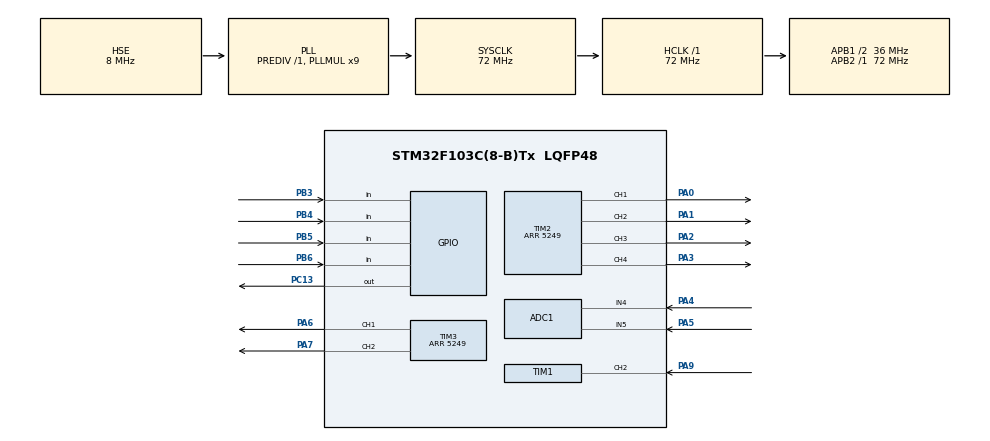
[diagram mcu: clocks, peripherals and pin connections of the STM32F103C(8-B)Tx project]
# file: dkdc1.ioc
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ADC1.Channel-0\#ChannelRegularConversion=ADC_CHANNEL_5
ADC1.NbrOfConversionFlag=1
ADC1.Rank-0\#ChannelRegularConversion=1
ADC1.SamplingTime-0\#ChannelRegularConversion=ADC_SAMPLETIME_55CYCLES_5
ADC1.master=1
Mcu.Family=STM32F1
Mcu.Name=STM32F103C(8-B)Tx
Mcu.Package=LQFP48
NVIC.PriorityGroup=NVIC_PRIORITYGROUP_4
NVIC.TIM3_IRQn=true\:0\:0\:false\:false\:true\:true\:true\:true
PA0-WKUP.Signal=S_TIM2_CH1_ETR
PA1.Signal=S_TIM2_CH2
PA13.Mode=Serial_Wire
PA13.Signal=SYS_JTMS-SWDIO
PA14.Mode=Serial_Wire
PA14.Signal=SYS_JTCK-SWCLK
PA2.Signal=S_TIM2_CH3
PA3.Signal=S_TIM2_CH4
PA4.Signal=ADCx_IN4
PA5.Signal=ADCx_IN5
PA6.Signal=S_TIM3_CH1
PA7.Signal=S_TIM3_CH2
PA9.Signal=S_TIM1_CH2
PB3.GPIO_PuPd=GPIO_PULLDOWN
PB3.Signal=GPIO_Input
PB4.GPIO_PuPd=GPIO_PULLDOWN
PB4.Signal=GPIO_Input
PB5.GPIO_PuPd=GPIO_PULLDOWN
PB5.Signal=GPIO_Input
PB6.GPIO_PuPd=GPIO_PULLDOWN
PB6.Signal=GPIO_Input
PC13-TAMPER-RTC.Signal=GPIO_Output
PD0-OSC_IN.Mode=HSE-External-Oscillator
PD0-OSC_IN.Signal=RCC_OSC_IN
PD1-OSC_OUT.Mode=HSE-External-Oscillator
PD1-OSC_OUT.Signal=RCC_OSC_OUT
ProjectManager.HeapSize=0x200
ProjectManager.StackSize=0x400
ProjectManager.TargetToolchain=MDK-ARM V5.32
RCC.ADCPresc=RCC_ADCPCLK2_DIV6
RCC.AHBFreq_Value=72000000
RCC.APB1CLKDivider=RCC_HCLK_DIV2
RCC.APB1Freq_Value=36000000
RCC.APB1TimFreq_Value=72000000
RCC.APB2Freq_Value=72000000
RCC.APB2TimFreq_Value=72000000
RCC.HCLKFreq_Value=72000000
RCC.PLLMUL=RCC_PLL_MUL9
RCC.PLLSourceVirtual=RCC_PLLSOURCE_HSE
RCC.SYSCLKFreq_VALUE=72000000
RCC.SYSCLKSource=RCC_SYSCLKSOURCE_PLLCLK
RCC.USBFreq_Value=72000000
SH.ADCx_IN4.0=ADC1_IN4,IN4
SH.ADCx_IN5.0=ADC1_IN5,IN5
SH.S_TIM1_CH2.0=TIM1_CH2,Input_Capture2_from_TI2
SH.S_TIM2_CH1_ETR.0=TIM2_CH1,PWM Generation1 CH1
SH.S_TIM2_CH2.0=TIM2_CH2,PWM Generation2 CH2
SH.S_TIM2_CH3.0=TIM2_CH3,PWM Generation3 CH3
SH.S_TIM2_CH4.0=TIM2_CH4,PWM Generation4 CH4
SH.S_TIM3_CH1.0=TIM3_CH1,PWM Generation1 CH1
SH.S_TIM3_CH2.0=TIM3_CH2,PWM Generation2 CH2
TIM1.Channel-Input_Capture2_from_TI2=TIM_CHANNEL_2
TIM1.Channel-PWM\ Generation1\ No\ Output=TIM_CHANNEL_1
TIM1.CounterMode=TIM_COUNTERMODE_CENTERALIGNED2
TIM1.Period=5249
TIM2.AutoReloadPreload=TIM_AUTORELOAD_PRELOAD_ENABLE
TIM2.Channel-PWM\ Generation1\ CH1=TIM_CHANNEL_1
TIM2.Channel-PWM\ Generation2\ CH2=TIM_CHANNEL_2
TIM2.Channel-PWM\ Generation3\ CH3=TIM_CHANNEL_3
TIM2.Channel-PWM\ Generation4\ CH4=TIM_CHANNEL_4
TIM2.CounterMode=TIM_COUNTERMODE_CENTERALIGNED1
TIM2.OCMode_PWM-PWM\ Generation2\ CH2=TIM_OCMODE_PWM2
TIM2.OCMode_PWM-PWM\ Generation4\ CH4=TIM_OCMODE_PWM2
TIM2.Period=5249
TIM2.TIM_MasterSlaveMode=TIM_MASTERSLAVEMODE_DISABLE
TIM3.AutoReloadPreload=TIM_AUTORELOAD_PRELOAD_ENABLE
TIM3.Channel-PWM\ Generation1\ CH1=TIM_CHANNEL_1
TIM3.Channel-PWM\ Generation2\ CH2=TIM_CHANNEL_2
TIM3.CounterMode=TIM_COUNTERMODE_CENTERALIGNED1
TIM3.OCMode_PWM-PWM\ Generation1\ CH1=TIM_OCMODE_PWM1
TIM3.OCMode_PWM-PWM\ Generation2\ CH2=TIM_OCMODE_PWM2
TIM3.Period=5249
VP_TIM1_VS_ClockSourceINT.Mode=Internal
VP_TIM1_VS_no_output1.Mode=PWM Generation1 No Output
VP_TIM2_VS_ClockSourceITR.Mode=TriggerSource_ITR0
VP_TIM2_VS_ControllerModeTrigger.Mode=Trigger Mode
VP_TIM3_VS_ClockSourceITR.Mode=TriggerSource_ITR0
VP_TIM3_VS_ControllerModeTrigger.Mode=Trigger Mode
board=custom

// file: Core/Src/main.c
/* USER CODE BEGIN Header */
/**
  ******************************************************************************
  * @file           : main.c
  * @brief          : Main program body
  ******************************************************************************
  * @attention
  *
  * Copyright (c) 2025 STMicroelectronics.
  * All rights reserved.
  *
  * This software is licensed under terms that can be found in the LICENSE file
  * in the root directory of this software component.
  * If no LICENSE file comes with this software, it is provided AS-IS.
  *
  ******************************************************************************
  */
/* USER CODE END Header */
#include "main.h"

ADC_HandleTypeDef hadc1;

TIM_HandleTypeDef htim1;
TIM_HandleTypeDef htim2;
TIM_HandleTypeDef htim3;

/* USER CODE BEGIN PV */
//#define GIATRI 1600
//#define FM 16000 // 8000x2
/* USER CODE END PV */

void SystemClock_Config(void);
static void MX_GPIO_Init(void);
static void MX_ADC1_Init(void);
static void MX_TIM2_Init(void);
static void MX_TIM3_Init(void);
static void MX_TIM1_Init(void);

/* USER CODE BEGIN 0 */
volatile uint16_t numberS=0;

uint16_t i0=0,a=0,b=0,c=0,d=0;
uint16_t seclect, check_adc, luuadc, step;
uint16_t ADC_Sensor;
uint16_t zero3200[3200] = {0, 0, 0, 0, 0, 0, 0, 0, 0, 0, 0, 0, 0, 0, 0, 0, 0, 0, 0, 0,
0, 0, 0, 0, 0, 0, 0, 0, 0, 0, 0, 0, 0, 0, 0, 0, 0, 0, 0, 0,
0, 0, 0, 0, 0, 0, 0, 0, 0, 0, 0, 0, 0, 0, 0, 0, 0, 0, 0, 0,
0, 0, 0, 0, 0, 0, 0, 0, 0, 0, 0, 0, 0, 0, 0, 0, 0, 0, 0, 0,
0, 0, 0, 0, 0, 0, 0, 0, 0, 0, 0, 0, 0, 0, 0, 0, 0, 0, 0, 0,
0, 0, 0, 0, 0, 0, 0, 0, 0, 0, 0, 0, 0, 0, 0, 0, 0, 0, 0, 0,
0, 0, 0, 0, 0, 0, 0, 0, 0, 0, 0, 0, 0, 0, 0, 0, 0, 0, 0, 0,
0, 0, 0, 0, 0, 0, 0, 0, 0, 0, 0, 0, 0, 0, 0, 0, 0, 0, 0, 0,
0, 0, 0, 0, 0, 0, 0, 0, 0, 0, 0, 0, 0, 0, 0, 0, 0, 0, 0, 0,
0, 0, 0, 0, 0, 0, 0, 0, 0, 0, 0, 0, 0, 0, 0, 0, 0, 0, 0, 0,
0, 0, 0, 0, 0, 0, 0, 0, 0, 0, 0, 0, 0, 0, 0, 0, 0, 0, 0, 0,
0, 0, 0, 0, 0, 0, 0, 0, 0, 0, 0, 0, 0, 0, 0, 0, 0, 0, 0, 0,
0, 0, 0, 0, 0, 0, 0, 0, 0, 0, 0, 0, 0, 0, 0, 0, 0, 0, 0, 0,
0, 0, 0, 0, 0, 0, 0, 0, 0, 0, 0, 0, 0, 0, 0, 0, 0, 0, 0, 0,
0, 0, 0, 0, 0, 0, 0, 0, 0, 0, 0, 0, 0, 0, 0, 0, 0, 0, 0, 0,
0, 0, 0, 0, 0, 0, 0, 0, 0, 0, 0, 0, 0, 0, 0, 0, 0, 0, 0, 0, 0, 0, 0, 0, 0, 0, 0, 0, 0, 0, 0, 0, 0, 0, 0, 0, 0, 0, 0, 0,
0, 0, 0, 0, 0, 0, 0, 0, 0, 0, 0, 0, 0, 0, 0, 0, 0, 0, 0, 0,
0, 0, 0, 0, 0, 0, 0, 0, 0, 0, 0, 0, 0, 0, 0, 0, 0, 0, 0, 0,
0, 0, 0, 0, 0, 0, 0, 0, 0, 0, 0, 0, 0, 0, 0, 0, 0, 0, 0, 0,
0, 0, 0, 0, 0, 0, 0, 0, 0, 0, 0, 0, 0, 0, 0, 0, 0, 0, 0, 0,
0, 0, 0, 0, 0, 0, 0, 0, 0, 0, 0, 0, 0, 0, 0, 0, 0, 0, 0, 0,
0, 0, 0, 0, 0, 0, 0, 0, 0, 0, 0, 0, 0, 0, 0, 0, 0, 0, 0, 0,
0, 0, 0, 0, 0, 0, 0, 0, 0, 0, 0, 0, 0, 0, 0, 0, 0, 0, 0, 0,
0, 0, 0, 0, 0, 0, 0, 0, 0, 0, 0, 0, 0, 0, 0, 0, 0, 0, 0, 0,
0, 0, 0, 0, 0, 0, 0, 0, 0, 0, 0, 0, 0, 0, 0, 0, 0, 0, 0, 0,
0, 0, 0, 0, 0, 0, 0, 0, 0, 0, 0, 0, 0, 0, 0, 0, 0, 0, 0, 0,
0, 0, 0, 0, 0, 0, 0, 0, 0, 0, 0, 0, 0, 0, 0, 0, 0, 0, 0, 0,
0, 0, 0, 0, 0, 0, 0, 0, 0, 0, 0, 0, 0, 0, 0, 0, 0, 0, 0, 0,
0, 0, 0, 0, 0, 0, 0, 0, 0, 0, 0, 0, 0, 0, 0, 0, 0, 0, 0, 0,
0, 0, 0, 0, 0, 0, 0, 0, 0, 0, 0, 0, 0, 0, 0, 0, 0, 0, 0, 0,
0, 0, 0, 0, 0, 0, 0, 0, 0, 0, 0, 0, 0, 0, 0, 0, 0, 0, 0, 0,
0, 0, 0, 0, 0, 0, 0, 0, 0, 0, 0, 0, 0, 0, 0, 0, 0, 0, 0, 0,
0, 0, 0, 0, 0, 0, 0, 0, 0, 0, 0, 0, 0, 0, 0, 0, 0, 0, 0, 0,
0, 0, 0, 0, 0, 0, 0, 0, 0, 0, 0, 0, 0, 0, 0, 0, 0, 0, 0, 0,
0, 0, 0, 0, 0, 0, 0, 0, 0, 0, 0, 0, 0, 0, 0, 0, 0, 0, 0, 0,
0, 0, 0, 0, 0, 0, 0, 0, 0, 0, 0, 0, 0, 0, 0, 0, 0, 0, 0, 0,
0, 0, 0, 0, 0, 0, 0, 0, 0, 0, 0, 0, 0, 0, 0, 0, 0, 0, 0, 0,
0, 0, 0, 0, 0, 0, 0, 0, 0, 0, 0, 0, 0, 0, 0, 0, 0, 0, 0, 0,
0, 0, 0, 0, 0, 0, 0, 0, 0, 0, 0, 0, 0, 0, 0, 0, 0, 0, 0, 0,
0, 0, 0, 0, 0, 0, 0, 0, 0, 0, 0, 0, 0, 0, 0, 0, 0, 0, 0, 0,
0, 0, 0, 0, 0, 0, 0, 0, 0, 0, 0, 0, 0, 0, 0, 0, 0, 0, 0, 0,
0, 0, 0, 0, 0, 0, 0, 0, 0, 0, 0, 0, 0, 0, 0, 0, 0, 0, 0, 0,
0, 0, 0, 0, 0, 0, 0, 0, 0, 0, 0, 0, 0, 0, 0, 0, 0, 0, 0, 0,
0, 0, 0, 0, 0, 0, 0, 0, 0, 0, 0, 0, 0, 0, 0, 0, 0, 0, 0, 0,
0, 0, 0, 0, 0, 0, 0, 0, 0, 0, 0, 0, 0, 0, 0, 0, 0, 0, 0, 0,
0, 0, 0, 0, 0, 0, 0, 0, 0, 0, 0, 0, 0, 0, 0, 0, 0, 0, 0, 0,
0, 0, 0, 0, 0, 0, 0, 0, 0, 0, 0, 0, 0, 0, 0, 0, 0, 0, 0, 0, 0, 0, 0, 0, 0, 0, 0, 0, 0, 0, 0, 0, 0, 0, 0, 0, 0, 0, 0, 0,
0, 0, 0, 0, 0, 0, 0, 0, 0, 0, 0, 0, 0, 0, 0, 0, 0, 0, 0, 0,
0, 0, 0, 0, 0, 0, 0, 0, 0, 0, 0, 0, 0, 0, 0, 0, 0, 0, 0, 0,
0, 0, 0, 0, 0, 0, 0, 0, 0, 0, 0, 0, 0, 0, 0, 0, 0, 0, 0, 0,
0, 0, 0, 0, 0, 0, 0, 0, 0, 0, 0, 0, 0, 0, 0, 0, 0, 0, 0, 0,
0, 0, 0, 0, 0, 0, 0, 0, 0, 0, 0, 0, 0, 0, 0, 0, 0, 0, 0, 0,
0, 0, 0, 0, 0, 0, 0, 0, 0, 0, 0, 0, 0, 0, 0, 0, 0, 0, 0, 0,
0, 0, 0, 0, 0, 0, 0, 0, 0, 0, 0, 0, 0, 0, 0, 0, 0, 0, 0, 0,
0, 0, 0, 0, 0, 0, 0, 0, 0, 0, 0, 0, 0, 0, 0, 0, 0, 0, 0, 0,
0, 0, 0, 0, 0, 0, 0, 0, 0, 0, 0, 0, 0, 0, 0, 0, 0, 0, 0, 0,
0, 0, 0, 0, 0, 0, 0, 0, 0, 0, 0, 0, 0, 0, 0, 0, 0, 0, 0, 0,
0, 0, 0, 0, 0, 0, 0, 0, 0, 0, 0, 0, 0, 0, 0, 0, 0, 0, 0, 0,
0, 0, 0, 0, 0, 0, 0, 0, 0, 0, 0, 0, 0, 0, 0, 0, 0, 0, 0, 0,
0, 0, 0, 0, 0, 0, 0, 0, 0, 0, 0, 0, 0, 0, 0, 0, 0, 0, 0, 0,
0, 0, 0, 0, 0, 0, 0, 0, 0, 0, 0, 0, 0, 0, 0, 0, 0, 0, 0, 0,
0, 0, 0, 0, 0, 0, 0, 0, 0, 0, 0, 0, 0, 0, 0, 0, 0, 0, 0, 0,
0, 0, 0, 0, 0, 0, 0, 0, 0, 0, 0, 0, 0, 0, 0, 0, 0, 0, 0, 0,
0, 0, 0, 0, 0, 0, 0, 0, 0, 0, 0, 0, 0, 0, 0, 0, 0, 0, 0, 0,
0, 0, 0, 0, 0, 0, 0, 0, 0, 0, 0, 0, 0, 0, 0, 0, 0, 0, 0, 0,
0, 0, 0, 0, 0, 0, 0, 0, 0, 0, 0, 0, 0, 0, 0, 0, 0, 0, 0, 0,
0, 0, 0, 0, 0, 0, 0, 0, 0, 0, 0, 0, 0, 0, 0, 0, 0, 0, 0, 0,
0, 0, 0, 0, 0, 0, 0, 0, 0, 0, 0, 0, 0, 0, 0, 0, 0, 0, 0, 0,
0, 0, 0, 0, 0, 0, 0, 0, 0, 0, 0, 0, 0, 0, 0, 0, 0, 0, 0, 0,
0, 0, 0, 0, 0, 0, 0, 0, 0, 0, 0, 0, 0, 0, 0, 0, 0, 0, 0, 0,
0, 0, 0, 0, 0, 0, 0, 0, 0, 0, 0, 0, 0, 0, 0, 0, 0, 0, 0, 0,
0, 0, 0, 0, 0, 0, 0, 0, 0, 0, 0, 0, 0, 0, 0, 0, 0, 0, 0, 0,
0, 0, 0, 0, 0, 0, 0, 0, 0, 0, 0, 0, 0, 0, 0, 0, 0, 0, 0, 0,
0, 0, 0, 0, 0, 0, 0, 0, 0, 0, 0, 0, 0, 0, 0, 0, 0, 0, 0, 0,
0, 0, 0, 0, 0, 0, 0, 0, 0, 0, 0, 0, 0, 0, 0, 0, 0, 0, 0, 0,
0, 0, 0, 0, 0, 0, 0, 0, 0, 0, 0, 0, 0, 0, 0, 0, 0, 0, 0, 0,
0, 0, 0, 0, 0, 0, 0, 0, 0, 0, 0, 0, 0, 0, 0, 0, 0, 0, 0, 0,
0, 0, 0, 0, 0, 0, 0, 0, 0, 0, 0, 0, 0, 0, 0, 0, 0, 0, 0,
0, 0, 0, 0, 0, 0, 0, 0, 0, 0, 0, 0, 0, 0, 0, 0, 0, 0, 0, 0,
0, 0, 0, 0, 0, 0, 0, 0, 0, 0, 0, 0, 0, 0, 0, 0, 0, 0, 0, 0,
0, 0, 0, 0, 0, 0, 0, 0, 0, 0, 0, 0, 0, 0, 0, 0, 0, 0, 0, 0,
0, 0, 0, 0, 0, 0, 0, 0, 0, 0, 0, 0, 0, 0, 0, 0, 0, 0, 0, 0,
0, 0, 0, 0, 0, 0, 0, 0, 0, 0, 0, 0, 0, 0, 0, 0, 0, 0, 0, 0,
0, 0, 0, 0, 0, 0, 0, 0, 0, 0, 0, 0, 0, 0, 0, 0, 0, 0, 0, 0,
0, 0, 0, 0, 0, 0, 0, 0, 0, 0, 0, 0, 0, 0, 0, 0, 0, 0, 0, 0,
0, 0, 0, 0, 0, 0, 0, 0, 0, 0, 0, 0, 0, 0, 0, 0, 0, 0, 0, 0,
0, 0, 0, 0, 0, 0, 0, 0, 0, 0, 0, 0, 0, 0, 0, 0, 0, 0, 0, 0,
0, 0, 0, 0, 0, 0, 0, 0, 0, 0, 0, 0, 0, 0, 0, 0, 0, 0, 0, 0,
0, 0, 0, 0, 0, 0, 0, 0, 0, 0, 0, 0, 0, 0, 0, 0, 0, 0, 0, 0,
0, 0, 0, 0, 0, 0, 0, 0, 0, 0, 0, 0, 0, 0, 0, 0, 0, 0, 0, 0,
0, 0, 0, 0, 0, 0, 0, 0, 0, 0, 0, 0, 0, 0, 0, 0, 0, 0, 0, 0,
0, 0, 0, 0, 0, 0, 0, 0, 0, 0, 0, 0, 0, 0, 0, 0, 0, 0, 0, 0,
0, 0, 0, 0, 0, 0, 0, 0, 0, 0, 0, 0, 0, 0, 0, 0, 0, 0, 0, 0,
0, 0, 0, 0, 0, 0, 0, 0, 0, 0, 0, 0, 0, 0, 0, 0, 0, 0, 0, 0, 0, 0, 0, 0, 0, 0, 0, 0, 0, 0, 0, 0, 0, 0, 0, 0, 0, 0, 0, 0,
0, 0, 0, 0, 0, 0, 0, 0, 0, 0, 0, 0, 0, 0, 0, 0, 0, 0, 0, 0,
0, 0, 0, 0, 0, 0, 0, 0, 0, 0, 0, 0, 0, 0, 0, 0, 0, 0, 0, 0,
0, 0, 0, 0, 0, 0, 0, 0, 0, 0, 0, 0, 0, 0, 0, 0, 0, 0, 0, 0,
0, 0, 0, 0, 0, 0, 0, 0, 0, 0, 0, 0, 0, 0, 0, 0, 0, 0, 0, 0,
0, 0, 0, 0, 0, 0, 0, 0, 0, 0, 0, 0, 0, 0, 0, 0, 0, 0, 0, 0,
0, 0, 0, 0, 0, 0, 0, 0, 0, 0, 0, 0, 0, 0, 0, 0, 0, 0, 0, 0,
0, 0, 0, 0, 0, 0, 0, 0, 0, 0, 0, 0, 0, 0, 0, 0, 0, 0, 0, 0,
0, 0, 0, 0, 0, 0, 0, 0, 0, 0, 0, 0, 0, 0, 0, 0, 0, 0, 0, 0,
0, 0, 0, 0, 0, 0, 0, 0, 0, 0, 0, 0, 0, 0, 0, 0, 0, 0, 0, 0,
0, 0, 0, 0, 0, 0, 0, 0, 0, 0, 0, 0, 0, 0, 0, 0, 0, 0, 0, 0,
0, 0, 0, 0, 0, 0, 0, 0, 0, 0, 0, 0, 0, 0, 0, 0, 0, 0, 0, 0,
0, 0, 0, 0, 0, 0, 0, 0, 0, 0, 0, 0, 0, 0, 0, 0, 0, 0, 0, 0,
0, 0, 0, 0, 0, 0, 0, 0, 0, 0, 0, 0, 0, 0, 0, 0, 0, 0, 0, 0,
0, 0, 0, 0, 0, 0, 0, 0, 0, 0, 0, 0, 0, 0, 0, 0, 0, 0, 0, 0,
0, 0, 0, 0, 0, 0, 0, 0, 0, 0, 0, 0, 0, 0, 0, 0, 0, 0, 0, 0,
0, 0, 0, 0, 0, 0, 0, 0, 0, 0, 0, 0, 0, 0, 0, 0, 0, 0, 0, 0,
0, 0, 0, 0, 0, 0, 0, 0, 0, 0, 0, 0, 0, 0, 0, 0, 0, 0, 0, 0,
0, 0, 0, 0, 0, 0, 0, 0, 0, 0, 0, 0, 0, 0, 0, 0, 0, 0, 0, 0,
0, 0, 0, 0, 0, 0, 0, 0, 0, 0, 0, 0, 0, 0, 0, 0, 0, 0, 0, 0,
0, 0, 0, 0, 0, 0, 0, 0, 0, 0, 0, 0, 0, 0, 0, 0, 0, 0, 0, 0,
0, 0, 0, 0, 0, 0, 0, 0, 0, 0, 0, 0, 0, 0, 0, 0, 0, 0, 0, 0,
0, 0, 0, 0, 0, 0, 0, 0, 0, 0, 0, 0, 0, 0, 0, 0, 0, 0, 0, 0,
0, 0, 0, 0, 0, 0, 0, 0, 0, 0, 0, 0, 0, 0, 0, 0, 0, 0, 0, 0,
0, 0, 0, 0, 0, 0, 0, 0, 0, 0, 0, 0, 0, 0, 0, 0, 0, 0, 0, 0,
0, 0, 0, 0, 0, 0, 0, 0, 0, 0, 0, 0, 0, 0, 0, 0, 0, 0, 0, 0,
0, 0, 0, 0, 0, 0, 0, 0, 0, 0, 0, 0, 0, 0, 0, 0, 0, 0, 0, 0,
0, 0, 0, 0, 0, 0, 0, 0, 0, 0, 0, 0, 0, 0, 0, 0, 0, 0, 0, 0,
0, 0, 0, 0, 0, 0, 0, 0, 0, 0, 0, 0, 0, 0, 0, 0, 0, 0, 0, 0,
0, 0, 0, 0, 0, 0, 0, 0, 0, 0, 0, 0, 0, 0, 0, 0, 0, 0, 0, 0,
0, 0, 0, 0, 0, 0, 0, 0, 0, 0, 0, 0, 0, 0, 0, 0, 0, 0, 0, 0,
0, 0, 0, 0, 0, 0, 0, 0, 0, 0, 0, 0, 0, 0, 0, 0, 0, 0, 0, 0, 0, 0, 0, 0, 0, 0, 0, 0, 0, 0, 0, 0, 0, 0, 0, 0, 0, 0, 0, 0,
0, 0, 0, 0, 0, 0, 0, 0, 0, 0, 0, 0, 0, 0, 0, 0, 0, 0, 0, 0,
0, 0, 0, 0, 0, 0, 0, 0, 0, 0, 0, 0, 0, 0, 0, 0, 0, 0, 0, 0,
0, 0, 0, 0, 0, 0, 0, 0, 0, 0, 0, 0, 0, 0, 0, 0, 0, 0, 0, 0,
0, 0, 0, 0, 0, 0, 0, 0, 0, 0, 0, 0, 0, 0, 0, 0, 0, 0, 0, 0,
0, 0, 0, 0, 0, 0, 0, 0, 0, 0, 0, 0, 0, 0, 0, 0, 0, 0, 0, 0,
0, 0, 0, 0, 0, 0, 0, 0, 0, 0, 0, 0, 0, 0, 0, 0, 0, 0, 0, 0,
0, 0, 0, 0, 0, 0, 0, 0, 0, 0, 0, 0, 0, 0, 0, 0, 0, 0, 0, 0,
0, 0, 0, 0, 0, 0, 0, 0, 0, 0, 0, 0, 0, 0, 0, 0, 0, 0, 0, 0,
0, 0, 0, 0, 0, 0, 0, 0, 0, 0, 0, 0, 0, 0, 0, 0, 0, 0, 0, 0,
0, 0, 0, 0, 0, 0, 0, 0, 0, 0, 0, 0, 0, 0, 0, 0, 0, 0, 0, 0,
0, 0, 0, 0, 0, 0, 0, 0, 0, 0, 0, 0, 0, 0, 0, 0, 0, 0, 0, 0,
0, 0, 0, 0, 0, 0, 0, 0, 0, 0, 0, 0, 0, 0, 0, 0, 0, 0, 0, 0,
0, 0, 0, 0, 0, 0, 0, 0, 0, 0, 0, 0, 0, 0, 0, 0, 0, 0, 0, 0,
0, 0, 0, 0, 0, 0, 0, 0, 0, 0, 0, 0, 0, 0, 0, 0, 0, 0, 0, 0,
0, 0, 0, 0, 0, 0, 0, 0, 0, 0, 0, 0, 0, 0, 0, 0, 0, 0, 0, 0,
0, 0, 0, 0, 0, 0, 0, 0, 0, 0, 0, 0, 0, 0, 0, 0, 0, 0, 0, 0,
0, 0, 0, 0, 0, 0, 0, 0, 0, 0, 0, 0, 0, 0, 0, 0, 0, 0, 0, 0,
0, 0, 0, 0, 0, 0, 0, 0, 0, 0, 0, 0, 0, 0, 0, 0, 0, 0, 0, 0,
0, 0, 0, 0, 0, 0, 0, 0, 0, 0, 0, 0, 0, 0, 0, 0, 0, 0, 0, 0,
0, 0, 0, 0, 0, 0, 0, 0, 0, 0, 0, 0, 0, 0, 0, 0, 0, 0, 0, 0,
0, 0, 0, 0, 0, 0, 0, 0, 0, 0, 0, 0, 0, 0, 0, 0, 0, 0, 0, 0,
0, 0, 0, 0, 0, 0, 0, 0, 0, 0, 0, 0, 0, 0, 0, 0, 0, 0, 0, 0,
0, 0, 0, 0, 0, 0, 0, 0, 0, 0, 0, 0, 0, 0, 0, 0, 0, 0, 0, 0,
0, 0, 0, 0, 0, 0, 0, 0, 0, 0, 0, 0, 0, 0, 0, 0, 0, 0, 0, 0,
0, 0, 0, 0, 0, 0, 0, 0, 0, 0, 0, 0, 0, 0, 0, 0, 0, 0, 0, 0,
0, 0, 0, 0, 0, 0, 0, 0, 0, 0, 0, 0, 0, 0, 0, 0, 0, 0, 0, 0,
0, 0, 0, 0, 0, 0, 0, 0, 0, 0, 0, 0, 0, 0, 0, 0, 0, 0, 0, 0,
0, 0, 0, 0, 0, 0, 0, 0, 0, 0, 0, 0, 0, 0, 0, 0, 0, 0, 0, 0,
0, 0, 0, 0, 0, 0, 0, 0, 0, 0, 0, 0, 0, 0, 0, 0, 0, 0, 0, 0,
0, 0, 0, 0, 0, 0, 0, 0, 0, 0, 0, 0, 0, 0, 0, 0, 0, 0, 0, 0,
0, 0, 0, 0, 0, 0, 0, 0, 0, 0, 0, 0, 0, 0, 0, 0, 0, 0, 0, 0};

const uint16_t bangX1_5Hz[3200]={0, 9, 18, 27, 35, 44, 53, 62, 71, 80, 88, 97, 106, 115, 124, 133, 141, 150, 159, 168,
177, 186, 194, 203, 212, 221, 230, 239, 247, 256, 265, 274, 283, 291, 300, 309, 318, 327, 336, 344,
353, 362, 371, 380, 388, 397, 406, 415, 424, 432, 441, 450, 459, 468, 476, 485, 494, 503, 512, 520,
529, 538, 547, 555, 564, 573, 582, 590, 599, 608, 617, 626, 634, 643, 652, 660, 669, 678, 687, 695,
704, 713, 722, 730, 739, 748, 757, 765, 774, 783, 791, 800, 809, 817, 826, 835, 843, 852, 861, 870,
878, 887, 896, 904, 913, 921, 930, 939, 947, 956, 965, 973, 982, 991, 999, 1008, 1016, 1025, 1034, 1042,
1051, 1059, 1068, 1077, 1085, 1094, 1102, 1111, 1119, 1128, 1137, 1145, 1154, 1162, 1171, 1179, 1188, 1196, 1205, 1213,
1222, 1230, 1239, 1247, 1256, 1264, 1273, 1281, 1290, 1298, 1307, 1315, 1324, 1332, 1340, 1349, 1357, 1366, 1374, 1383,
1391, 1399, 1408, 1416, 1425, 1433, 1441, 1450, 1458, 1466, 1475, 1483, 1491, 1500, 1508, 1516, 1525, 1533, 1541, 1550,
1558, 1566, 1575, 1583, 1591, 1599, 1608, 1616, 1624, 1632, 1641, 1649, 1657, 1665, 1673, 1682, 1690, 1698, 1706, 1714,
1723, 1731, 1739, 1747, 1755, 1763, 1771, 1780, 1788, 1796, 1804, 1812, 1820, 1828, 1836, 1844, 1852, 1860, 1868, 1876,
1885, 1893, 1901, 1909, 1917, 1925, 1933, 1941, 1948, 1956, 1964, 1972, 1980, 1988, 1996, 2004, 2012, 2020, 2028, 2036,
2044, 2051, 2059, 2067, 2075, 2083, 2091, 2098, 2106, 2114, 2122, 2130, 2137, 2145, 2153, 2161, 2169, 2176, 2184, 2192,
2199, 2207, 2215, 2223, 2230, 2238, 2246, 2253, 2261, 2268, 2276, 2284, 2291, 2299, 2307, 2314, 2322, 2329, 2337, 2344,
2352, 2359, 2367, 2374, 2382, 2389, 2397, 2404, 2412, 2419, 2427, 2434, 2442, 2449, 2456, 2464, 2471, 2479, 2486, 2493,
2501, 2508, 2515, 2523, 2530, 2537, 2545, 2552, 2559, 2566, 2574, 2581, 2588, 2595, 2603, 2610, 2617, 2624, 2631, 2639,
2646, 2653, 2660, 2667, 2674, 2681, 2688, 2696, 2703, 2710, 2717, 2724, 2731, 2738, 2745, 2752, 2759, 2766, 2773, 2780,
2787, 2794, 2801, 2807, 2814, 2821, 2828, 2835, 2842, 2849, 2856, 2862, 2869, 2876, 2883, 2890, 2896, 2903, 2910, 2917,
2923, 2930, 2937, 2943, 2950, 2957, 2963, 2970, 2977, 2983, 2990, 2996, 3003, 3010, 3016, 3023, 3029, 3036, 3042, 3049,
3055, 3062, 3068, 3075, 3081, 3088, 3094, 3101, 3107, 3113, 3120, 3126, 3132, 3139, 3145, 3151, 3158, 3164, 3170, 3177,
3183, 3189, 3195, 3201, 3208, 3214, 3220, 3226, 3232, 3238, 3245, 3251, 3257, 3263, 3269, 3275, 3281, 3287, 3293, 3299,
3305, 3311, 3317, 3323, 3329, 3335, 3341, 3347, 3353, 3359, 3365, 3370, 3376, 3382, 3388, 3394, 3400, 3405, 3411, 3417,
3423, 3428, 3434, 3440, 3445, 3451, 3457, 3462, 3468, 3474, 3479, 3485, 3491, 3496, 3502, 3507, 3513, 3518, 3524, 3529,
3535, 3540, 3546, 3551, 3556, 3562, 3567, 3573, 3578, 3583, 3589, 3594, 3599, 3605, 3610, 3615, 3620, 3626, 3631, 3636,
3641, 3647, 3652, 3657, 3662, 3667, 3672, 3677, 3682, 3688, 3693, 3698, 3703, 3708, 3713, 3718, 3723, 3728, 3733, 3737,
3742, 3747, 3752, 3757, 3762, 3767, 3772, 3776, 3781, 3786, 3791, 3795, 3800, 3805, 3810, 3814, 3819, 3824, 3828, 3833,
3838, 3842, 3847, 3851, 3856, 3861, 3865, 3870, 3874, 3879, 3883, 3888, 3892, 3896, 3901, 3905, 3910, 3914, 3918, 3923,
3927, 3931, 3936, 3940, 3944, 3948, 3953, 3957, 3961, 3965, 3969, 3974, 3978, 3982, 3986, 3990, 3994, 3998, 4002, 4006,
4010, 4014, 4018, 4022, 4026, 4030, 4034, 4038, 4042, 4046, 4050, 4053, 4057, 4061, 4065, 4069, 4072, 4076, 4080, 4084,
4087, 4091, 4095, 4098, 4102, 4106, 4109, 4113, 4116, 4120, 4123, 4127, 4131, 4134, 4138, 4141, 4144, 4148, 4151, 4155,
4158, 4161, 4165, 4168, 4171, 4175, 4178, 4181, 4185, 4188, 4191, 4194, 4197, 4201, 4204, 4207, 4210, 4213, 4216, 4219,
4222, 4226, 4229, 4232, 4235, 4238, 4240, 4243, 4246, 4249, 4252, 4255, 4258, 4261, 4264, 4266, 4269, 4272, 4275, 4278,
4280, 4283, 4286, 4288, 4291, 4294, 4296, 4299, 4302, 4304, 4307, 4309, 4312, 4314, 4317, 4319, 4322, 4324, 4327, 4329,
4332, 4334, 4336, 4339, 4341, 4343, 4346, 4348, 4350, 4352, 4355, 4357, 4359, 4361, 4363, 4366, 4368, 4370, 4372, 4374,
4376, 4378, 4380, 4382, 4384, 4386, 4388, 4390, 4392, 4394, 4396, 4398, 4400, 4401, 4403, 4405, 4407, 4409, 4410, 4412,
4414, 4416, 4417, 4419, 4421, 4422, 4424, 4426, 4427, 4429, 4430, 4432, 4433, 4435, 4436, 4438, 4439, 4441, 4442, 4444,
4445, 4446, 4448, 4449, 4450, 4452, 4453, 4454, 4455, 4457, 4458, 4459, 4460, 4461, 4463, 4464, 4465, 4466, 4467, 4468,
4469, 4470, 4471, 4472, 4473, 4474, 4475, 4476, 4477, 4478, 4479, 4479, 4480, 4481, 4482, 4483, 4483, 4484, 4485, 4486,
4486, 4487, 4488, 4488, 4489, 4490, 4490, 4491, 4491, 4492, 4492, 4493, 4493, 4494, 4494, 4495, 4495, 4496, 4496, 4496,
4497, 4497, 4497, 4498, 4498, 4498, 4498, 4499, 4499, 4499, 4499, 4499, 4499, 4500, 4500, 4500, 4500, 4500, 4500, 4500,
4500, 4500, 4500, 4500, 4500, 4500, 4500, 4500, 4499, 4499, 4499, 4499, 4499, 4498, 4498, 4498, 4498, 4497, 4497, 4497,
4496, 4496, 4496, 4495, 4495, 4494, 4494, 4494, 4493, 4493, 4492, 4492, 4491, 4490, 4490, 4489, 4489, 4488, 4487, 4487,
4486, 4485, 4485, 4484, 4483, 4482, 4481, 4481, 4480, 4479, 4478, 4477, 4476, 4475, 4474, 4474, 4473, 4472, 4471, 4470,
4469, 4467, 4466, 4465, 4464, 4463, 4462, 4461, 4460, 4458, 4457, 4456, 4455, 4454, 4452, 4451, 4450, 4448, 4447, 4446,
4444, 4443, 4441, 4440, 4439, 4437, 4436, 4434, 4433, 4431, 4429, 4428, 4426, 4425, 4423, 4421, 4420, 4418, 4416, 4415,
4413, 4411, 4410, 4408, 4406, 4404, 4402, 4401, 4399, 4397, 4395, 4393, 4391, 4389, 4387, 4385, 4383, 4381, 4379, 4377,
4375, 4373, 4371, 4369, 4367, 4365, 4362, 4360, 4358, 4356, 4354, 4351, 4349, 4347, 4344, 4342, 4340, 4337, 4335, 4333,
4330, 4328, 4326, 4323, 4321, 4318, 4316, 4313, 4311, 4308, 4305, 4303, 4300, 4298, 4295, 4292, 4290, 4287, 4284, 4282,
4279, 4276, 4273, 4271, 4268, 4265, 4262, 4259, 4257, 4254, 4251, 4248, 4245, 4242, 4239, 4236, 4233, 4230, 4227, 4224,
4221, 4218, 4215, 4212, 4209, 4205, 4202, 4199, 4196, 4193, 4189, 4186, 4183, 4180, 4176, 4173, 4170, 4166, 4163, 4160,
4156, 4153, 4150, 4146, 4143, 4139, 4136, 4132, 4129, 4125, 4122, 4118, 4115, 4111, 4107, 4104, 4100, 4097, 4093, 4089,
4085, 4082, 4078, 4074, 4071, 4067, 4063, 4059, 4055, 4051, 4048, 4044, 4040, 4036, 4032, 4028, 4024, 4020, 4016, 4012,
4008, 4004, 4000, 3996, 3992, 3988, 3984, 3980, 3976, 3971, 3967, 3963, 3959, 3955, 3950, 3946, 3942, 3938, 3933, 3929,
3925, 3920, 3916, 3912, 3907, 3903, 3899, 3894, 3890, 3885, 3881, 3876, 3872, 3867, 3863, 3858, 3854, 3849, 3845, 3840,
3835, 3831, 3826, 3821, 3817, 3812, 3807, 3803, 3798, 3793, 3788, 3784, 3779, 3774, 3769, 3764, 3759, 3755, 3750, 3745,
3740, 3735, 3730, 3725, 3720, 3715, 3710, 3705, 3700, 3695, 3690, 3685, 3680, 3675, 3670, 3665, 3659, 3654, 3649, 3644,
3639, 3634, 3628, 3623, 3618, 3613, 3607, 3602, 3597, 3591, 3586, 3581, 3575, 3570, 3565, 3559, 3554, 3548, 3543, 3537,
3532, 3526, 3521, 3515, 3510, 3504, 3499, 3493, 3488, 3482, 3477, 3471, 3465, 3460, 3454, 3448, 3443, 3437, 3431, 3425,
3420, 3414, 3408, 3402, 3397, 3391, 3385, 3379, 3373, 3368, 3362, 3356, 3350, 3344, 3338, 3332, 3326, 3320, 3314, 3308,
3302, 3296, 3290, 3284, 3278, 3272, 3266, 3260, 3254, 3248, 3242, 3235, 3229, 3223, 3217, 3211, 3205, 3198, 3192, 3186,
3180, 3173, 3167, 3161, 3155, 3148, 3142, 3136, 3129, 3123, 3116, 3110, 3104, 3097, 3091, 3084, 3078, 3072, 3065, 3059,
3052, 3046, 3039, 3033, 3026, 3020, 3013, 3006, 3000, 2993, 2987, 2980, 2973, 2967, 2960, 2953, 2947, 2940, 2933, 2927,
2920, 2913, 2906, 2900, 2893, 2886, 2879, 2873, 2866, 2859, 2852, 2845, 2838, 2832, 2825, 2818, 2811, 2804, 2797, 2790,
2783, 2776, 2769, 2762, 2755, 2748, 2741, 2734, 2727, 2720, 2713, 2706, 2699, 2692, 2685, 2678, 2671, 2664, 2656, 2649,
2642, 2635, 2628, 2621, 2613, 2606, 2599, 2592, 2585, 2577, 2570, 2563, 2556, 2548, 2541, 2534, 2526, 2519, 2512, 2504,
2497, 2490, 2482, 2475, 2468, 2460, 2453, 2445, 2438, 2431, 2423, 2416, 2408, 2401, 2393, 2386, 2378, 2371, 2363, 2356,
2348, 2341, 2333, 2325, 2318, 2310, 2303, 2295, 2288, 2280, 2272, 2265, 2257, 2249, 2242, 2234, 2226, 2219, 2211, 2203,
2196, 2188, 2180, 2172, 2165, 2157, 2149, 2141, 2134, 2126, 2118, 2110, 2102, 2095, 2087, 2079, 2071, 2063, 2055, 2047,
2040, 2032, 2024, 2016, 2008, 2000, 1992, 1984, 1976, 1968, 1960, 1952, 1945, 1937, 1929, 1921, 1913, 1905, 1897, 1889,
1881, 1872, 1864, 1856, 1848, 1840, 1832, 1824, 1816, 1808, 1800, 1792, 1784, 1776, 1767, 1759, 1751, 1743, 1735, 1727,
1719, 1710, 1702, 1694, 1686, 1678, 1669, 1661, 1653, 1645, 1636, 1628, 1620, 1612, 1604, 1595, 1587, 1579, 1570, 1562,
1554, 1546, 1537, 1529, 1521, 1512, 1504, 1496, 1487, 1479, 1471, 1462, 1454, 1446, 1437, 1429, 1420, 1412, 1404, 1395,
1387, 1378, 1370, 1362, 1353, 1345, 1336, 1328, 1319, 1311, 1302, 1294, 1286, 1277, 1269, 1260, 1252, 1243, 1235, 1226,
1218, 1209, 1201, 1192, 1184, 1175, 1166, 1158, 1149, 1141, 1132, 1124, 1115, 1107, 1098, 1089, 1081, 1072, 1064, 1055,
1047, 1038, 1029, 1021, 1012, 1003, 995, 986, 978, 969, 960, 952, 943, 934, 926, 917, 908, 900, 891, 883,
874, 865, 856, 848, 839, 830, 822, 813, 804, 796, 787, 778, 770, 761, 752, 743, 735, 726, 717, 709,
700, 691, 682, 674, 665, 656, 647, 639, 630, 621, 612, 604, 595, 586, 577, 569, 560, 551, 542, 533,
525, 516, 507, 498, 490, 481, 472, 463, 454, 446, 437, 428, 419, 410, 402, 393, 384, 375, 366, 358,
349, 340, 331, 322, 314, 305, 296, 287, 278, 269, 261, 252, 243, 234, 225, 216, 208, 199, 190, 181,
172, 163, 155, 146, 137, 128, 119, 110, 102, 93, 84, 75, 66, 57, 49, 40, 31, 22, 13, 4,
0, 0, 0, 0, 0, 0, 0, 0, 0, 0, 0, 0, 0, 0, 0, 0, 0, 0, 0, 0,
0, 0, 0, 0, 0, 0, 0, 0, 0, 0, 0, 0, 0, 0, 0, 0, 0, 0, 0, 0,
0, 0, 0, 0, 0, 0, 0, 0, 0, 0, 0, 0, 0, 0, 0, 0, 0, 0, 0, 0,
0, 0, 0, 0, 0, 0, 0, 0, 0, 0, 0, 0, 0, 0, 0, 0, 0, 0, 0, 0,
0, 0, 0, 0, 0, 0, 0, 0, 0, 0, 0, 0, 0, 0, 0, 0, 0, 0, 0, 0,
0, 0, 0, 0, 0, 0, 0, 0, 0, 0, 0, 0, 0, 0, 0, 0, 0, 0, 0, 0,
0, 0, 0, 0, 0, 0, 0, 0, 0, 0, 0, 0, 0, 0, 0, 0, 0, 0, 0, 0,
0, 0, 0, 0, 0, 0, 0, 0, 0, 0, 0, 0, 0, 0, 0, 0, 0, 0, 0, 0,
0, 0, 0, 0, 0, 0, 0, 0, 0, 0, 0, 0, 0, 0, 0, 0, 0, 0, 0, 0,
0, 0, 0, 0, 0, 0, 0, 0, 0, 0, 0, 0, 0, 0, 0, 0, 0, 0, 0, 0,
0, 0, 0, 0, 0, 0, 0, 0, 0, 0, 0, 0, 0, 0, 0, 0, 0, 0, 0, 0,
0, 0, 0, 0, 0, 0, 0, 0, 0, 0, 0, 0, 0, 0, 0, 0, 0, 0, 0, 0,
0, 0, 0, 0, 0, 0, 0, 0, 0, 0, 0, 0, 0, 0, 0, 0, 0, 0, 0, 0,
0, 0, 0, 0, 0, 0, 0, 0, 0, 0, 0, 0, 0, 0, 0, 0, 0, 0, 0, 0,
0, 0, 0, 0, 0, 0, 0, 0, 0, 0, 0, 0, 0, 0, 0, 0, 0, 0, 0, 0,
0, 0, 0, 0, 0, 0, 0, 0, 0, 0, 0, 0, 0, 0, 0, 0, 0, 0, 0, 0,
0, 0, 0, 0, 0, 0, 0, 0, 0, 0, 0, 0, 0, 0, 0, 0, 0, 0, 0, 0,
0, 0, 0, 0, 0, 0, 0, 0, 0, 0, 0, 0, 0, 0, 0, 0, 0, 0, 0, 0,
0, 0, 0, 0, 0, 0, 0, 0, 0, 0, 0, 0, 0, 0, 0, 0, 0, 0, 0, 0,
0, 0, 0, 0, 0, 0, 0, 0, 0, 0, 0, 0, 0, 0, 0, 0, 0, 0, 0, 0,
0, 0, 0, 0, 0, 0, 0, 0, 0, 0, 0, 0, 0, 0, 0, 0, 0, 0, 0, 0,
0, 0, 0, 0, 0, 0, 0, 0, 0, 0, 0, 0, 0, 0, 0, 0, 0, 0, 0, 0,
0, 0, 0, 0, 0, 0, 0, 0, 0, 0, 0, 0, 0, 0, 0, 0, 0, 0, 0, 0,
0, 0, 0, 0, 0, 0, 0, 0, 0, 0, 0, 0, 0, 0, 0, 0, 0, 0, 0, 0,
0, 0, 0, 0, 0, 0, 0, 0, 0, 0, 0, 0, 0, 0, 0, 0, 0, 0, 0, 0,
0, 0, 0, 0, 0, 0, 0, 0, 0, 0, 0, 0, 0, 0, 0, 0, 0, 0, 0, 0,
0, 0, 0, 0, 0, 0, 0, 0, 0, 0, 0, 0, 0, 0, 0, 0, 0, 0, 0, 0,
0, 0, 0, 0, 0, 0, 0, 0, 0, 0, 0, 0, 0, 0, 0, 0, 0, 0, 0, 0,
0, 0, 0, 0, 0, 0, 0, 0, 0, 0, 0, 0, 0, 0, 0, 0, 0, 0, 0, 0,
0, 0, 0, 0, 0, 0, 0, 0, 0, 0, 0, 0, 0, 0, 0, 0, 0, 0, 0, 0,
0, 0, 0, 0, 0, 0, 0, 0, 0, 0, 0, 0, 0, 0, 0, 0, 0, 0, 0, 0,
0, 0, 0, 0, 0, 0, 0, 0, 0, 0, 0, 0, 0, 0, 0, 0, 0, 0, 0, 0,
0, 0, 0, 0, 0, 0, 0, 0, 0, 0, 0, 0, 0, 0, 0, 0, 0, 0, 0, 0,
0, 0, 0, 0, 0, 0, 0, 0, 0, 0, 0, 0, 0, 0, 0, 0, 0, 0, 0, 0,
0, 0, 0, 0, 0, 0, 0, 0, 0, 0, 0, 0, 0, 0, 0, 0, 0, 0, 0, 0,
0, 0, 0, 0, 0, 0, 0, 0, 0, 0, 0, 0, 0, 0, 0, 0, 0, 0, 0, 0,
0, 0, 0, 0, 0, 0, 0, 0, 0, 0, 0, 0, 0, 0, 0, 0, 0, 0, 0, 0,
0, 0, 0, 0, 0, 0, 0, 0, 0, 0, 0, 0, 0, 0, 0, 0, 0, 0, 0, 0,
0, 0, 0, 0, 0, 0, 0, 0, 0, 0, 0, 0, 0, 0, 0, 0, 0, 0, 0, 0,
0, 0, 0, 0, 0, 0, 0, 0, 0, 0, 0, 0, 0, 0, 0, 0, 0, 0, 0, 0,
0, 0, 0, 0, 0, 0, 0, 0, 0, 0, 0, 0, 0, 0, 0, 0, 0, 0, 0, 0,
0, 0, 0, 0, 0, 0, 0, 0, 0, 0, 0, 0, 0, 0, 0, 0, 0, 0, 0, 0,
0, 0, 0, 0, 0, 0, 0, 0, 0, 0, 0, 0, 0, 0, 0, 0, 0, 0, 0, 0,
0, 0, 0, 0, 0, 0, 0, 0, 0, 0, 0, 0, 0, 0, 0, 0, 0, 0, 0, 0,
0, 0, 0, 0, 0, 0, 0, 0, 0, 0, 0, 0, 0, 0, 0, 0, 0, 0, 0, 0,
0, 0, 0, 0, 0, 0, 0, 0, 0, 0, 0, 0, 0, 0, 0, 0, 0, 0, 0, 0,
0, 0, 0, 0, 0, 0, 0, 0, 0, 0, 0, 0, 0, 0, 0, 0, 0, 0, 0, 0,
0, 0, 0, 0, 0, 0, 0, 0, 0, 0, 0, 0, 0, 0, 0, 0, 0, 0, 0, 0,
0, 0, 0, 0, 0, 0, 0, 0, 0, 0, 0, 0, 0, 0, 0, 0, 0, 0, 0, 0,
0, 0, 0, 0, 0, 0, 0, 0, 0, 0, 0, 0, 0, 0, 0, 0, 0, 0, 0, 0,
0, 0, 0, 0, 0, 0, 0, 0, 0, 0, 0, 0, 0, 0, 0, 0, 0, 0, 0, 0,
0, 0, 0, 0, 0, 0, 0, 0, 0, 0, 0, 0, 0, 0, 0, 0, 0, 0, 0, 0,
0, 0, 0, 0, 0, 0, 0, 0, 0, 0, 0, 0, 0, 0, 0, 0, 0, 0, 0, 0,
0, 0, 0, 0, 0, 0, 0, 0, 0, 0, 0, 0, 0, 0, 0, 0, 0, 0, 0, 0,
0, 0, 0, 0, 0, 0, 0, 0, 0, 0, 0, 0, 0, 0, 0, 0, 0, 0, 0, 0,
0, 0, 0, 0, 0, 0, 0, 0, 0, 0, 0, 0, 0, 0, 0, 0, 0, 0, 0, 0,
0, 0, 0, 0, 0, 0, 0, 0, 0, 0, 0, 0, 0, 0, 0, 0, 0, 0, 0, 0,
0, 0, 0, 0, 0, 0, 0, 0, 0, 0, 0, 0, 0, 0, 0, 0, 0, 0, 0, 0,
0, 0, 0, 0, 0, 0, 0, 0, 0, 0, 0, 0, 0, 0, 0, 0, 0, 0, 0, 0,
0, 0, 0, 0, 0, 0, 0, 0, 0, 0, 0, 0, 0, 0, 0, 0, 0, 0, 0, 0,
0, 0, 0, 0, 0, 0, 0, 0, 0, 0, 0, 0, 0, 0, 0, 0, 0, 0, 0, 0,
0, 0, 0, 0, 0, 0, 0, 0, 0, 0, 0, 0, 0, 0, 0, 0, 0, 0, 0, 0,
0, 0, 0, 0, 0, 0, 0, 0, 0, 0, 0, 0, 0, 0, 0, 0, 0, 0, 0, 0,
0, 0, 0, 0, 0, 0, 0, 0, 0, 0, 0, 0, 0, 0, 0, 0, 0, 0, 0, 0,
0, 0, 0, 0, 0, 0, 0, 0, 0, 0, 0, 0, 0, 0, 0, 0, 0, 0, 0, 0,
0, 0, 0, 0, 0, 0, 0, 0, 0, 0, 0, 0, 0, 0, 0, 0, 0, 0, 0, 0,
0, 0, 0, 0, 0, 0, 0, 0, 0, 0, 0, 0, 0, 0, 0, 0, 0, 0, 0, 0,
0, 0, 0, 0, 0, 0, 0, 0, 0, 0, 0, 0, 0, 0, 0, 0, 0, 0, 0, 0,
0, 0, 0, 0, 0, 0, 0, 0, 0, 0, 0, 0, 0, 0, 0, 0, 0, 0, 0, 0,
0, 0, 0, 0, 0, 0, 0, 0, 0, 0, 0, 0, 0, 0, 0, 0, 0, 0, 0, 0,
0, 0, 0, 0, 0, 0, 0, 0, 0, 0, 0, 0, 0, 0, 0, 0, 0, 0, 0, 0,
0, 0, 0, 0, 0, 0, 0, 0, 0, 0, 0, 0, 0, 0, 0, 0, 0, 0, 0, 0,
0, 0, 0, 0, 0, 0, 0, 0, 0, 0, 0, 0, 0, 0, 0, 0, 0, 0, 0, 0,
0, 0, 0, 0, 0, 0, 0, 0, 0, 0, 0, 0, 0, 0, 0, 0, 0, 0, 0, 0,
0, 0, 0, 0, 0, 0, 0, 0, 0, 0, 0, 0, 0, 0, 0, 0, 0, 0, 0, 0,
0, 0, 0, 0, 0, 0, 0, 0, 0, 0, 0, 0, 0, 0, 0, 0, 0, 0, 0, 0,
0, 0, 0, 0, 0, 0, 0, 0, 0, 0, 0, 0, 0, 0, 0, 0, 0, 0, 0, 0,
0, 0, 0, 0, 0, 0, 0, 0, 0, 0, 0, 0, 0, 0, 0, 0, 0, 0, 0, 0,
0, 0, 0, 0, 0, 0, 0, 0, 0, 0, 0, 0, 0, 0, 0, 0, 0, 0, 0, 0,
0, 0, 0, 0, 0, 0, 0, 0, 0, 0, 0, 0, 0, 0, 0, 0, 0, 0, 0, 0};

const uint16_t bangY1_5Hz[3200]={0, 0, 0, 0, 0, 0, 0, 0, 0, 0, 0, 0, 0, 0, 0, 0, 0, 0, 0, 0,
0, 0, 0, 0, 0, 0, 0, 0, 0, 0, 0, 0, 0, 0, 0, 0, 0, 0, 0, 0,
0, 0, 0, 0, 0, 0, 0, 0, 0, 0, 0, 0, 0, 0, 0, 0, 0, 0, 0, 0,
0, 0, 0, 0, 0, 0, 0, 0, 0, 0, 0, 0, 0, 0, 0, 0, 0, 0, 0, 0,
0, 0, 0, 0, 0, 0, 0, 0, 0, 0, 0, 0, 0, 0, 0, 0, 0, 0, 0, 0,
0, 0, 0, 0, 0, 0, 0, 0, 0, 0, 0, 0, 0, 0, 0, 0, 0, 0, 0, 0,
0, 0, 0, 0, 0, 0, 0, 0, 0, 0, 0, 0, 0, 0, 0, 0, 0, 0, 0, 0,
0, 0, 0, 0, 0, 0, 0, 0, 0, 0, 0, 0, 0, 0, 0, 0, 0, 0, 0, 0,
0, 0, 0, 0, 0, 0, 0, 0, 0, 0, 0, 0, 0, 0, 0, 0, 0, 0, 0, 0,
0, 0, 0, 0, 0, 0, 0, 0, 0, 0, 0, 0, 0, 0, 0, 0, 0, 0, 0, 0,
0, 0, 0, 0, 0, 0, 0, 0, 0, 0, 0, 0, 0, 0, 0, 0, 0, 0, 0, 0,
0, 0, 0, 0, 0, 0, 0, 0, 0, 0, 0, 0, 0, 0, 0, 0, 0, 0, 0, 0,
0, 0, 0, 0, 0, 0, 0, 0, 0, 0, 0, 0, 0, 0, 0, 0, 0, 0, 0, 0,
0, 0, 0, 0, 0, 0, 0, 0, 0, 0, 0, 0, 0, 0, 0, 0, 0, 0, 0, 0,
0, 0, 0, 0, 0, 0, 0, 0, 0, 0, 0, 0, 0, 0, 0, 0, 0, 0, 0, 0,
0, 0, 0, 0, 0, 0, 0, 0, 0, 0, 0, 0, 0, 0, 0, 0, 0, 0, 0, 0,
0, 0, 0, 0, 0, 0, 0, 0, 0, 0, 0, 0, 0, 0, 0, 0, 0, 0, 0, 0,
0, 0, 0, 0, 0, 0, 0, 0, 0, 0, 0, 0, 0, 0, 0, 0, 0, 0, 0, 0,
0, 0, 0, 0, 0, 0, 0, 0, 0, 0, 0, 0, 0, 0, 0, 0, 0, 0, 0, 0,
0, 0, 0, 0, 0, 0, 0, 0, 0, 0, 0, 0, 0, 0, 0, 0, 0, 0, 0, 0,
0, 0, 0, 0, 0, 0, 0, 0, 0, 0, 0, 0, 0, 0, 0, 0, 0, 0, 0, 0,
0, 0, 0, 0, 0, 0, 0, 0, 0, 0, 0, 0, 0, 0, 0, 0, 0, 0, 0, 0,
0, 0, 0, 0, 0, 0, 0, 0, 0, 0, 0, 0, 0, 0, 0, 0, 0, 0, 0, 0,
0, 0, 0, 0, 0, 0, 0, 0, 0, 0, 0, 0, 0, 0, 0, 0, 0, 0, 0, 0,
0, 0, 0, 0, 0, 0, 0, 0, 0, 0, 0, 0, 0, 0, 0, 0, 0, 0, 0, 0,
0, 0, 0, 0, 0, 0, 0, 0, 0, 0, 0, 0, 0, 0, 0, 0, 0, 0, 0, 0,
0, 0, 0, 0, 0, 0, 0, 0, 0, 0, 0, 0, 0, 0, 0, 0, 0, 0, 0, 0,
0, 0, 0, 0, 0, 0, 0, 0, 0, 0, 0, 0, 0, 0, 0, 0, 0, 0, 0, 0,
0, 0, 0, 0, 0, 0, 0, 0, 0, 0, 0, 0, 0, 0, 0, 0, 0, 0, 0, 0,
0, 0, 0, 0, 0, 0, 0, 0, 0, 0, 0, 0, 0, 0, 0, 0, 0, 0, 0, 0,
0, 0, 0, 0, 0, 0, 0, 0, 0, 0, 0, 0, 0, 0, 0, 0, 0, 0, 0, 0,
0, 0, 0, 0, 0, 0, 0, 0, 0, 0, 0, 0, 0, 0, 0, 0, 0, 0, 0, 0,
0, 0, 0, 0, 0, 0, 0, 0, 0, 0, 0, 0, 0, 0, 0, 0, 0, 0, 0, 0,
0, 0, 0, 0, 0, 0, 0, 0, 0, 0, 0, 0, 0, 0, 0, 0, 0, 0, 0, 0,
0, 0, 0, 0, 0, 0, 0, 0, 0, 0, 0, 0, 0, 0, 0, 0, 0, 0, 0, 0,
0, 0, 0, 0, 0, 0, 0, 0, 0, 0, 0, 0, 0, 0, 0, 0, 0, 0, 0, 0,
0, 0, 0, 0, 0, 0, 0, 0, 0, 0, 0, 0, 0, 0, 0, 0, 0, 0, 0, 0,
0, 0, 0, 0, 0, 0, 0, 0, 0, 0, 0, 0, 0, 0, 0, 0, 0, 0, 0, 0,
0, 0, 0, 0, 0, 0, 0, 0, 0, 0, 0, 0, 0, 0, 0, 0, 0, 0, 0, 0,
0, 0, 0, 0, 0, 0, 0, 0, 0, 0, 0, 0, 0, 0, 0, 0, 0, 0, 0, 0,
0, 0, 0, 0, 0, 0, 0, 0, 0, 0, 0, 0, 0, 0, 0, 0, 0, 0, 0, 0,
0, 0, 0, 0, 0, 0, 0, 0, 0, 0, 0, 0, 0, 0, 0, 0, 0, 0, 0, 0,
0, 0, 0, 0, 0, 0, 0, 0, 0, 0, 0, 0, 0, 0, 0, 0, 0, 0, 0, 0,
0, 0, 0, 0, 0, 0, 0, 0, 0, 0, 0, 0, 0, 0, 0, 0, 0, 0, 0, 0,
0, 0, 0, 0, 0, 0, 0, 0, 0, 0, 0, 0, 0, 0, 0, 0, 0, 0, 0, 0,
0, 0, 0, 0, 0, 0, 0, 0, 0, 0, 0, 0, 0, 0, 0, 0, 0, 0, 0, 0,
0, 0, 0, 0, 0, 0, 0, 0, 0, 0, 0, 0, 0, 0, 0, 0, 0, 0, 0, 0,
0, 0, 0, 0, 0, 0, 0, 0, 0, 0, 0, 0, 0, 0, 0, 0, 0, 0, 0, 0,
0, 0, 0, 0, 0, 0, 0, 0, 0, 0, 0, 0, 0, 0, 0, 0, 0, 0, 0, 0,
0, 0, 0, 0, 0, 0, 0, 0, 0, 0, 0, 0, 0, 0, 0, 0, 0, 0, 0, 0,
0, 0, 0, 0, 0, 0, 0, 0, 0, 0, 0, 0, 0, 0, 0, 0, 0, 0, 0, 0,
0, 0, 0, 0, 0, 0, 0, 0, 0, 0, 0, 0, 0, 0, 0, 0, 0, 0, 0, 0,
0, 0, 0, 0, 0, 0, 0, 0, 0, 0, 0, 0, 0, 0, 0, 0, 0, 0, 0, 0,
0, 0, 0, 0, 0, 0, 0, 6, 15, 24, 32, 41, 50, 59, 68, 77, 85, 94, 103, 112,
121, 130, 138, 147, 156, 165, 174, 183, 191, 200, 209, 218, 227, 236, 244, 253, 262, 271, 280, 289,
297, 306, 315, 324, 333, 341, 350, 359, 368, 377, 385, 394, 403, 412, 421, 429, 438, 447, 456, 465,
473, 482, 491, 500, 509, 517, 526, 535, 544, 552, 561, 570, 579, 588, 596, 605, 614, 623, 631, 640,
649, 658, 666, 675, 684, 693, 701, 710, 719, 727, 736, 745, 754, 762, 771, 780, 788, 797, 806, 815,
823, 832, 841, 849, 858, 867, 875, 884, 893, 901, 910, 919, 927, 936, 945, 953, 962, 970, 979, 988,
996, 1005, 1014, 1022, 1031, 1039, 1048, 1057, 1065, 1074, 1082, 1091, 1099, 1108, 1117, 1125, 1134, 1142, 1151, 1159,
1168, 1176, 1185, 1193, 1202, 1211, 1219, 1228, 1236, 1245, 1253, 1261, 1270, 1278, 1287, 1295, 1304, 1312, 1321, 1329,
1338, 1346, 1355, 1363, 1371, 1380, 1388, 1397, 1405, 1413, 1422, 1430, 1439, 1447, 1455, 1464, 1472, 1480, 1489, 1497,
1505, 1514, 1522, 1530, 1539, 1547, 1555, 1564, 1572, 1580, 1588, 1597, 1605, 1613, 1621, 1630, 1638, 1646, 1654, 1663,
1671, 1679, 1687, 1695, 1704, 1712, 1720, 1728, 1736, 1744, 1752, 1761, 1769, 1777, 1785, 1793, 1801, 1809, 1817, 1825,
1834, 1842, 1850, 1858, 1866, 1874, 1882, 1890, 1898, 1906, 1914, 1922, 1930, 1938, 1946, 1954, 1962, 1970, 1978, 1986,
1994, 2001, 2009, 2017, 2025, 2033, 2041, 2049, 2057, 2065, 2072, 2080, 2088, 2096, 2104, 2111, 2119, 2127, 2135, 2143,
2150, 2158, 2166, 2174, 2181, 2189, 2197, 2205, 2212, 2220, 2228, 2235, 2243, 2251, 2258, 2266, 2274, 2281, 2289, 2296,
2304, 2312, 2319, 2327, 2334, 2342, 2349, 2357, 2364, 2372, 2379, 2387, 2394, 2402, 2409, 2417, 2424, 2432, 2439, 2447,
2454, 2461, 2469, 2476, 2484, 2491, 2498, 2506, 2513, 2520, 2528, 2535, 2542, 2550, 2557, 2564, 2571, 2579, 2586, 2593,
2600, 2607, 2615, 2622, 2629, 2636, 2643, 2651, 2658, 2665, 2672, 2679, 2686, 2693, 2700, 2707, 2714, 2721, 2728, 2735,
2742, 2749, 2756, 2763, 2770, 2777, 2784, 2791, 2798, 2805, 2812, 2819, 2826, 2833, 2840, 2846, 2853, 2860, 2867, 2874,
2880, 2887, 2894, 2901, 2908, 2914, 2921, 2928, 2934, 2941, 2948, 2955, 2961, 2968, 2974, 2981, 2988, 2994, 3001, 3007,
3014, 3021, 3027, 3034, 3040, 3047, 3053, 3060, 3066, 3073, 3079, 3086, 3092, 3098, 3105, 3111, 3118, 3124, 3130, 3137,
3143, 3149, 3156, 3162, 3168, 3174, 3181, 3187, 3193, 3199, 3206, 3212, 3218, 3224, 3230, 3236, 3243, 3249, 3255, 3261,
3267, 3273, 3279, 3285, 3291, 3297, 3303, 3309, 3315, 3321, 3327, 3333, 3339, 3345, 3351, 3357, 3363, 3368, 3374, 3380,
3386, 3392, 3398, 3403, 3409, 3415, 3421, 3426, 3432, 3438, 3444, 3449, 3455, 3461, 3466, 3472, 3477, 3483, 3489, 3494,
3500, 3505, 3511, 3516, 3522, 3527, 3533, 3538, 3544, 3549, 3555, 3560, 3565, 3571, 3576, 3582, 3587, 3592, 3598, 3603,
3608, 3613, 3619, 3624, 3629, 3634, 3640, 3645, 3650, 3655, 3660, 3665, 3671, 3676, 3681, 3686, 3691, 3696, 3701, 3706,
3711, 3716, 3721, 3726, 3731, 3736, 3741, 3746, 3751, 3755, 3760, 3765, 3770, 3775, 3780, 3784, 3789, 3794, 3799, 3803,
3808, 3813, 3817, 3822, 3827, 3831, 3836, 3841, 3845, 3850, 3854, 3859, 3864, 3868, 3873, 3877, 3882, 3886, 3890, 3895,
3899, 3904, 3908, 3912, 3917, 3921, 3926, 3930, 3934, 3938, 3943, 3947, 3951, 3955, 3960, 3964, 3968, 3972, 3976, 3980,
3985, 3989, 3993, 3997, 4001, 4005, 4009, 4013, 4017, 4021, 4025, 4029, 4033, 4037, 4041, 4044, 4048, 4052, 4056, 4060,
4064, 4067, 4071, 4075, 4079, 4082, 4086, 4090, 4093, 4097, 4101, 4104, 4108, 4112, 4115, 4119, 4122, 4126, 4129, 4133,
4136, 4140, 4143, 4147, 4150, 4154, 4157, 4160, 4164, 4167, 4170, 4174, 4177, 4180, 4184, 4187, 4190, 4193, 4196, 4200,
4203, 4206, 4209, 4212, 4215, 4218, 4221, 4224, 4228, 4231, 4234, 4237, 4240, 4242, 4245, 4248, 4251, 4254, 4257, 4260,
4263, 4266, 4268, 4271, 4274, 4277, 4279, 4282, 4285, 4288, 4290, 4293, 4295, 4298, 4301, 4303, 4306, 4308, 4311, 4314,
4316, 4319, 4321, 4323, 4326, 4328, 4331, 4333, 4336, 4338, 4340, 4343, 4345, 4347, 4349, 4352, 4354, 4356, 4358, 4361,
4363, 4365, 4367, 4369, 4371, 4373, 4375, 4377, 4380, 4382, 4384, 4386, 4388, 4389, 4391, 4393, 4395, 4397, 4399, 4401,
4403, 4404, 4406, 4408, 4410, 4412, 4413, 4415, 4417, 4418, 4420, 4422, 4423, 4425, 4427, 4428, 4430, 4431, 4433, 4434,
4436, 4437, 4439, 4440, 4442, 4443, 4444, 4446, 4447, 4449, 4450, 4451, 4452, 4454, 4455, 4456, 4457, 4459, 4460, 4461,
4462, 4463, 4464, 4466, 4467, 4468, 4469, 4470, 4471, 4472, 4473, 4474, 4475, 4476, 4476, 4477, 4478, 4479, 4480, 4481,
4482, 4482, 4483, 4484, 4485, 4485, 4486, 4487, 4487, 4488, 4489, 4489, 4490, 4491, 4491, 4492, 4492, 4493, 4493, 4494,
4494, 4495, 4495, 4495, 4496, 4496, 4496, 4497, 4497, 4497, 4498, 4498, 4498, 4499, 4499, 4499, 4499, 4499, 4499, 4500,
4500, 4500, 4500, 4500, 4500, 4500, 4500, 4500, 4500, 4500, 4500, 4500, 4500, 4500, 4499, 4499, 4499, 4499, 4499, 4499,
4498, 4498, 4498, 4498, 4497, 4497, 4497, 4496, 4496, 4495, 4495, 4495, 4494, 4494, 4493, 4493, 4492, 4492, 4491, 4491,
4490, 4489, 4489, 4488, 4488, 4487, 4486, 4485, 4485, 4484, 4483, 4482, 4482, 4481, 4480, 4479, 4478, 4478, 4477, 4476,
4475, 4474, 4473, 4472, 4471, 4470, 4469, 4468, 4467, 4466, 4465, 4463, 4462, 4461, 4460, 4459, 4458, 4456, 4455, 4454,
4453, 4451, 4450, 4449, 4447, 4446, 4445, 4443, 4442, 4440, 4439, 4438, 4436, 4435, 4433, 4432, 4430, 4428, 4427, 4425,
4424, 4422, 4420, 4419, 4417, 4415, 4414, 4412, 4410, 4408, 4407, 4405, 4403, 4401, 4399, 4397, 4396, 4394, 4392, 4390,
4388, 4386, 4384, 4382, 4380, 4378, 4376, 4374, 4372, 4369, 4367, 4365, 4363, 4361, 4359, 4357, 4354, 4352, 4350, 4348,
4345, 4343, 4341, 4338, 4336, 4334, 4331, 4329, 4326, 4324, 4321, 4319, 4316, 4314, 4311, 4309, 4306, 4304, 4301, 4299,
4296, 4293, 4291, 4288, 4285, 4283, 4280, 4277, 4274, 4272, 4269, 4266, 4263, 4260, 4257, 4255, 4252, 4249, 4246, 4243,
4240, 4237, 4234, 4231, 4228, 4225, 4222, 4219, 4216, 4213, 4210, 4206, 4203, 4200, 4197, 4194, 4191, 4187, 4184, 4181,
4178, 4174, 4171, 4168, 4164, 4161, 4158, 4154, 4151, 4147, 4144, 4140, 4137, 4133, 4130, 4126, 4123, 4119, 4116, 4112,
4109, 4105, 4101, 4098, 4094, 4090, 4087, 4083, 4079, 4076, 4072, 4068, 4064, 4060, 4057, 4053, 4049, 4045, 4041, 4037,
4033, 4029, 4025, 4022, 4018, 4014, 4010, 4006, 4002, 3997, 3993, 3989, 3985, 3981, 3977, 3973, 3969, 3964, 3960, 3956,
3952, 3948, 3943, 3939, 3935, 3931, 3926, 3922, 3918, 3913, 3909, 3904, 3900, 3896, 3891, 3887, 3882, 3878, 3873, 3869,
3864, 3860, 3855, 3851, 3846, 3841, 3837, 3832, 3828, 3823, 3818, 3814, 3809, 3804, 3799, 3795, 3790, 3785, 3780, 3776,
3771, 3766, 3761, 3756, 3751, 3746, 3742, 3737, 3732, 3727, 3722, 3717, 3712, 3707, 3702, 3697, 3692, 3687, 3682, 3677,
3671, 3666, 3661, 3656, 3651, 3646, 3640, 3635, 3630, 3625, 3620, 3614, 3609, 3604, 3598, 3593, 3588, 3582, 3577, 3572,
3566, 3561, 3556, 3550, 3545, 3539, 3534, 3528, 3523, 3517, 3512, 3506, 3501, 3495, 3490, 3484, 3478, 3473, 3467, 3462,
3456, 3450, 3445, 3439, 3433, 3427, 3422, 3416, 3410, 3404, 3399, 3393, 3387, 3381, 3375, 3369, 3364, 3358, 3352, 3346,
3340, 3334, 3328, 3322, 3316, 3310, 3304, 3298, 3292, 3286, 3280, 3274, 3268, 3262, 3256, 3250, 3244, 3237, 3231, 3225,
3219, 3213, 3207, 3200, 3194, 3188, 3182, 3175, 3169, 3163, 3157, 3150, 3144, 3138, 3131, 3125, 3119, 3112, 3106, 3099,
3093, 3087, 3080, 3074, 3067, 3061, 3054, 3048, 3041, 3035, 3028, 3022, 3015, 3009, 3002, 2995, 2989, 2982, 2976, 2969,
2962, 2956, 2949, 2942, 2936, 2929, 2922, 2915, 2909, 2902, 2895, 2888, 2882, 2875, 2868, 2861, 2854, 2848, 2841, 2834,
2827, 2820, 2813, 2806, 2799, 2792, 2786, 2779, 2772, 2765, 2758, 2751, 2744, 2737, 2730, 2723, 2716, 2709, 2701, 2694,
2687, 2680, 2673, 2666, 2659, 2652, 2645, 2637, 2630, 2623, 2616, 2609, 2601, 2594, 2587, 2580, 2573, 2565, 2558, 2551,
2543, 2536, 2529, 2522, 2514, 2507, 2500, 2492, 2485, 2477, 2470, 2463, 2455, 2448, 2440, 2433, 2426, 2418, 2411, 2403,
2396, 2388, 2381, 2373, 2366, 2358, 2351, 2343, 2336, 2328, 2320, 2313, 2305, 2298, 2290, 2282, 2275, 2267, 2260, 2252,
2244, 2237, 2229, 2221, 2214, 2206, 2198, 2190, 2183, 2175, 2167, 2159, 2152, 2144, 2136, 2128, 2121, 2113, 2105, 2097,
2089, 2082, 2074, 2066, 2058, 2050, 2042, 2034, 2026, 2019, 2011, 2003, 1995, 1987, 1979, 1971, 1963, 1955, 1947, 1939,
1931, 1923, 1915, 1907, 1899, 1891, 1883, 1875, 1867, 1859, 1851, 1843, 1835, 1827, 1819, 1811, 1803, 1794, 1786, 1778,
1770, 1762, 1754, 1746, 1738, 1729, 1721, 1713, 1705, 1697, 1689, 1680, 1672, 1664, 1656, 1647, 1639, 1631, 1623, 1615,
1606, 1598, 1590, 1581, 1573, 1565, 1557, 1548, 1540, 1532, 1523, 1515, 1507, 1498, 1490, 1482, 1473, 1465, 1457, 1448,
1440, 1432, 1423, 1415, 1406, 1398, 1390, 1381, 1373, 1364, 1356, 1347, 1339, 1331, 1322, 1314, 1305, 1297, 1288, 1280,
1271, 1263, 1254, 1246, 1237, 1229, 1220, 1212, 1203, 1195, 1186, 1178, 1169, 1161, 1152, 1144, 1135, 1127, 1118, 1109,
1101, 1092, 1084, 1075, 1067, 1058, 1049, 1041, 1032, 1024, 1015, 1006, 998, 989, 981, 972, 963, 955, 946, 937,
929, 920, 911, 903, 894, 885, 877, 868, 859, 851, 842, 833, 825, 816, 807, 799, 790, 781, 772, 764,
755, 746, 738, 729, 720, 711, 703, 694, 685, 677, 668, 659, 650, 642, 633, 624, 615, 607, 598, 589,
580, 571, 563, 554, 545, 536, 528, 519, 510, 501, 492, 484, 475, 466, 457, 449, 440, 431, 422, 413,
405, 396, 387, 378, 369, 361, 352, 343, 334, 325, 316, 308, 299, 290, 281, 272, 264, 255, 246, 237,
228, 219, 211, 202, 193, 184, 175, 166, 158, 149, 140, 131, 122, 113, 105, 96, 87, 78, 69, 60,
52, 43, 34, 25, 16, 7, 0, 0, 0, 0, 0, 0, 0, 0, 0, 0, 0, 0, 0, 0,
0, 0, 0, 0, 0, 0, 0, 0, 0, 0, 0, 0, 0, 0, 0, 0, 0, 0, 0, 0,
0, 0, 0, 0, 0, 0, 0, 0, 0, 0, 0, 0, 0, 0, 0, 0, 0, 0, 0, 0,
0, 0, 0, 0, 0, 0, 0, 0, 0, 0, 0, 0, 0, 0, 0, 0, 0, 0, 0, 0,
0, 0, 0, 0, 0, 0, 0, 0, 0, 0, 0, 0, 0, 0, 0, 0, 0, 0, 0, 0,
0, 0, 0, 0, 0, 0, 0, 0, 0, 0, 0, 0, 0, 0, 0, 0, 0, 0, 0, 0,
0, 0, 0, 0, 0, 0, 0, 0, 0, 0, 0, 0, 0, 0, 0, 0, 0, 0, 0, 0,
0, 0, 0, 0, 0, 0, 0, 0, 0, 0, 0, 0, 0, 0, 0, 0, 0, 0, 0, 0,
0, 0, 0, 0, 0, 0, 0, 0, 0, 0, 0, 0, 0, 0, 0, 0, 0, 0, 0, 0,
0, 0, 0, 0, 0, 0, 0, 0, 0, 0, 0, 0, 0, 0, 0, 0, 0, 0, 0, 0,
0, 0, 0, 0, 0, 0, 0, 0, 0, 0, 0, 0, 0, 0, 0, 0, 0, 0, 0, 0,
0, 0, 0, 0, 0, 0, 0, 0, 0, 0, 0, 0, 0, 0, 0, 0, 0, 0, 0, 0,
0, 0, 0, 0, 0, 0, 0, 0, 0, 0, 0, 0, 0, 0, 0, 0, 0, 0, 0, 0,
0, 0, 0, 0, 0, 0, 0, 0, 0, 0, 0, 0, 0, 0, 0, 0, 0, 0, 0, 0,
0, 0, 0, 0, 0, 0, 0, 0, 0, 0, 0, 0, 0, 0, 0, 0, 0, 0, 0, 0,
0, 0, 0, 0, 0, 0, 0, 0, 0, 0, 0, 0, 0, 0, 0, 0, 0, 0, 0, 0,
0, 0, 0, 0, 0, 0, 0, 0, 0, 0, 0, 0, 0, 0, 0, 0, 0, 0, 0, 0,
0, 0, 0, 0, 0, 0, 0, 0, 0, 0, 0, 0, 0, 0, 0, 0, 0, 0, 0, 0,
0, 0, 0, 0, 0, 0, 0, 0, 0, 0, 0, 0, 0, 0, 0, 0, 0, 0, 0, 0,
0, 0, 0, 0, 0, 0, 0, 0, 0, 0, 0, 0, 0, 0, 0, 0, 0, 0, 0, 0,
0, 0, 0, 0, 0, 0, 0, 0, 0, 0, 0, 0, 0, 0, 0, 0, 0, 0, 0, 0,
0, 0, 0, 0, 0, 0, 0, 0, 0, 0, 0, 0, 0, 0, 0, 0, 0, 0, 0, 0,
0, 0, 0, 0, 0, 0, 0, 0, 0, 0, 0, 0, 0, 0, 0, 0, 0, 0, 0, 0,
0, 0, 0, 0, 0, 0, 0, 0, 0, 0, 0, 0, 0, 0, 0, 0, 0, 0, 0, 0,
0, 0, 0, 0, 0, 0, 0, 0, 0, 0, 0, 0, 0, 0, 0, 0, 0, 0, 0, 0,
0, 0, 0, 0, 0, 0, 0, 0, 0, 0, 0, 0, 0, 0, 0, 0, 0, 0, 0, 0,
0, 0, 0, 0, 0, 0, 0, 0, 0, 0, 0, 0, 0, 0, 0, 0, 0, 0, 0, 0};

const uint16_t bangZ1_5Hz[3200]={3897, 3893, 3888, 3884, 3879, 3875, 3870, 3866, 3861, 3857, 3852, 3848, 3843, 3838, 3834, 3829, 3824, 3820, 3815, 3810,
3806, 3801, 3796, 3792, 3787, 3782, 3777, 3772, 3768, 3763, 3758, 3753, 3748, 3743, 3738, 3733, 3728, 3723, 3718, 3714,
3709, 3703, 3698, 3693, 3688, 3683, 3678, 3673, 3668, 3663, 3658, 3653, 3647, 3642, 3637, 3632, 3627, 3621, 3616, 3611,
3606, 3600, 3595, 3590, 3584, 3579, 3574, 3568, 3563, 3557, 3552, 3547, 3541, 3536, 3530, 3525, 3519, 3514, 3508, 3503,
3497, 3491, 3486, 3480, 3475, 3469, 3463, 3458, 3452, 3446, 3441, 3435, 3429, 3424, 3418, 3412, 3406, 3401, 3395, 3389,
3383, 3377, 3371, 3366, 3360, 3354, 3348, 3342, 3336, 3330, 3324, 3318, 3312, 3306, 3300, 3294, 3288, 3282, 3276, 3270,
3264, 3258, 3252, 3246, 3240, 3233, 3227, 3221, 3215, 3209, 3202, 3196, 3190, 3184, 3178, 3171, 3165, 3159, 3152, 3146,
3140, 3133, 3127, 3121, 3114, 3108, 3102, 3095, 3089, 3082, 3076, 3069, 3063, 3056, 3050, 3043, 3037, 3030, 3024, 3017,
3011, 3004, 2998, 2991, 2984, 2978, 2971, 2964, 2958, 2951, 2944, 2938, 2931, 2924, 2918, 2911, 2904, 2897, 2891, 2884,
2877, 2870, 2863, 2857, 2850, 2843, 2836, 2829, 2822, 2815, 2809, 2802, 2795, 2788, 2781, 2774, 2767, 2760, 2753, 2746,
2739, 2732, 2725, 2718, 2711, 2704, 2697, 2690, 2683, 2675, 2668, 2661, 2654, 2647, 2640, 2633, 2625, 2618, 2611, 2604,
2597, 2589, 2582, 2575, 2568, 2560, 2553, 2546, 2539, 2531, 2524, 2517, 2509, 2502, 2495, 2487, 2480, 2473, 2465, 2458,
2450, 2443, 2435, 2428, 2421, 2413, 2406, 2398, 2391, 2383, 2376, 2368, 2361, 2353, 2346, 2338, 2331, 2323, 2315, 2308,
2300, 2293, 2285, 2277, 2270, 2262, 2254, 2247, 2239, 2231, 2224, 2216, 2208, 2201, 2193, 2185, 2178, 2170, 2162, 2154,
2147, 2139, 2131, 2123, 2115, 2108, 2100, 2092, 2084, 2076, 2068, 2061, 2053, 2045, 2037, 2029, 2021, 2013, 2005, 1997,
1990, 1982, 1974, 1966, 1958, 1950, 1942, 1934, 1926, 1918, 1910, 1902, 1894, 1886, 1878, 1870, 1862, 1854, 1846, 1838,
1830, 1821, 1813, 1805, 1797, 1789, 1781, 1773, 1765, 1757, 1748, 1740, 1732, 1724, 1716, 1708, 1699, 1691, 1683, 1675,
1667, 1658, 1650, 1642, 1634, 1626, 1617, 1609, 1601, 1592, 1584, 1576, 1568, 1559, 1551, 1543, 1534, 1526, 1518, 1510,
1501, 1493, 1485, 1476, 1468, 1459, 1451, 1443, 1434, 1426, 1418, 1409, 1401, 1392, 1384, 1376, 1367, 1359, 1350, 1342,
1333, 1325, 1317, 1308, 1300, 1291, 1283, 1274, 1266, 1257, 1249, 1240, 1232, 1223, 1215, 1206, 1198, 1189, 1181, 1172,
1164, 1155, 1147, 1138, 1129, 1121, 1112, 1104, 1095, 1087, 1078, 1069, 1061, 1052, 1044, 1035, 1026, 1018, 1009, 1001,
992, 983, 975, 966, 957, 949, 940, 932, 923, 914, 906, 897, 888, 880, 871, 862, 854, 845, 836, 828,
819, 810, 801, 793, 784, 775, 767, 758, 749, 741, 732, 723, 714, 706, 697, 688, 679, 671, 662, 653,
644, 636, 627, 618, 609, 601, 592, 583, 574, 566, 557, 548, 539, 531, 522, 513, 504, 495, 487, 478,
469, 460, 451, 443, 434, 425, 416, 407, 399, 390, 381, 372, 363, 355, 346, 337, 328, 319, 311, 302,
293, 284, 275, 266, 258, 249, 240, 231, 222, 214, 205, 196, 187, 178, 169, 161, 152, 143, 134, 125,
116, 108, 99, 90, 81, 72, 63, 55, 46, 37, 28, 19, 10, 1, 0, 0, 0, 0, 0, 0,
0, 0, 0, 0, 0, 0, 0, 0, 0, 0, 0, 0, 0, 0, 0, 0, 0, 0, 0, 0,
0, 0, 0, 0, 0, 0, 0, 0, 0, 0, 0, 0, 0, 0, 0, 0, 0, 0, 0, 0,
0, 0, 0, 0, 0, 0, 0, 0, 0, 0, 0, 0, 0, 0, 0, 0, 0, 0, 0, 0,
0, 0, 0, 0, 0, 0, 0, 0, 0, 0, 0, 0, 0, 0, 0, 0, 0, 0, 0, 0,
0, 0, 0, 0, 0, 0, 0, 0, 0, 0, 0, 0, 0, 0, 0, 0, 0, 0, 0, 0,
0, 0, 0, 0, 0, 0, 0, 0, 0, 0, 0, 0, 0, 0, 0, 0, 0, 0, 0, 0,
0, 0, 0, 0, 0, 0, 0, 0, 0, 0, 0, 0, 0, 0, 0, 0, 0, 0, 0, 0,
0, 0, 0, 0, 0, 0, 0, 0, 0, 0, 0, 0, 0, 0, 0, 0, 0, 0, 0, 0,
0, 0, 0, 0, 0, 0, 0, 0, 0, 0, 0, 0, 0, 0, 0, 0, 0, 0, 0, 0,
0, 0, 0, 0, 0, 0, 0, 0, 0, 0, 0, 0, 0, 0, 0, 0, 0, 0, 0, 0,
0, 0, 0, 0, 0, 0, 0, 0, 0, 0, 0, 0, 0, 0, 0, 0, 0, 0, 0, 0,
0, 0, 0, 0, 0, 0, 0, 0, 0, 0, 0, 0, 0, 0, 0, 0, 0, 0, 0, 0,
0, 0, 0, 0, 0, 0, 0, 0, 0, 0, 0, 0, 0, 0, 0, 0, 0, 0, 0, 0,
0, 0, 0, 0, 0, 0, 0, 0, 0, 0, 0, 0, 0, 0, 0, 0, 0, 0, 0, 0,
0, 0, 0, 0, 0, 0, 0, 0, 0, 0, 0, 0, 0, 0, 0, 0, 0, 0, 0, 0,
0, 0, 0, 0, 0, 0, 0, 0, 0, 0, 0, 0, 0, 0, 0, 0, 0, 0, 0, 0,
0, 0, 0, 0, 0, 0, 0, 0, 0, 0, 0, 0, 0, 0, 0, 0, 0, 0, 0, 0,
0, 0, 0, 0, 0, 0, 0, 0, 0, 0, 0, 0, 0, 0, 0, 0, 0, 0, 0, 0,
0, 0, 0, 0, 0, 0, 0, 0, 0, 0, 0, 0, 0, 0, 0, 0, 0, 0, 0, 0,
0, 0, 0, 0, 0, 0, 0, 0, 0, 0, 0, 0, 0, 0, 0, 0, 0, 0, 0, 0,
0, 0, 0, 0, 0, 0, 0, 0, 0, 0, 0, 0, 0, 0, 0, 0, 0, 0, 0, 0,
0, 0, 0, 0, 0, 0, 0, 0, 0, 0, 0, 0, 0, 0, 0, 0, 0, 0, 0, 0,
0, 0, 0, 0, 0, 0, 0, 0, 0, 0, 0, 0, 0, 0, 0, 0, 0, 0, 0, 0,
0, 0, 0, 0, 0, 0, 0, 0, 0, 0, 0, 0, 0, 0, 0, 0, 0, 0, 0, 0,
0, 0, 0, 0, 0, 0, 0, 0, 0, 0, 0, 0, 0, 0, 0, 0, 0, 0, 0, 0,
0, 0, 0, 0, 0, 0, 0, 0, 0, 0, 0, 0, 0, 0, 0, 0, 0, 0, 0, 0,
0, 0, 0, 0, 0, 0, 0, 0, 0, 0, 0, 0, 0, 0, 0, 0, 0, 0, 0, 0,
0, 0, 0, 0, 0, 0, 0, 0, 0, 0, 0, 0, 0, 0, 0, 0, 0, 0, 0, 0,
0, 0, 0, 0, 0, 0, 0, 0, 0, 0, 0, 0, 0, 0, 0, 0, 0, 0, 0, 0,
0, 0, 0, 0, 0, 0, 0, 0, 0, 0, 0, 0, 0, 0, 0, 0, 0, 0, 0, 0,
0, 0, 0, 0, 0, 0, 0, 0, 0, 0, 0, 0, 0, 0, 0, 0, 0, 0, 0, 0,
0, 0, 0, 0, 0, 0, 0, 0, 0, 0, 0, 0, 0, 0, 0, 0, 0, 0, 0, 0,
0, 0, 0, 0, 0, 0, 0, 0, 0, 0, 0, 0, 0, 0, 0, 0, 0, 0, 0, 0,
0, 0, 0, 0, 0, 0, 0, 0, 0, 0, 0, 0, 0, 0, 0, 0, 0, 0, 0, 0,
0, 0, 0, 0, 0, 0, 0, 0, 0, 0, 0, 0, 0, 0, 0, 0, 0, 0, 0, 0,
0, 0, 0, 0, 0, 0, 0, 0, 0, 0, 0, 0, 0, 0, 0, 0, 0, 0, 0, 0,
0, 0, 0, 0, 0, 0, 0, 0, 0, 0, 0, 0, 0, 0, 0, 0, 0, 0, 0, 0,
0, 0, 0, 0, 0, 0, 0, 0, 0, 0, 0, 0, 0, 0, 0, 0, 0, 0, 0, 0,
0, 0, 0, 0, 0, 0, 0, 0, 0, 0, 0, 0, 0, 0, 0, 0, 0, 0, 0, 0,
0, 0, 0, 0, 0, 0, 0, 0, 0, 0, 0, 0, 0, 0, 0, 0, 0, 0, 0, 0,
0, 0, 0, 0, 0, 0, 0, 0, 0, 0, 0, 0, 0, 0, 0, 0, 0, 0, 0, 0,
0, 0, 0, 0, 0, 0, 0, 0, 0, 0, 0, 0, 0, 0, 0, 0, 0, 0, 0, 0,
0, 0, 0, 0, 0, 0, 0, 0, 0, 0, 0, 0, 0, 0, 0, 0, 0, 0, 0, 0,
0, 0, 0, 0, 0, 0, 0, 0, 0, 0, 0, 0, 0, 0, 0, 0, 0, 0, 0, 0,
0, 0, 0, 0, 0, 0, 0, 0, 0, 0, 0, 0, 0, 0, 0, 0, 0, 0, 0, 0,
0, 0, 0, 0, 0, 0, 0, 0, 0, 0, 0, 0, 0, 0, 0, 0, 0, 0, 0, 0,
0, 0, 0, 0, 0, 0, 0, 0, 0, 0, 0, 0, 0, 0, 0, 0, 0, 0, 0, 0,
0, 0, 0, 0, 0, 0, 0, 0, 0, 0, 0, 0, 0, 0, 0, 0, 0, 0, 0, 0,
0, 0, 0, 0, 0, 0, 0, 0, 0, 0, 0, 0, 0, 0, 0, 0, 0, 0, 0, 0,
0, 0, 0, 0, 0, 0, 0, 0, 0, 0, 0, 0, 0, 0, 0, 0, 0, 0, 0, 0,
0, 0, 0, 0, 0, 0, 0, 0, 0, 0, 0, 0, 0, 0, 0, 0, 0, 0, 0, 0,
0, 0, 0, 0, 0, 0, 0, 0, 0, 0, 0, 0, 0, 0, 0, 0, 0, 0, 0, 0,
0, 0, 0, 0, 0, 0, 0, 0, 0, 0, 0, 0, 0, 0, 0, 0, 0, 0, 0, 0,
0, 0, 0, 0, 0, 0, 0, 0, 0, 0, 0, 0, 0, 0, 0, 0, 0, 0, 0, 0,
0, 0, 0, 0, 0, 0, 0, 0, 0, 0, 0, 0, 0, 0, 0, 0, 0, 0, 0, 0,
0, 0, 0, 0, 0, 0, 0, 0, 0, 0, 0, 0, 0, 0, 0, 0, 0, 0, 0, 0,
0, 0, 0, 0, 0, 0, 0, 0, 0, 0, 0, 0, 0, 0, 0, 0, 0, 0, 0, 0,
0, 0, 0, 0, 0, 0, 0, 0, 0, 0, 0, 0, 0, 0, 0, 0, 0, 0, 0, 0,
0, 0, 0, 0, 0, 0, 0, 0, 0, 0, 0, 0, 0, 0, 0, 0, 0, 0, 0, 0,
0, 0, 0, 0, 0, 0, 0, 0, 0, 0, 0, 0, 0, 0, 0, 0, 0, 0, 0, 0,
0, 0, 0, 0, 0, 0, 0, 0, 0, 0, 0, 0, 0, 0, 0, 0, 0, 0, 0, 0,
0, 0, 0, 0, 0, 0, 0, 0, 0, 0, 0, 0, 0, 0, 0, 0, 0, 0, 0, 0,
0, 0, 0, 0, 0, 0, 0, 0, 0, 0, 0, 0, 0, 0, 0, 0, 0, 0, 0, 0,
0, 0, 0, 0, 0, 0, 0, 0, 0, 0, 0, 0, 0, 0, 0, 0, 0, 0, 0, 0,
0, 0, 0, 0, 0, 0, 0, 0, 0, 0, 0, 0, 0, 0, 0, 0, 0, 0, 0, 0,
0, 0, 0, 0, 0, 0, 0, 0, 0, 0, 0, 0, 0, 0, 0, 0, 0, 0, 0, 0,
0, 0, 0, 0, 0, 0, 0, 0, 0, 0, 0, 0, 0, 0, 0, 0, 0, 0, 0, 0,
0, 0, 0, 0, 0, 0, 0, 0, 0, 0, 0, 0, 0, 0, 0, 0, 0, 0, 0, 0,
0, 0, 0, 0, 0, 0, 0, 0, 0, 0, 0, 0, 0, 0, 0, 0, 0, 0, 0, 0,
0, 0, 0, 0, 0, 0, 0, 0, 0, 0, 0, 0, 0, 0, 0, 0, 0, 0, 0, 0,
0, 0, 0, 0, 0, 0, 0, 0, 0, 0, 0, 0, 0, 0, 0, 0, 0, 0, 0, 0,
0, 0, 0, 0, 0, 0, 0, 0, 0, 0, 0, 0, 0, 0, 0, 0, 0, 0, 0, 0,
0, 0, 0, 0, 0, 0, 0, 0, 0, 0, 0, 0, 0, 0, 0, 0, 0, 0, 0, 0,
0, 0, 0, 0, 0, 0, 0, 0, 0, 0, 0, 0, 0, 0, 0, 0, 0, 0, 0, 0,
0, 0, 0, 0, 0, 0, 0, 0, 0, 0, 0, 0, 0, 0, 0, 0, 0, 0, 0, 0,
0, 0, 0, 0, 0, 0, 0, 0, 0, 0, 0, 0, 0, 0, 0, 0, 0, 0, 0, 0,
0, 0, 0, 0, 0, 0, 0, 0, 0, 0, 0, 0, 0, 0, 0, 0, 0, 0, 0, 0,
0, 0, 0, 0, 0, 0, 0, 0, 0, 0, 0, 0, 0, 0, 0, 0, 0, 0, 0, 0,
0, 0, 0, 0, 0, 0, 0, 0, 0, 0, 0, 0, 0, 0, 0, 0, 0, 0, 0, 0,
0, 0, 0, 0, 0, 0, 0, 0, 0, 0, 0, 0, 0, 3, 12, 21, 29, 38, 47, 56,
65, 74, 82, 91, 100, 109, 118, 127, 136, 144, 153, 162, 171, 180, 188, 197, 206, 215, 224, 233,
241, 250, 259, 268, 277, 286, 294, 303, 312, 321, 330, 338, 347, 356, 365, 374, 383, 391, 400, 409,
418, 427, 435, 444, 453, 462, 471, 479, 488, 497, 506, 514, 523, 532, 541, 550, 558, 567, 576, 585,
593, 602, 611, 620, 628, 637, 646, 655, 663, 672, 681, 690, 698, 707, 716, 725, 733, 742, 751, 759,
768, 777, 786, 794, 803, 812, 820, 829, 838, 846, 855, 864, 872, 881, 890, 898, 907, 916, 924, 933,
942, 950, 959, 968, 976, 985, 993, 1002, 1011, 1019, 1028, 1036, 1045, 1054, 1062, 1071, 1079, 1088, 1097, 1105,
1114, 1122, 1131, 1139, 1148, 1157, 1165, 1174, 1182, 1191, 1199, 1208, 1216, 1225, 1233, 1242, 1250, 1259, 1267, 1276,
1284, 1293, 1301, 1309, 1318, 1326, 1335, 1343, 1352, 1360, 1369, 1377, 1385, 1394, 1402, 1411, 1419, 1427, 1436, 1444,
1452, 1461, 1469, 1478, 1486, 1494, 1503, 1511, 1519, 1528, 1536, 1544, 1552, 1561, 1569, 1577, 1586, 1594, 1602, 1610,
1619, 1627, 1635, 1643, 1652, 1660, 1668, 1676, 1684, 1693, 1701, 1709, 1717, 1725, 1733, 1742, 1750, 1758, 1766, 1774,
1782, 1790, 1799, 1807, 1815, 1823, 1831, 1839, 1847, 1855, 1863, 1871, 1879, 1887, 1895, 1903, 1911, 1919, 1927, 1935,
1943, 1951, 1959, 1967, 1975, 1983, 1991, 1999, 2007, 2015, 2023, 2030, 2038, 2046, 2054, 2062, 2070, 2078, 2085, 2093,
2101, 2109, 2117, 2124, 2132, 2140, 2148, 2156, 2163, 2171, 2179, 2187, 2194, 2202, 2210, 2217, 2225, 2233, 2240, 2248,
2256, 2263, 2271, 2279, 2286, 2294, 2301, 2309, 2317, 2324, 2332, 2339, 2347, 2354, 2362, 2369, 2377, 2384, 2392, 2399,
2407, 2414, 2422, 2429, 2437, 2444, 2452, 2459, 2466, 2474, 2481, 2488, 2496, 2503, 2511, 2518, 2525, 2533, 2540, 2547,
2554, 2562, 2569, 2576, 2583, 2591, 2598, 2605, 2612, 2619, 2627, 2634, 2641, 2648, 2655, 2662, 2670, 2677, 2684, 2691,
2698, 2705, 2712, 2719, 2726, 2733, 2740, 2747, 2754, 2761, 2768, 2775, 2782, 2789, 2796, 2803, 2810, 2817, 2824, 2830,
2837, 2844, 2851, 2858, 2865, 2871, 2878, 2885, 2892, 2899, 2905, 2912, 2919, 2926, 2932, 2939, 2946, 2952, 2959, 2966,
2972, 2979, 2985, 2992, 2999, 3005, 3012, 3018, 3025, 3032, 3038, 3045, 3051, 3058, 3064, 3070, 3077, 3083, 3090, 3096,
3103, 3109, 3115, 3122, 3128, 3134, 3141, 3147, 3153, 3160, 3166, 3172, 3179, 3185, 3191, 3197, 3204, 3210, 3216, 3222,
3228, 3234, 3241, 3247, 3253, 3259, 3265, 3271, 3277, 3283, 3289, 3295, 3301, 3307, 3313, 3319, 3325, 3331, 3337, 3343,
3349, 3355, 3361, 3367, 3372, 3378, 3384, 3390, 3396, 3401, 3407, 3413, 3419, 3425, 3430, 3436, 3442, 3447, 3453, 3459,
3464, 3470, 3476, 3481, 3487, 3492, 3498, 3503, 3509, 3515, 3520, 3526, 3531, 3537, 3542, 3547, 3553, 3558, 3564, 3569,
3574, 3580, 3585, 3591, 3596, 3601, 3606, 3612, 3617, 3622, 3627, 3633, 3638, 3643, 3648, 3653, 3659, 3664, 3669, 3674,
3679, 3684, 3689, 3694, 3699, 3704, 3709, 3714, 3719, 3724, 3729, 3734, 3739, 3744, 3749, 3754, 3759, 3764, 3768, 3773,
3778, 3783, 3788, 3792, 3797, 3802, 3807, 3811, 3816, 3821, 3825, 3830, 3835, 3839, 3844, 3848, 3853, 3857, 3862, 3867,
3871, 3876, 3880, 3885, 3889, 3893, 3898, 3902, 3907, 3911, 3915, 3920, 3924, 3928, 3933, 3937, 3941, 3946, 3950, 3954,
3958, 3962, 3967, 3971, 3975, 3979, 3983, 3987, 3991, 3995, 3999, 4004, 4008, 4012, 4016, 4020, 4024, 4027, 4031, 4035,
4039, 4043, 4047, 4051, 4055, 4059, 4062, 4066, 4070, 4074, 4077, 4081, 4085, 4089, 4092, 4096, 4100, 4103, 4107, 4110,
4114, 4118, 4121, 4125, 4128, 4132, 4135, 4139, 4142, 4146, 4149, 4152, 4156, 4159, 4163, 4166, 4169, 4173, 4176, 4179,
4182, 4186, 4189, 4192, 4195, 4199, 4202, 4205, 4208, 4211, 4214, 4217, 4220, 4223, 4227, 4230, 4233, 4236, 4239, 4241,
4244, 4247, 4250, 4253, 4256, 4259, 4262, 4265, 4267, 4270, 4273, 4276, 4278, 4281, 4284, 4287, 4289, 4292, 4295, 4297,
4300, 4302, 4305, 4308, 4310, 4313, 4315, 4318, 4320, 4323, 4325, 4328, 4330, 4332, 4335, 4337, 4339, 4342, 4344, 4346,
4349, 4351, 4353, 4355, 4358, 4360, 4362, 4364, 4366, 4368, 4371, 4373, 4375, 4377, 4379, 4381, 4383, 4385, 4387, 4389,
4391, 4393, 4395, 4396, 4398, 4400, 4402, 4404, 4406, 4407, 4409, 4411, 4413, 4414, 4416, 4418, 4420, 4421, 4423, 4424,
4426, 4428, 4429, 4431, 4432, 4434, 4435, 4437, 4438, 4440, 4441, 4443, 4444, 4445, 4447, 4448, 4449, 4451, 4452, 4453,
4455, 4456, 4457, 4458, 4459, 4461, 4462, 4463, 4464, 4465, 4466, 4467, 4468, 4469, 4470, 4471, 4472, 4473, 4474, 4475,
4476, 4477, 4478, 4479, 4480, 4480, 4481, 4482, 4483, 4484, 4484, 4485, 4486, 4487, 4487, 4488, 4488, 4489, 4490, 4490,
4491, 4491, 4492, 4492, 4493, 4493, 4494, 4494, 4495, 4495, 4496, 4496, 4496, 4497, 4497, 4497, 4498, 4498, 4498, 4498,
4499, 4499, 4499, 4499, 4499, 4500, 4500, 4500, 4500, 4500, 4500, 4500, 4500, 4500, 4500, 4500, 4500, 4500, 4500, 4500,
4500, 4499, 4499, 4499, 4499, 4499, 4498, 4498, 4498, 4498, 4497, 4497, 4497, 4496, 4496, 4496, 4495, 4495, 4494, 4494,
4493, 4493, 4492, 4492, 4491, 4491, 4490, 4490, 4489, 4488, 4488, 4487, 4486, 4486, 4485, 4484, 4484, 4483, 4482, 4481,
4480, 4480, 4479, 4478, 4477, 4476, 4475, 4474, 4473, 4472, 4471, 4470, 4469, 4468, 4467, 4466, 4465, 4464, 4463, 4462,
4460, 4459, 4458, 4457, 4456, 4454, 4453, 4452, 4451, 4449, 4448, 4447, 4445, 4444, 4442, 4441, 4439, 4438, 4437, 4435,
4434, 4432, 4431, 4429, 4427, 4426, 4424, 4423, 4421, 4419, 4418, 4416, 4414, 4412, 4411, 4409, 4407, 4405, 4404, 4402,
4400, 4398, 4396, 4394, 4392, 4390, 4388, 4387, 4385, 4383, 4381, 4378, 4376, 4374, 4372, 4370, 4368, 4366, 4364, 4362,
4359, 4357, 4355, 4353, 4351, 4348, 4346, 4344, 4341, 4339, 4337, 4334, 4332, 4330, 4327, 4325, 4322, 4320, 4317, 4315,
4312, 4310, 4307, 4305, 4302, 4299, 4297, 4294, 4292, 4289, 4286, 4283, 4281, 4278, 4275, 4273, 4270, 4267, 4264, 4261,
4258, 4256, 4253, 4250, 4247, 4244, 4241, 4238, 4235, 4232, 4229, 4226, 4223, 4220, 4217, 4214, 4211, 4207, 4204, 4201,
4198, 4195, 4192, 4188, 4185, 4182, 4179, 4175, 4172, 4169, 4165, 4162, 4159, 4155, 4152, 4148, 4145, 4142, 4138, 4135,
4131, 4128, 4124, 4121, 4117, 4113, 4110, 4106, 4103, 4099, 4095, 4092, 4088, 4084, 4081, 4077, 4073, 4069, 4065, 4062,
4058, 4054, 4050, 4046, 4042, 4039, 4035, 4031, 4027, 4023, 4019, 4015, 4011, 4007, 4003, 3999, 3995, 3991, 3987, 3982,
3978, 3974, 3970, 3966, 3962, 3958, 3953, 3949, 3945, 3941, 3936, 3932, 3928, 3923, 3919, 3915, 3910, 3906, 3902, 3897};

const uint16_t bangX2_5Hz[3200]={0, 0, 0, 0, 0, 0, 0, 0, 0, 0, 0, 0, 0, 0, 0, 0, 0, 0, 0, 0,
0, 0, 0, 0, 0, 0, 0, 0, 0, 0, 0, 0, 0, 0, 0, 0, 0, 0, 0, 0,
0, 0, 0, 0, 0, 0, 0, 0, 0, 0, 0, 0, 0, 0, 0, 0, 0, 0, 0, 0,
0, 0, 0, 0, 0, 0, 0, 0, 0, 0, 0, 0, 0, 0, 0, 0, 0, 0, 0, 0,
0, 0, 0, 0, 0, 0, 0, 0, 0, 0, 0, 0, 0, 0, 0, 0, 0, 0, 0, 0,
0, 0, 0, 0, 0, 0, 0, 0, 0, 0, 0, 0, 0, 0, 0, 0, 0, 0, 0, 0,
0, 0, 0, 0, 0, 0, 0, 0, 0, 0, 0, 0, 0, 0, 0, 0, 0, 0, 0, 0,
0, 0, 0, 0, 0, 0, 0, 0, 0, 0, 0, 0, 0, 0, 0, 0, 0, 0, 0, 0,
0, 0, 0, 0, 0, 0, 0, 0, 0, 0, 0, 0, 0, 0, 0, 0, 0, 0, 0, 0,
0, 0, 0, 0, 0, 0, 0, 0, 0, 0, 0, 0, 0, 0, 0, 0, 0, 0, 0, 0,
0, 0, 0, 0, 0, 0, 0, 0, 0, 0, 0, 0, 0, 0, 0, 0, 0, 0, 0, 0,
0, 0, 0, 0, 0, 0, 0, 0, 0, 0, 0, 0, 0, 0, 0, 0, 0, 0, 0, 0,
0, 0, 0, 0, 0, 0, 0, 0, 0, 0, 0, 0, 0, 0, 0, 0, 0, 0, 0, 0,
0, 0, 0, 0, 0, 0, 0, 0, 0, 0, 0, 0, 0, 0, 0, 0, 0, 0, 0, 0,
0, 0, 0, 0, 0, 0, 0, 0, 0, 0, 0, 0, 0, 0, 0, 0, 0, 0, 0, 0,
0, 0, 0, 0, 0, 0, 0, 0, 0, 0, 0, 0, 0, 0, 0, 0, 0, 0, 0, 0,
0, 0, 0, 0, 0, 0, 0, 0, 0, 0, 0, 0, 0, 0, 0, 0, 0, 0, 0, 0,
0, 0, 0, 0, 0, 0, 0, 0, 0, 0, 0, 0, 0, 0, 0, 0, 0, 0, 0, 0,
0, 0, 0, 0, 0, 0, 0, 0, 0, 0, 0, 0, 0, 0, 0, 0, 0, 0, 0, 0,
0, 0, 0, 0, 0, 0, 0, 0, 0, 0, 0, 0, 0, 0, 0, 0, 0, 0, 0, 0,
0, 0, 0, 0, 0, 0, 0, 0, 0, 0, 0, 0, 0, 0, 0, 0, 0, 0, 0, 0,
0, 0, 0, 0, 0, 0, 0, 0, 0, 0, 0, 0, 0, 0, 0, 0, 0, 0, 0, 0,
0, 0, 0, 0, 0, 0, 0, 0, 0, 0, 0, 0, 0, 0, 0, 0, 0, 0, 0, 0,
0, 0, 0, 0, 0, 0, 0, 0, 0, 0, 0, 0, 0, 0, 0, 0, 0, 0, 0, 0,
0, 0, 0, 0, 0, 0, 0, 0, 0, 0, 0, 0, 0, 0, 0, 0, 0, 0, 0, 0,
0, 0, 0, 0, 0, 0, 0, 0, 0, 0, 0, 0, 0, 0, 0, 0, 0, 0, 0, 0,
0, 0, 0, 0, 0, 0, 0, 0, 0, 0, 0, 0, 0, 0, 0, 0, 0, 0, 0, 0,
0, 0, 0, 0, 0, 0, 0, 0, 0, 0, 0, 0, 0, 0, 0, 0, 0, 0, 0, 0,
0, 0, 0, 0, 0, 0, 0, 0, 0, 0, 0, 0, 0, 0, 0, 0, 0, 0, 0, 0,
0, 0, 0, 0, 0, 0, 0, 0, 0, 0, 0, 0, 0, 0, 0, 0, 0, 0, 0, 0,
0, 0, 0, 0, 0, 0, 0, 0, 0, 0, 0, 0, 0, 0, 0, 0, 0, 0, 0, 0,
0, 0, 0, 0, 0, 0, 0, 0, 0, 0, 0, 0, 0, 0, 0, 0, 0, 0, 0, 0,
0, 0, 0, 0, 0, 0, 0, 0, 0, 0, 0, 0, 0, 0, 0, 0, 0, 0, 0, 0,
0, 0, 0, 0, 0, 0, 0, 0, 0, 0, 0, 0, 0, 0, 0, 0, 0, 0, 0, 0,
0, 0, 0, 0, 0, 0, 0, 0, 0, 0, 0, 0, 0, 0, 0, 0, 0, 0, 0, 0,
0, 0, 0, 0, 0, 0, 0, 0, 0, 0, 0, 0, 0, 0, 0, 0, 0, 0, 0, 0,
0, 0, 0, 0, 0, 0, 0, 0, 0, 0, 0, 0, 0, 0, 0, 0, 0, 0, 0, 0,
0, 0, 0, 0, 0, 0, 0, 0, 0, 0, 0, 0, 0, 0, 0, 0, 0, 0, 0, 0,
0, 0, 0, 0, 0, 0, 0, 0, 0, 0, 0, 0, 0, 0, 0, 0, 0, 0, 0, 0,
0, 0, 0, 0, 0, 0, 0, 0, 0, 0, 0, 0, 0, 0, 0, 0, 0, 0, 0, 0,
0, 0, 0, 0, 0, 0, 0, 0, 0, 0, 0, 0, 0, 0, 0, 0, 0, 0, 0, 0,
0, 0, 0, 0, 0, 0, 0, 0, 0, 0, 0, 0, 0, 0, 0, 0, 0, 0, 0, 0,
0, 0, 0, 0, 0, 0, 0, 0, 0, 0, 0, 0, 0, 0, 0, 0, 0, 0, 0, 0,
0, 0, 0, 0, 0, 0, 0, 0, 0, 0, 0, 0, 0, 0, 0, 0, 0, 0, 0, 0,
0, 0, 0, 0, 0, 0, 0, 0, 0, 0, 0, 0, 0, 0, 0, 0, 0, 0, 0, 0,
0, 0, 0, 0, 0, 0, 0, 0, 0, 0, 0, 0, 0, 0, 0, 0, 0, 0, 0, 0,
0, 0, 0, 0, 0, 0, 0, 0, 0, 0, 0, 0, 0, 0, 0, 0, 0, 0, 0, 0,
0, 0, 0, 0, 0, 0, 0, 0, 0, 0, 0, 0, 0, 0, 0, 0, 0, 0, 0, 0,
0, 0, 0, 0, 0, 0, 0, 0, 0, 0, 0, 0, 0, 0, 0, 0, 0, 0, 0, 0,
0, 0, 0, 0, 0, 0, 0, 0, 0, 0, 0, 0, 0, 0, 0, 0, 0, 0, 0, 0,
0, 0, 0, 0, 0, 0, 0, 0, 0, 0, 0, 0, 0, 0, 0, 0, 0, 0, 0, 0,
0, 0, 0, 0, 0, 0, 0, 0, 0, 0, 0, 0, 0, 0, 0, 0, 0, 0, 0, 0,
0, 0, 0, 0, 0, 0, 0, 0, 0, 0, 0, 0, 0, 0, 0, 0, 0, 0, 0, 0,
0, 0, 0, 0, 0, 0, 0, 0, 0, 0, 0, 0, 0, 0, 0, 0, 0, 0, 0, 0,
0, 0, 0, 0, 0, 0, 0, 0, 0, 0, 0, 0, 0, 0, 0, 0, 0, 0, 0, 0,
0, 0, 0, 0, 0, 0, 0, 0, 0, 0, 0, 0, 0, 0, 0, 0, 0, 0, 0, 0,
0, 0, 0, 0, 0, 0, 0, 0, 0, 0, 0, 0, 0, 0, 0, 0, 0, 0, 0, 0,
0, 0, 0, 0, 0, 0, 0, 0, 0, 0, 0, 0, 0, 0, 0, 0, 0, 0, 0, 0,
0, 0, 0, 0, 0, 0, 0, 0, 0, 0, 0, 0, 0, 0, 0, 0, 0, 0, 0, 0,
0, 0, 0, 0, 0, 0, 0, 0, 0, 0, 0, 0, 0, 0, 0, 0, 0, 0, 0, 0,
0, 0, 0, 0, 0, 0, 0, 0, 0, 0, 0, 0, 0, 0, 0, 0, 0, 0, 0, 0,
0, 0, 0, 0, 0, 0, 0, 0, 0, 0, 0, 0, 0, 0, 0, 0, 0, 0, 0, 0,
0, 0, 0, 0, 0, 0, 0, 0, 0, 0, 0, 0, 0, 0, 0, 0, 0, 0, 0, 0,
0, 0, 0, 0, 0, 0, 0, 0, 0, 0, 0, 0, 0, 0, 0, 0, 0, 0, 0, 0,
0, 0, 0, 0, 0, 0, 0, 0, 0, 0, 0, 0, 0, 0, 0, 0, 0, 0, 0, 0,
0, 0, 0, 0, 0, 0, 0, 0, 0, 0, 0, 0, 0, 0, 0, 0, 0, 0, 0, 0,
0, 0, 0, 0, 0, 0, 0, 0, 0, 0, 0, 0, 0, 0, 0, 0, 0, 0, 0, 0,
0, 0, 0, 0, 0, 0, 0, 0, 0, 0, 0, 0, 0, 0, 0, 0, 0, 0, 0, 0,
0, 0, 0, 0, 0, 0, 0, 0, 0, 0, 0, 0, 0, 0, 0, 0, 0, 0, 0, 0,
0, 0, 0, 0, 0, 0, 0, 0, 0, 0, 0, 0, 0, 0, 0, 0, 0, 0, 0, 0,
0, 0, 0, 0, 0, 0, 0, 0, 0, 0, 0, 0, 0, 0, 0, 0, 0, 0, 0, 0,
0, 0, 0, 0, 0, 0, 0, 0, 0, 0, 0, 0, 0, 0, 0, 0, 0, 0, 0, 0,
0, 0, 0, 0, 0, 0, 0, 0, 0, 0, 0, 0, 0, 0, 0, 0, 0, 0, 0, 0,
0, 0, 0, 0, 0, 0, 0, 0, 0, 0, 0, 0, 0, 0, 0, 0, 0, 0, 0, 0,
0, 0, 0, 0, 0, 0, 0, 0, 0, 0, 0, 0, 0, 0, 0, 0, 0, 0, 0, 0,
0, 0, 0, 0, 0, 0, 0, 0, 0, 0, 0, 0, 0, 0, 0, 0, 0, 0, 0, 0,
0, 0, 0, 0, 0, 0, 0, 0, 0, 0, 0, 0, 0, 0, 0, 0, 0, 0, 0, 0,
0, 0, 0, 0, 0, 0, 0, 0, 0, 0, 0, 0, 0, 0, 0, 0, 0, 0, 0, 0,
0, 0, 0, 0, 0, 0, 0, 0, 0, 0, 0, 0, 0, 0, 0, 0, 0, 0, 0, 0,
0, 0, 0, 0, 0, 0, 0, 0, 0, 0, 0, 0, 0, 0, 0, 0, 0, 0, 0, 0,
4, 13, 22, 31, 40, 49, 57, 66, 75, 84, 93, 102, 110, 119, 128, 137, 146, 155, 163, 172,
181, 190, 199, 208, 216, 225, 234, 243, 252, 261, 269, 278, 287, 296, 305, 314, 322, 331, 340, 349,
358, 366, 375, 384, 393, 402, 410, 419, 428, 437, 446, 454, 463, 472, 481, 490, 498, 507, 516, 525,
533, 542, 551, 560, 569, 577, 586, 595, 604, 612, 621, 630, 639, 647, 656, 665, 674, 682, 691, 700,
709, 717, 726, 735, 743, 752, 761, 770, 778, 787, 796, 804, 813, 822, 830, 839, 848, 856, 865, 874,
883, 891, 900, 908, 917, 926, 934, 943, 952, 960, 969, 978, 986, 995, 1003, 1012, 1021, 1029, 1038, 1047,
1055, 1064, 1072, 1081, 1089, 1098, 1107, 1115, 1124, 1132, 1141, 1149, 1158, 1166, 1175, 1184, 1192, 1201, 1209, 1218,
1226, 1235, 1243, 1252, 1260, 1269, 1277, 1286, 1294, 1302, 1311, 1319, 1328, 1336, 1345, 1353, 1362, 1370, 1378, 1387,
1395, 1404, 1412, 1420, 1429, 1437, 1446, 1454, 1462, 1471, 1479, 1487, 1496, 1504, 1512, 1521, 1529, 1537, 1546, 1554,
1562, 1570, 1579, 1587, 1595, 1604, 1612, 1620, 1628, 1636, 1645, 1653, 1661, 1669, 1678, 1686, 1694, 1702, 1710, 1719,
1727, 1735, 1743, 1751, 1759, 1767, 1776, 1784, 1792, 1800, 1808, 1816, 1824, 1832, 1840, 1848, 1856, 1864, 1872, 1881,
1889, 1897, 1905, 1913, 1921, 1929, 1937, 1945, 1952, 1960, 1968, 1976, 1984, 1992, 2000, 2008, 2016, 2024, 2032, 2040,
2047, 2055, 2063, 2071, 2079, 2087, 2095, 2102, 2110, 2118, 2126, 2134, 2141, 2149, 2157, 2165, 2172, 2180, 2188, 2196,
2203, 2211, 2219, 2226, 2234, 2242, 2249, 2257, 2265, 2272, 2280, 2288, 2295, 2303, 2310, 2318, 2325, 2333, 2341, 2348,
2356, 2363, 2371, 2378, 2386, 2393, 2401, 2408, 2416, 2423, 2431, 2438, 2445, 2453, 2460, 2468, 2475, 2482, 2490, 2497,
2504, 2512, 2519, 2526, 2534, 2541, 2548, 2556, 2563, 2570, 2577, 2585, 2592, 2599, 2606, 2613, 2621, 2628, 2635, 2642,
2649, 2656, 2664, 2671, 2678, 2685, 2692, 2699, 2706, 2713, 2720, 2727, 2734, 2741, 2748, 2755, 2762, 2769, 2776, 2783,
2790, 2797, 2804, 2811, 2818, 2825, 2832, 2838, 2845, 2852, 2859, 2866, 2873, 2879, 2886, 2893, 2900, 2906, 2913, 2920,
2927, 2933, 2940, 2947, 2953, 2960, 2967, 2973, 2980, 2987, 2993, 3000, 3006, 3013, 3020, 3026, 3033, 3039, 3046, 3052,
3059, 3065, 3072, 3078, 3084, 3091, 3097, 3104, 3110, 3116, 3123, 3129, 3136, 3142, 3148, 3155, 3161, 3167, 3173, 3180,
3186, 3192, 3198, 3205, 3211, 3217, 3223, 3229, 3235, 3242, 3248, 3254, 3260, 3266, 3272, 3278, 3284, 3290, 3296, 3302,
3308, 3314, 3320, 3326, 3332, 3338, 3344, 3350, 3356, 3362, 3368, 3373, 3379, 3385, 3391, 3397, 3402, 3408, 3414, 3420,
3425, 3431, 3437, 3443, 3448, 3454, 3460, 3465, 3471, 3477, 3482, 3488, 3493, 3499, 3504, 3510, 3515, 3521, 3526, 3532,
3537, 3543, 3548, 3554, 3559, 3565, 3570, 3575, 3581, 3586, 3591, 3597, 3602, 3607, 3613, 3618, 3623, 3628, 3634, 3639,
3644, 3649, 3654, 3659, 3665, 3670, 3675, 3680, 3685, 3690, 3695, 3700, 3705, 3710, 3715, 3720, 3725, 3730, 3735, 3740,
3745, 3750, 3755, 3759, 3764, 3769, 3774, 3779, 3784, 3788, 3793, 3798, 3803, 3807, 3812, 3817, 3821, 3826, 3831, 3835,
3840, 3845, 3849, 3854, 3858, 3863, 3867, 3872, 3876, 3881, 3885, 3890, 3894, 3899, 3903, 3907, 3912, 3916, 3920, 3925,
3929, 3933, 3938, 3942, 3946, 3950, 3955, 3959, 3963, 3967, 3971, 3976, 3980, 3984, 3988, 3992, 3996, 4000, 4004, 4008,
4012, 4016, 4020, 4024, 4028, 4032, 4036, 4040, 4044, 4048, 4051, 4055, 4059, 4063, 4067, 4071, 4074, 4078, 4082, 4085,
4089, 4093, 4097, 4100, 4104, 4107, 4111, 4115, 4118, 4122, 4125, 4129, 4132, 4136, 4139, 4143, 4146, 4150, 4153, 4156,
4160, 4163, 4166, 4170, 4173, 4176, 4180, 4183, 4186, 4189, 4193, 4196, 4199, 4202, 4205, 4209, 4212, 4215, 4218, 4221,
4224, 4227, 4230, 4233, 4236, 4239, 4242, 4245, 4248, 4251, 4254, 4257, 4259, 4262, 4265, 4268, 4271, 4273, 4276, 4279,
4282, 4284, 4287, 4290, 4292, 4295, 4298, 4300, 4303, 4305, 4308, 4311, 4313, 4316, 4318, 4321, 4323, 4326, 4328, 4330,
4333, 4335, 4337, 4340, 4342, 4344, 4347, 4349, 4351, 4354, 4356, 4358, 4360, 4362, 4365, 4367, 4369, 4371, 4373, 4375,
4377, 4379, 4381, 4383, 4385, 4387, 4389, 4391, 4393, 4395, 4397, 4399, 4401, 4402, 4404, 4406, 4408, 4410, 4411, 4413,
4415, 4416, 4418, 4420, 4421, 4423, 4425, 4426, 4428, 4429, 4431, 4433, 4434, 4436, 4437, 4439, 4440, 4441, 4443, 4444,
4446, 4447, 4448, 4450, 4451, 4452, 4454, 4455, 4456, 4457, 4458, 4460, 4461, 4462, 4463, 4464, 4465, 4466, 4467, 4469,
4470, 4471, 4472, 4473, 4474, 4474, 4475, 4476, 4477, 4478, 4479, 4480, 4481, 4481, 4482, 4483, 4484, 4485, 4485, 4486,
4487, 4487, 4488, 4489, 4489, 4490, 4490, 4491, 4492, 4492, 4493, 4493, 4494, 4494, 4494, 4495, 4495, 4496, 4496, 4496,
4497, 4497, 4497, 4498, 4498, 4498, 4498, 4499, 4499, 4499, 4499, 4499, 4500, 4500, 4500, 4500, 4500, 4500, 4500, 4500,
4500, 4500, 4500, 4500, 4500, 4500, 4500, 4499, 4499, 4499, 4499, 4499, 4499, 4498, 4498, 4498, 4498, 4497, 4497, 4497,
4496, 4496, 4496, 4495, 4495, 4494, 4494, 4493, 4493, 4492, 4492, 4491, 4491, 4490, 4490, 4489, 4488, 4488, 4487, 4486,
4486, 4485, 4484, 4483, 4483, 4482, 4481, 4480, 4479, 4479, 4478, 4477, 4476, 4475, 4474, 4473, 4472, 4471, 4470, 4469,
4468, 4467, 4466, 4465, 4464, 4463, 4461, 4460, 4459, 4458, 4457, 4455, 4454, 4453, 4452, 4450, 4449, 4448, 4446, 4445,
4444, 4442, 4441, 4439, 4438, 4436, 4435, 4433, 4432, 4430, 4429, 4427, 4426, 4424, 4422, 4421, 4419, 4417, 4416, 4414,
4412, 4410, 4409, 4407, 4405, 4403, 4401, 4400, 4398, 4396, 4394, 4392, 4390, 4388, 4386, 4384, 4382, 4380, 4378, 4376,
4374, 4372, 4370, 4368, 4366, 4363, 4361, 4359, 4357, 4355, 4352, 4350, 4348, 4346, 4343, 4341, 4339, 4336, 4334, 4332,
4329, 4327, 4324, 4322, 4319, 4317, 4314, 4312, 4309, 4307, 4304, 4302, 4299, 4296, 4294, 4291, 4288, 4286, 4283, 4280,
4278, 4275, 4272, 4269, 4266, 4264, 4261, 4258, 4255, 4252, 4249, 4246, 4243, 4240, 4238, 4235, 4232, 4229, 4226, 4222,
4219, 4216, 4213, 4210, 4207, 4204, 4201, 4197, 4194, 4191, 4188, 4185, 4181, 4178, 4175, 4171, 4168, 4165, 4161, 4158,
4155, 4151, 4148, 4144, 4141, 4138, 4134, 4131, 4127, 4123, 4120, 4116, 4113, 4109, 4106, 4102, 4098, 4095, 4091, 4087,
4084, 4080, 4076, 4072, 4069, 4065, 4061, 4057, 4053, 4050, 4046, 4042, 4038, 4034, 4030, 4026, 4022, 4018, 4014, 4010,
4006, 4002, 3998, 3994, 3990, 3986, 3982, 3978, 3974, 3969, 3965, 3961, 3957, 3953, 3948, 3944, 3940, 3936, 3931, 3927,
3923, 3918, 3914, 3910, 3905, 3901, 3896, 3892, 3888, 3883, 3879, 3874, 3870, 3865, 3861, 3856, 3851, 3847, 3842, 3838,
3833, 3828, 3824, 3819, 3814, 3810, 3805, 3800, 3795, 3791, 3786, 3781, 3776, 3772, 3767, 3762, 3757, 3752, 3747, 3742,
3737, 3733, 3728, 3723, 3718, 3713, 3708, 3703, 3698, 3693, 3688, 3682, 3677, 3672, 3667, 3662, 3657, 3652, 3647, 3641,
3636, 3631, 3626, 3620, 3615, 3610, 3605, 3599, 3594, 3589, 3583, 3578, 3573, 3567, 3562, 3556, 3551, 3546, 3540, 3535,
3529, 3524, 3518, 3513, 3507, 3502, 3496, 3491, 3485, 3479, 3474, 3468, 3462, 3457, 3451, 3445, 3440, 3434, 3428, 3423,
3417, 3411, 3405, 3400, 3394, 3388, 3382, 3376, 3370, 3365, 3359, 3353, 3347, 3341, 3335, 3329, 3323, 3317, 3311, 3305,
3299, 3293, 3287, 3281, 3275, 3269, 3263, 3257, 3251, 3245, 3238, 3232, 3226, 3220, 3214, 3208, 3201, 3195, 3189, 3183,
3177, 3170, 3164, 3158, 3151, 3145, 3139, 3132, 3126, 3120, 3113, 3107, 3101, 3094, 3088, 3081, 3075, 3068, 3062, 3055,
3049, 3042, 3036, 3029, 3023, 3016, 3010, 3003, 2996, 2990, 2983, 2977, 2970, 2963, 2957, 2950, 2943, 2937, 2930, 2923,
2917, 2910, 2903, 2896, 2890, 2883, 2876, 2869, 2862, 2856, 2849, 2842, 2835, 2828, 2821, 2814, 2807, 2801, 2794, 2787,
2780, 2773, 2766, 2759, 2752, 2745, 2738, 2731, 2724, 2717, 2710, 2703, 2696, 2688, 2681, 2674, 2667, 2660, 2653, 2646,
2639, 2631, 2624, 2617, 2610, 2603, 2595, 2588, 2581, 2574, 2566, 2559, 2552, 2545, 2537, 2530, 2523, 2515, 2508, 2501,
2493, 2486, 2479, 2471, 2464, 2456, 2449, 2442, 2434, 2427, 2419, 2412, 2404, 2397, 2389, 2382, 2374, 2367, 2359, 2352,
2344, 2337, 2329, 2322, 2314, 2307, 2299, 2291, 2284, 2276, 2268, 2261, 2253, 2246, 2238, 2230, 2223, 2215, 2207, 2199,
2192, 2184, 2176, 2169, 2161, 2153, 2145, 2137, 2130, 2122, 2114, 2106, 2098, 2091, 2083, 2075, 2067, 2059, 2051, 2044,
2036, 2028, 2020, 2012, 2004, 1996, 1988, 1980, 1972, 1964, 1956, 1948, 1941, 1933, 1925, 1917, 1909, 1901, 1893, 1885,
1876, 1868, 1860, 1852, 1844, 1836, 1828, 1820, 1812, 1804, 1796, 1788, 1780, 1771, 1763, 1755, 1747, 1739, 1731, 1723,
1714, 1706, 1698, 1690, 1682, 1673, 1665, 1657, 1649, 1641, 1632, 1624, 1616, 1608, 1599, 1591, 1583, 1575, 1566, 1558,
1550, 1541, 1533, 1525, 1516, 1508, 1500, 1491, 1483, 1475, 1466, 1458, 1450, 1441, 1433, 1425, 1416, 1408, 1399, 1391,
1383, 1374, 1366, 1357, 1349, 1340, 1332, 1324, 1315, 1307, 1298, 1290, 1281, 1273, 1264, 1256, 1247, 1239, 1230, 1222,
1213, 1205, 1196, 1188, 1179, 1171, 1162, 1154, 1145, 1137, 1128, 1119, 1111, 1102, 1094, 1085, 1077, 1068, 1059, 1051,
1042, 1034, 1025, 1016, 1008, 999, 991, 982, 973, 965, 956, 947, 939, 930, 921, 913, 904, 896, 887, 878,
870, 861, 852, 843, 835, 826, 817, 809, 800, 791, 783, 774, 765, 757, 748, 739, 730, 722, 713, 704,
695, 687, 678, 669, 660, 652, 643, 634, 626, 617, 608, 599, 590, 582, 573, 564, 555, 547, 538, 529,
520, 512, 503, 494, 485, 476, 468, 459, 450, 441, 432, 424, 415, 406, 397, 388, 380, 371, 362, 353,
344, 336, 327, 318, 309, 300, 291, 283, 274, 265, 256, 247, 239, 230, 221, 212, 203, 194, 186, 177,
168, 159, 150, 141, 133, 124, 115, 106, 97, 88, 80, 71, 62, 53, 44, 35, 27, 18, 9, 0};

const uint16_t bangY2_5Hz[3200]={3897, 3902, 3906, 3910, 3915, 3919, 3923, 3928, 3932, 3936, 3941, 3945, 3949, 3953, 3958, 3962, 3966, 3970, 3974, 3978,
3982, 3987, 3991, 3995, 3999, 4003, 4007, 4011, 4015, 4019, 4023, 4027, 4031, 4035, 4039, 4042, 4046, 4050, 4054, 4058,
4062, 4065, 4069, 4073, 4077, 4081, 4084, 4088, 4092, 4095, 4099, 4103, 4106, 4110, 4113, 4117, 4121, 4124, 4128, 4131,
4135, 4138, 4142, 4145, 4148, 4152, 4155, 4159, 4162, 4165, 4169, 4172, 4175, 4179, 4182, 4185, 4188, 4192, 4195, 4198,
4201, 4204, 4207, 4211, 4214, 4217, 4220, 4223, 4226, 4229, 4232, 4235, 4238, 4241, 4244, 4247, 4250, 4253, 4256, 4258,
4261, 4264, 4267, 4270, 4273, 4275, 4278, 4281, 4283, 4286, 4289, 4292, 4294, 4297, 4299, 4302, 4305, 4307, 4310, 4312,
4315, 4317, 4320, 4322, 4325, 4327, 4330, 4332, 4334, 4337, 4339, 4341, 4344, 4346, 4348, 4351, 4353, 4355, 4357, 4359,
4362, 4364, 4366, 4368, 4370, 4372, 4374, 4376, 4378, 4381, 4383, 4385, 4387, 4388, 4390, 4392, 4394, 4396, 4398, 4400,
4402, 4404, 4405, 4407, 4409, 4411, 4412, 4414, 4416, 4418, 4419, 4421, 4423, 4424, 4426, 4427, 4429, 4431, 4432, 4434,
4435, 4437, 4438, 4439, 4441, 4442, 4444, 4445, 4447, 4448, 4449, 4451, 4452, 4453, 4454, 4456, 4457, 4458, 4459, 4460,
4462, 4463, 4464, 4465, 4466, 4467, 4468, 4469, 4470, 4471, 4472, 4473, 4474, 4475, 4476, 4477, 4478, 4479, 4480, 4480,
4481, 4482, 4483, 4484, 4484, 4485, 4486, 4486, 4487, 4488, 4488, 4489, 4490, 4490, 4491, 4491, 4492, 4492, 4493, 4493,
4494, 4494, 4495, 4495, 4496, 4496, 4496, 4497, 4497, 4497, 4498, 4498, 4498, 4498, 4499, 4499, 4499, 4499, 4499, 4500,
4500, 4500, 4500, 4500, 4500, 4500, 4500, 4500, 4500, 4500, 4500, 4500, 4500, 4500, 4500, 4499, 4499, 4499, 4499, 4499,
4498, 4498, 4498, 4498, 4497, 4497, 4497, 4496, 4496, 4496, 4495, 4495, 4494, 4494, 4493, 4493, 4492, 4492, 4491, 4491,
4490, 4490, 4489, 4488, 4488, 4487, 4487, 4486, 4485, 4484, 4484, 4483, 4482, 4481, 4480, 4480, 4479, 4478, 4477, 4476,
4475, 4474, 4473, 4472, 4471, 4470, 4469, 4468, 4467, 4466, 4465, 4464, 4463, 4462, 4461, 4459, 4458, 4457, 4456, 4455,
4453, 4452, 4451, 4449, 4448, 4447, 4445, 4444, 4443, 4441, 4440, 4438, 4437, 4435, 4434, 4432, 4431, 4429, 4428, 4426,
4424, 4423, 4421, 4420, 4418, 4416, 4414, 4413, 4411, 4409, 4407, 4406, 4404, 4402, 4400, 4398, 4396, 4395, 4393, 4391,
4389, 4387, 4385, 4383, 4381, 4379, 4377, 4375, 4373, 4371, 4368, 4366, 4364, 4362, 4360, 4358, 4355, 4353, 4351, 4349,
4346, 4344, 4342, 4339, 4337, 4335, 4332, 4330, 4328, 4325, 4323, 4320, 4318, 4315, 4313, 4310, 4308, 4305, 4302, 4300,
4297, 4295, 4292, 4289, 4287, 4284, 4281, 4278, 4276, 4273, 4270, 4267, 4265, 4262, 4259, 4256, 4253, 4250, 4247, 4244,
4241, 4239, 4236, 4233, 4230, 4227, 4223, 4220, 4217, 4214, 4211, 4208, 4205, 4202, 4199, 4195, 4192, 4189, 4186, 4182,
4179, 4176, 4173, 4169, 4166, 4163, 4159, 4156, 4152, 4149, 4146, 4142, 4139, 4135, 4132, 4128, 4125, 4121, 4118, 4114,
4110, 4107, 4103, 4100, 4096, 4092, 4089, 4085, 4081, 4077, 4074, 4070, 4066, 4062, 4059, 4055, 4051, 4047, 4043, 4039,
4035, 4031, 4027, 4024, 4020, 4016, 4012, 4008, 4004, 3999, 3995, 3991, 3987, 3983, 3979, 3975, 3971, 3967, 3962, 3958,
3954, 3950, 3946, 3941, 3937, 3933, 3928, 3924, 3920, 3915, 3911, 3907, 3902, 3898, 3893, 3889, 3885, 3880, 3876, 3871,
3867, 3862, 3857, 3853, 3848, 3844, 3839, 3835, 3830, 3825, 3821, 3816, 3811, 3807, 3802, 3797, 3792, 3788, 3783, 3778,
3773, 3768, 3764, 3759, 3754, 3749, 3744, 3739, 3734, 3729, 3724, 3719, 3714, 3709, 3704, 3699, 3694, 3689, 3684, 3679,
3674, 3669, 3664, 3659, 3653, 3648, 3643, 3638, 3633, 3627, 3622, 3617, 3612, 3606, 3601, 3596, 3591, 3585, 3580, 3574,
3569, 3564, 3558, 3553, 3547, 3542, 3537, 3531, 3526, 3520, 3515, 3509, 3503, 3498, 3492, 3487, 3481, 3476, 3470, 3464,
3459, 3453, 3447, 3442, 3436, 3430, 3425, 3419, 3413, 3407, 3401, 3396, 3390, 3384, 3378, 3372, 3367, 3361, 3355, 3349,
3343, 3337, 3331, 3325, 3319, 3313, 3307, 3301, 3295, 3289, 3283, 3277, 3271, 3265, 3259, 3253, 3247, 3241, 3234, 3228,
3222, 3216, 3210, 3204, 3197, 3191, 3185, 3179, 3172, 3166, 3160, 3153, 3147, 3141, 3134, 3128, 3122, 3115, 3109, 3103,
3096, 3090, 3083, 3077, 3070, 3064, 3058, 3051, 3045, 3038, 3032, 3025, 3018, 3012, 3005, 2999, 2992, 2985, 2979, 2972,
2966, 2959, 2952, 2946, 2939, 2932, 2926, 2919, 2912, 2905, 2899, 2892, 2885, 2878, 2871, 2865, 2858, 2851, 2844, 2837,
2830, 2824, 2817, 2810, 2803, 2796, 2789, 2782, 2775, 2768, 2761, 2754, 2747, 2740, 2733, 2726, 2719, 2712, 2705, 2698,
2691, 2684, 2677, 2670, 2662, 2655, 2648, 2641, 2634, 2627, 2619, 2612, 2605, 2598, 2591, 2583, 2576, 2569, 2562, 2554,
2547, 2540, 2533, 2525, 2518, 2511, 2503, 2496, 2488, 2481, 2474, 2466, 2459, 2452, 2444, 2437, 2429, 2422, 2414, 2407,
2399, 2392, 2384, 2377, 2369, 2362, 2354, 2347, 2339, 2332, 2324, 2317, 2309, 2301, 2294, 2286, 2279, 2271, 2263, 2256,
2248, 2240, 2233, 2225, 2217, 2210, 2202, 2194, 2187, 2179, 2171, 2163, 2156, 2148, 2140, 2132, 2124, 2117, 2109, 2101,
2093, 2085, 2078, 2070, 2062, 2054, 2046, 2038, 2030, 2023, 2015, 2007, 1999, 1991, 1983, 1975, 1967, 1959, 1951, 1943,
1935, 1927, 1919, 1911, 1903, 1895, 1887, 1879, 1871, 1863, 1855, 1847, 1839, 1831, 1823, 1815, 1807, 1799, 1790, 1782,
1774, 1766, 1758, 1750, 1742, 1733, 1725, 1717, 1709, 1701, 1693, 1684, 1676, 1668, 1660, 1652, 1643, 1635, 1627, 1619,
1610, 1602, 1594, 1586, 1577, 1569, 1561, 1552, 1544, 1536, 1528, 1519, 1511, 1503, 1494, 1486, 1478, 1469, 1461, 1452,
1444, 1436, 1427, 1419, 1411, 1402, 1394, 1385, 1377, 1369, 1360, 1352, 1343, 1335, 1326, 1318, 1309, 1301, 1293, 1284,
1276, 1267, 1259, 1250, 1242, 1233, 1225, 1216, 1208, 1199, 1191, 1182, 1174, 1165, 1157, 1148, 1139, 1131, 1122, 1114,
1105, 1097, 1088, 1079, 1071, 1062, 1054, 1045, 1036, 1028, 1019, 1011, 1002, 993, 985, 976, 968, 959, 950, 942,
933, 924, 916, 907, 898, 890, 881, 872, 864, 855, 846, 838, 829, 820, 812, 803, 794, 786, 777, 768,
759, 751, 742, 733, 725, 716, 707, 698, 690, 681, 672, 663, 655, 646, 637, 628, 620, 611, 602, 593,
585, 576, 567, 558, 550, 541, 532, 523, 514, 506, 497, 488, 479, 471, 462, 453, 444, 435, 427, 418,
409, 400, 391, 383, 374, 365, 356, 347, 338, 330, 321, 312, 303, 294, 286, 277, 268, 259, 250, 241,
233, 224, 215, 206, 197, 188, 180, 171, 162, 153, 144, 136, 127, 118, 109, 100, 91, 82, 74, 65,
56, 47, 38, 29, 21, 12, 3, 0, 0, 0, 0, 0, 0, 0, 0, 0, 0, 0, 0, 0,
0, 0, 0, 0, 0, 0, 0, 0, 0, 0, 0, 0, 0, 0, 0, 0, 0, 0, 0, 0,
0, 0, 0, 0, 0, 0, 0, 0, 0, 0, 0, 0, 0, 0, 0, 0, 0, 0, 0, 0,
0, 0, 0, 0, 0, 0, 0, 0, 0, 0, 0, 0, 0, 0, 0, 0, 0, 0, 0, 0,
0, 0, 0, 0, 0, 0, 0, 0, 0, 0, 0, 0, 0, 0, 0, 0, 0, 0, 0, 0,
0, 0, 0, 0, 0, 0, 0, 0, 0, 0, 0, 0, 0, 0, 0, 0, 0, 0, 0, 0,
0, 0, 0, 0, 0, 0, 0, 0, 0, 0, 0, 0, 0, 0, 0, 0, 0, 0, 0, 0,
0, 0, 0, 0, 0, 0, 0, 0, 0, 0, 0, 0, 0, 0, 0, 0, 0, 0, 0, 0,
0, 0, 0, 0, 0, 0, 0, 0, 0, 0, 0, 0, 0, 0, 0, 0, 0, 0, 0, 0,
0, 0, 0, 0, 0, 0, 0, 0, 0, 0, 0, 0, 0, 0, 0, 0, 0, 0, 0, 0,
0, 0, 0, 0, 0, 0, 0, 0, 0, 0, 0, 0, 0, 0, 0, 0, 0, 0, 0, 0,
0, 0, 0, 0, 0, 0, 0, 0, 0, 0, 0, 0, 0, 0, 0, 0, 0, 0, 0, 0,
0, 0, 0, 0, 0, 0, 0, 0, 0, 0, 0, 0, 0, 0, 0, 0, 0, 0, 0, 0,
0, 0, 0, 0, 0, 0, 0, 0, 0, 0, 0, 0, 0, 0, 0, 0, 0, 0, 0, 0,
0, 0, 0, 0, 0, 0, 0, 0, 0, 0, 0, 0, 0, 0, 0, 0, 0, 0, 0, 0,
0, 0, 0, 0, 0, 0, 0, 0, 0, 0, 0, 0, 0, 0, 0, 0, 0, 0, 0, 0,
0, 0, 0, 0, 0, 0, 0, 0, 0, 0, 0, 0, 0, 0, 0, 0, 0, 0, 0, 0,
0, 0, 0, 0, 0, 0, 0, 0, 0, 0, 0, 0, 0, 0, 0, 0, 0, 0, 0, 0,
0, 0, 0, 0, 0, 0, 0, 0, 0, 0, 0, 0, 0, 0, 0, 0, 0, 0, 0, 0,
0, 0, 0, 0, 0, 0, 0, 0, 0, 0, 0, 0, 0, 0, 0, 0, 0, 0, 0, 0,
0, 0, 0, 0, 0, 0, 0, 0, 0, 0, 0, 0, 0, 0, 0, 0, 0, 0, 0, 0,
0, 0, 0, 0, 0, 0, 0, 0, 0, 0, 0, 0, 0, 0, 0, 0, 0, 0, 0, 0,
0, 0, 0, 0, 0, 0, 0, 0, 0, 0, 0, 0, 0, 0, 0, 0, 0, 0, 0, 0,
0, 0, 0, 0, 0, 0, 0, 0, 0, 0, 0, 0, 0, 0, 0, 0, 0, 0, 0, 0,
0, 0, 0, 0, 0, 0, 0, 0, 0, 0, 0, 0, 0, 0, 0, 0, 0, 0, 0, 0,
0, 0, 0, 0, 0, 0, 0, 0, 0, 0, 0, 0, 0, 0, 0, 0, 0, 0, 0, 0,
0, 0, 0, 0, 0, 0, 0, 0, 0, 0, 0, 0, 0, 0, 0, 0, 0, 0, 0, 0,
0, 0, 0, 0, 0, 0, 0, 0, 0, 0, 0, 0, 0, 0, 0, 0, 0, 0, 0, 0,
0, 0, 0, 0, 0, 0, 0, 0, 0, 0, 0, 0, 0, 0, 0, 0, 0, 0, 0, 0,
0, 0, 0, 0, 0, 0, 0, 0, 0, 0, 0, 0, 0, 0, 0, 0, 0, 0, 0, 0,
0, 0, 0, 0, 0, 0, 0, 0, 0, 0, 0, 0, 0, 0, 0, 0, 0, 0, 0, 0,
0, 0, 0, 0, 0, 0, 0, 0, 0, 0, 0, 0, 0, 0, 0, 0, 0, 0, 0, 0,
0, 0, 0, 0, 0, 0, 0, 0, 0, 0, 0, 0, 0, 0, 0, 0, 0, 0, 0, 0,
0, 0, 0, 0, 0, 0, 0, 0, 0, 0, 0, 0, 0, 0, 0, 0, 0, 0, 0, 0,
0, 0, 0, 0, 0, 0, 0, 0, 0, 0, 0, 0, 0, 0, 0, 0, 0, 0, 0, 0,
0, 0, 0, 0, 0, 0, 0, 0, 0, 0, 0, 0, 0, 0, 0, 0, 0, 0, 0, 0,
0, 0, 0, 0, 0, 0, 0, 0, 0, 0, 0, 0, 0, 0, 0, 0, 0, 0, 0, 0,
0, 0, 0, 0, 0, 0, 0, 0, 0, 0, 0, 0, 0, 0, 0, 0, 0, 0, 0, 0,
0, 0, 0, 0, 0, 0, 0, 0, 0, 0, 0, 0, 0, 0, 0, 0, 0, 0, 0, 0,
0, 0, 0, 0, 0, 0, 0, 0, 0, 0, 0, 0, 0, 0, 0, 0, 0, 0, 0, 0,
0, 0, 0, 0, 0, 0, 0, 0, 0, 0, 0, 0, 0, 0, 0, 0, 0, 0, 0, 0,
0, 0, 0, 0, 0, 0, 0, 0, 0, 0, 0, 0, 0, 0, 0, 0, 0, 0, 0, 0,
0, 0, 0, 0, 0, 0, 0, 0, 0, 0, 0, 0, 0, 0, 0, 0, 0, 0, 0, 0,
0, 0, 0, 0, 0, 0, 0, 0, 0, 0, 0, 0, 0, 0, 0, 0, 0, 0, 0, 0,
0, 0, 0, 0, 0, 0, 0, 0, 0, 0, 0, 0, 0, 0, 0, 0, 0, 0, 0, 0,
0, 0, 0, 0, 0, 0, 0, 0, 0, 0, 0, 0, 0, 0, 0, 0, 0, 0, 0, 0,
0, 0, 0, 0, 0, 0, 0, 0, 0, 0, 0, 0, 0, 0, 0, 0, 0, 0, 0, 0,
0, 0, 0, 0, 0, 0, 0, 0, 0, 0, 0, 0, 0, 0, 0, 0, 0, 0, 0, 0,
0, 0, 0, 0, 0, 0, 0, 0, 0, 0, 0, 0, 0, 0, 0, 0, 0, 0, 0, 0,
0, 0, 0, 0, 0, 0, 0, 0, 0, 0, 0, 0, 0, 0, 0, 0, 0, 0, 0, 0,
0, 0, 0, 0, 0, 0, 0, 0, 0, 0, 0, 0, 0, 0, 0, 0, 0, 0, 0, 0,
0, 0, 0, 0, 0, 0, 0, 0, 0, 0, 0, 0, 0, 0, 0, 0, 0, 0, 0, 0,
0, 0, 0, 0, 0, 0, 0, 0, 0, 0, 0, 0, 0, 0, 0, 0, 0, 0, 0, 0,
0, 0, 0, 0, 0, 0, 0, 0, 0, 0, 0, 0, 0, 0, 0, 0, 0, 0, 0, 0,
0, 0, 0, 0, 0, 0, 0, 0, 0, 0, 0, 0, 0, 0, 0, 0, 0, 0, 0, 0,
0, 0, 0, 0, 0, 0, 0, 0, 0, 0, 0, 0, 0, 0, 0, 0, 0, 0, 0, 0,
0, 0, 0, 0, 0, 0, 0, 0, 0, 0, 0, 0, 0, 0, 0, 0, 0, 0, 0, 0,
0, 0, 0, 0, 0, 0, 0, 0, 0, 0, 0, 0, 0, 0, 0, 0, 0, 0, 0, 0,
0, 0, 0, 0, 0, 0, 0, 0, 0, 0, 0, 0, 0, 0, 0, 0, 0, 0, 0, 0,
0, 0, 0, 0, 0, 0, 0, 0, 0, 0, 0, 0, 0, 0, 0, 0, 0, 0, 0, 0,
0, 0, 0, 0, 0, 0, 0, 0, 0, 0, 0, 0, 0, 0, 0, 0, 0, 0, 0, 0,
0, 0, 0, 0, 0, 0, 0, 0, 0, 0, 0, 0, 0, 0, 0, 0, 0, 0, 0, 0,
0, 0, 0, 0, 0, 0, 0, 0, 0, 0, 0, 0, 0, 0, 0, 0, 0, 0, 0, 0,
0, 0, 0, 0, 0, 0, 0, 0, 0, 0, 0, 0, 0, 0, 0, 0, 0, 0, 0, 0,
0, 0, 0, 0, 0, 0, 0, 0, 0, 0, 0, 0, 0, 0, 0, 0, 0, 0, 0, 0,
0, 0, 0, 0, 0, 0, 0, 0, 0, 0, 0, 0, 0, 0, 0, 0, 0, 0, 0, 0,
0, 0, 0, 0, 0, 0, 0, 0, 0, 0, 0, 0, 0, 0, 0, 0, 0, 0, 0, 0,
0, 0, 0, 0, 0, 0, 0, 0, 0, 0, 0, 0, 0, 0, 0, 0, 0, 0, 0, 0,
0, 0, 0, 0, 0, 0, 0, 0, 0, 0, 0, 0, 0, 0, 0, 0, 0, 0, 0, 0,
0, 0, 0, 0, 0, 0, 0, 0, 0, 0, 0, 0, 0, 0, 0, 0, 0, 0, 0, 0,
0, 0, 0, 0, 0, 0, 0, 0, 0, 0, 0, 0, 0, 0, 0, 0, 0, 0, 0, 0,
0, 0, 0, 0, 0, 0, 0, 0, 0, 0, 0, 0, 0, 0, 0, 0, 0, 0, 0, 0,
0, 0, 0, 0, 0, 0, 0, 0, 0, 0, 0, 0, 0, 0, 0, 0, 0, 0, 0, 0,
0, 0, 0, 0, 0, 0, 0, 0, 0, 0, 0, 0, 0, 0, 0, 0, 0, 0, 0, 0,
0, 0, 0, 0, 0, 0, 0, 0, 0, 0, 0, 0, 0, 0, 0, 0, 0, 0, 0, 0,
0, 0, 0, 0, 0, 0, 0, 0, 0, 0, 0, 0, 0, 0, 0, 0, 0, 0, 0, 0,
0, 0, 0, 0, 0, 0, 0, 0, 0, 0, 0, 0, 0, 0, 0, 0, 0, 0, 0, 0,
0, 0, 0, 0, 0, 0, 0, 0, 0, 0, 0, 0, 0, 0, 0, 0, 0, 0, 0, 0,
0, 0, 0, 0, 0, 0, 0, 0, 0, 0, 0, 0, 0, 0, 0, 0, 0, 0, 0, 0,
0, 0, 0, 0, 0, 0, 0, 0, 0, 0, 0, 0, 0, 0, 0, 0, 0, 0, 0, 0,
0, 0, 0, 0, 0, 0, 1, 10, 19, 28, 37, 46, 55, 63, 72, 81, 90, 99, 108, 116,
125, 134, 143, 152, 161, 169, 178, 187, 196, 205, 214, 222, 231, 240, 249, 258, 266, 275, 284, 293,
302, 311, 319, 328, 337, 346, 355, 363, 372, 381, 390, 399, 407, 416, 425, 434, 443, 451, 460, 469,
478, 487, 495, 504, 513, 522, 531, 539, 548, 557, 566, 574, 583, 592, 601, 609, 618, 627, 636, 644,
653, 662, 671, 679, 688, 697, 706, 714, 723, 732, 741, 749, 758, 767, 775, 784, 793, 801, 810, 819,
828, 836, 845, 854, 862, 871, 880, 888, 897, 906, 914, 923, 932, 940, 949, 957, 966, 975, 983, 992,
1001, 1009, 1018, 1026, 1035, 1044, 1052, 1061, 1069, 1078, 1087, 1095, 1104, 1112, 1121, 1129, 1138, 1147, 1155, 1164,
1172, 1181, 1189, 1198, 1206, 1215, 1223, 1232, 1240, 1249, 1257, 1266, 1274, 1283, 1291, 1300, 1308, 1317, 1325, 1333,
1342, 1350, 1359, 1367, 1376, 1384, 1392, 1401, 1409, 1418, 1426, 1434, 1443, 1451, 1459, 1468, 1476, 1485, 1493, 1501,
1510, 1518, 1526, 1534, 1543, 1551, 1559, 1568, 1576, 1584, 1592, 1601, 1609, 1617, 1626, 1634, 1642, 1650, 1658, 1667,
1675, 1683, 1691, 1699, 1708, 1716, 1724, 1732, 1740, 1748, 1757, 1765, 1773, 1781, 1789, 1797, 1805, 1813, 1821, 1830,
1838, 1846, 1854, 1862, 1870, 1878, 1886, 1894, 1902, 1910, 1918, 1926, 1934, 1942, 1950, 1958, 1966, 1974, 1982, 1990,
1997, 2005, 2013, 2021, 2029, 2037, 2045, 2053, 2061, 2068, 2076, 2084, 2092, 2100, 2108, 2115, 2123, 2131, 2139, 2147,
2154, 2162, 2170, 2178, 2185, 2193, 2201, 2208, 2216, 2224, 2231, 2239, 2247, 2254, 2262, 2270, 2277, 2285, 2293, 2300,
2308, 2315, 2323, 2331, 2338, 2346, 2353, 2361, 2368, 2376, 2383, 2391, 2398, 2406, 2413, 2421, 2428, 2435, 2443, 2450,
2458, 2465, 2473, 2480, 2487, 2495, 2502, 2509, 2517, 2524, 2531, 2539, 2546, 2553, 2560, 2568, 2575, 2582, 2589, 2597,
2604, 2611, 2618, 2625, 2633, 2640, 2647, 2654, 2661, 2668, 2675, 2683, 2690, 2697, 2704, 2711, 2718, 2725, 2732, 2739,
2746, 2753, 2760, 2767, 2774, 2781, 2788, 2795, 2802, 2809, 2815, 2822, 2829, 2836, 2843, 2850, 2857, 2863, 2870, 2877,
2884, 2891, 2897, 2904, 2911, 2918, 2924, 2931, 2938, 2944, 2951, 2958, 2964, 2971, 2978, 2984, 2991, 2998, 3004, 3011,
3017, 3024, 3030, 3037, 3043, 3050, 3056, 3063, 3069, 3076, 3082, 3089, 3095, 3102, 3108, 3114, 3121, 3127, 3133, 3140,
3146, 3152, 3159, 3165, 3171, 3178, 3184, 3190, 3196, 3202, 3209, 3215, 3221, 3227, 3233, 3240, 3246, 3252, 3258, 3264,
3270, 3276, 3282, 3288, 3294, 3300, 3306, 3312, 3318, 3324, 3330, 3336, 3342, 3348, 3354, 3360, 3366, 3371, 3377, 3383,
3389, 3395, 3401, 3406, 3412, 3418, 3424, 3429, 3435, 3441, 3446, 3452, 3458, 3463, 3469, 3475, 3480, 3486, 3491, 3497,
3503, 3508, 3514, 3519, 3525, 3530, 3536, 3541, 3547, 3552, 3557, 3563, 3568, 3574, 3579, 3584, 3590, 3595, 3600, 3606,
3611, 3616, 3621, 3627, 3632, 3637, 3642, 3647, 3653, 3658, 3663, 3668, 3673, 3678, 3683, 3688, 3693, 3698, 3703, 3709,
3714, 3718, 3723, 3728, 3733, 3738, 3743, 3748, 3753, 3758, 3763, 3768, 3772, 3777, 3782, 3787, 3792, 3796, 3801, 3806,
3810, 3815, 3820, 3824, 3829, 3834, 3838, 3843, 3848, 3852, 3857, 3861, 3866, 3870, 3875, 3879, 3884, 3888, 3893, 3897};

const uint16_t bangZ2_5Hz[3200]={0, 0, 0, 0, 0, 0, 0, 0, 0, 0, 0, 0, 0, 0, 0, 0, 0, 0, 0, 0,
0, 0, 0, 0, 0, 0, 0, 0, 0, 0, 0, 0, 0, 0, 0, 0, 0, 0, 0, 0,
0, 0, 0, 0, 0, 0, 0, 0, 0, 0, 0, 0, 0, 0, 0, 0, 0, 0, 0, 0,
0, 0, 0, 0, 0, 0, 0, 0, 0, 0, 0, 0, 0, 0, 0, 0, 0, 0, 0, 0,
0, 0, 0, 0, 0, 0, 0, 0, 0, 0, 0, 0, 0, 0, 0, 0, 0, 0, 0, 0,
0, 0, 0, 0, 0, 0, 0, 0, 0, 0, 0, 0, 0, 0, 0, 0, 0, 0, 0, 0,
0, 0, 0, 0, 0, 0, 0, 0, 0, 0, 0, 0, 0, 0, 0, 0, 0, 0, 0, 0,
0, 0, 0, 0, 0, 0, 0, 0, 0, 0, 0, 0, 0, 0, 0, 0, 0, 0, 0, 0,
0, 0, 0, 0, 0, 0, 0, 0, 0, 0, 0, 0, 0, 0, 0, 0, 0, 0, 0, 0,
0, 0, 0, 0, 0, 0, 0, 0, 0, 0, 0, 0, 0, 0, 0, 0, 0, 0, 0, 0,
0, 0, 0, 0, 0, 0, 0, 0, 0, 0, 0, 0, 0, 0, 0, 0, 0, 0, 0, 0,
0, 0, 0, 0, 0, 0, 0, 0, 0, 0, 0, 0, 0, 0, 0, 0, 0, 0, 0, 0,
0, 0, 0, 0, 0, 0, 0, 0, 0, 0, 0, 0, 0, 0, 0, 0, 0, 0, 0, 0,
0, 0, 0, 0, 0, 0, 0, 0, 0, 0, 0, 0, 0, 0, 0, 0, 0, 0, 0, 0,
0, 0, 0, 0, 0, 0, 0, 0, 0, 0, 0, 0, 0, 0, 0, 0, 0, 0, 0, 0,
0, 0, 0, 0, 0, 0, 0, 0, 0, 0, 0, 0, 0, 0, 0, 0, 0, 0, 0, 0,
0, 0, 0, 0, 0, 0, 0, 0, 0, 0, 0, 0, 0, 0, 0, 0, 0, 0, 0, 0,
0, 0, 0, 0, 0, 0, 0, 0, 0, 0, 0, 0, 0, 0, 0, 0, 0, 0, 0, 0,
0, 0, 0, 0, 0, 0, 0, 0, 0, 0, 0, 0, 0, 0, 0, 0, 0, 0, 0, 0,
0, 0, 0, 0, 0, 0, 0, 0, 0, 0, 0, 0, 0, 0, 0, 0, 0, 0, 0, 0,
0, 0, 0, 0, 0, 0, 0, 0, 0, 0, 0, 0, 0, 0, 0, 0, 0, 0, 0, 0,
0, 0, 0, 0, 0, 0, 0, 0, 0, 0, 0, 0, 0, 0, 0, 0, 0, 0, 0, 0,
0, 0, 0, 0, 0, 0, 0, 0, 0, 0, 0, 0, 0, 0, 0, 0, 0, 0, 0, 0,
0, 0, 0, 0, 0, 0, 0, 0, 0, 0, 0, 0, 0, 0, 0, 0, 0, 0, 0, 0,
0, 0, 0, 0, 0, 0, 0, 0, 0, 0, 0, 0, 0, 0, 0, 0, 0, 0, 0, 0,
0, 0, 0, 0, 0, 0, 0, 0, 0, 0, 0, 0, 0, 0, 0, 0, 0, 0, 0, 0,
0, 0, 0, 0, 0, 0, 0, 0, 0, 0, 0, 0, 0, 0, 7, 16, 25, 34, 43, 52,
60, 69, 78, 87, 96, 105, 113, 122, 131, 140, 149, 158, 166, 175, 184, 193, 202, 211, 219, 228,
237, 246, 255, 264, 272, 281, 290, 299, 308, 316, 325, 334, 343, 352, 361, 369, 378, 387, 396, 405,
413, 422, 431, 440, 449, 457, 466, 475, 484, 492, 501, 510, 519, 528, 536, 545, 554, 563, 571, 580,
589, 598, 607, 615, 624, 633, 642, 650, 659, 668, 677, 685, 694, 703, 711, 720, 729, 738, 746, 755,
764, 772, 781, 790, 799, 807, 816, 825, 833, 842, 851, 859, 868, 877, 885, 894, 903, 911, 920, 929,
937, 946, 955, 963, 972, 981, 989, 998, 1006, 1015, 1024, 1032, 1041, 1049, 1058, 1067, 1075, 1084, 1092, 1101,
1109, 1118, 1127, 1135, 1144, 1152, 1161, 1169, 1178, 1186, 1195, 1203, 1212, 1220, 1229, 1237, 1246, 1254, 1263, 1271,
1280, 1288, 1297, 1305, 1314, 1322, 1331, 1339, 1347, 1356, 1364, 1373, 1381, 1390, 1398, 1406, 1415, 1423, 1432, 1440,
1448, 1457, 1465, 1473, 1482, 1490, 1498, 1507, 1515, 1523, 1532, 1540, 1548, 1557, 1565, 1573, 1581, 1590, 1598, 1606,
1615, 1623, 1631, 1639, 1647, 1656, 1664, 1672, 1680, 1689, 1697, 1705, 1713, 1721, 1729, 1738, 1746, 1754, 1762, 1770,
1778, 1786, 1794, 1803, 1811, 1819, 1827, 1835, 1843, 1851, 1859, 1867, 1875, 1883, 1891, 1899, 1907, 1915, 1923, 1931,
1939, 1947, 1955, 1963, 1971, 1979, 1987, 1995, 2003, 2011, 2019, 2026, 2034, 2042, 2050, 2058, 2066, 2074, 2082, 2089,
2097, 2105, 2113, 2121, 2128, 2136, 2144, 2152, 2159, 2167, 2175, 2183, 2190, 2198, 2206, 2214, 2221, 2229, 2237, 2244,
2252, 2260, 2267, 2275, 2282, 2290, 2298, 2305, 2313, 2320, 2328, 2336, 2343, 2351, 2358, 2366, 2373, 2381, 2388, 2396,
2403, 2411, 2418, 2426, 2433, 2440, 2448, 2455, 2463, 2470, 2477, 2485, 2492, 2500, 2507, 2514, 2522, 2529, 2536, 2543,
2551, 2558, 2565, 2573, 2580, 2587, 2594, 2601, 2609, 2616, 2623, 2630, 2637, 2645, 2652, 2659, 2666, 2673, 2680, 2687,
2694, 2701, 2709, 2716, 2723, 2730, 2737, 2744, 2751, 2758, 2765, 2772, 2779, 2786, 2792, 2799, 2806, 2813, 2820, 2827,
2834, 2841, 2848, 2854, 2861, 2868, 2875, 2882, 2888, 2895, 2902, 2909, 2915, 2922, 2929, 2936, 2942, 2949, 2956, 2962,
2969, 2976, 2982, 2989, 2995, 3002, 3009, 3015, 3022, 3028, 3035, 3041, 3048, 3054, 3061, 3067, 3074, 3080, 3087, 3093,
3099, 3106, 3112, 3119, 3125, 3131, 3138, 3144, 3150, 3157, 3163, 3169, 3175, 3182, 3188, 3194, 3200, 3207, 3213, 3219,
3225, 3231, 3237, 3244, 3250, 3256, 3262, 3268, 3274, 3280, 3286, 3292, 3298, 3304, 3310, 3316, 3322, 3328, 3334, 3340,
3346, 3352, 3358, 3364, 3369, 3375, 3381, 3387, 3393, 3399, 3404, 3410, 3416, 3422, 3427, 3433, 3439, 3445, 3450, 3456,
3462, 3467, 3473, 3478, 3484, 3490, 3495, 3501, 3506, 3512, 3517, 3523, 3528, 3534, 3539, 3545, 3550, 3556, 3561, 3566,
3572, 3577, 3582, 3588, 3593, 3598, 3604, 3609, 3614, 3620, 3625, 3630, 3635, 3640, 3646, 3651, 3656, 3661, 3666, 3671,
3677, 3682, 3687, 3692, 3697, 3702, 3707, 3712, 3717, 3722, 3727, 3732, 3737, 3742, 3746, 3751, 3756, 3761, 3766, 3771,
3776, 3780, 3785, 3790, 3795, 3799, 3804, 3809, 3814, 3818, 3823, 3828, 3832, 3837, 3841, 3846, 3851, 3855, 3860, 3864,
3869, 3873, 3878, 3882, 3887, 3891, 3896, 3900, 3904, 3909, 3913, 3918, 3922, 3926, 3931, 3935, 3939, 3943, 3948, 3952,
3956, 3960, 3964, 3969, 3973, 3977, 3981, 3985, 3989, 3993, 3997, 4002, 4006, 4010, 4014, 4018, 4022, 4025, 4029, 4033,
4037, 4041, 4045, 4049, 4053, 4057, 4060, 4064, 4068, 4072, 4076, 4079, 4083, 4087, 4090, 4094, 4098, 4101, 4105, 4109,
4112, 4116, 4119, 4123, 4126, 4130, 4133, 4137, 4140, 4144, 4147, 4151, 4154, 4158, 4161, 4164, 4168, 4171, 4174, 4178,
4181, 4184, 4187, 4191, 4194, 4197, 4200, 4203, 4206, 4210, 4213, 4216, 4219, 4222, 4225, 4228, 4231, 4234, 4237, 4240,
4243, 4246, 4249, 4252, 4255, 4257, 4260, 4263, 4266, 4269, 4272, 4274, 4277, 4280, 4283, 4285, 4288, 4291, 4293, 4296,
4299, 4301, 4304, 4306, 4309, 4311, 4314, 4316, 4319, 4321, 4324, 4326, 4329, 4331, 4334, 4336, 4338, 4341, 4343, 4345,
4348, 4350, 4352, 4354, 4357, 4359, 4361, 4363, 4365, 4367, 4369, 4372, 4374, 4376, 4378, 4380, 4382, 4384, 4386, 4388,
4390, 4392, 4394, 4396, 4397, 4399, 4401, 4403, 4405, 4407, 4408, 4410, 4412, 4414, 4415, 4417, 4419, 4420, 4422, 4424,
4425, 4427, 4428, 4430, 4432, 4433, 4435, 4436, 4438, 4439, 4440, 4442, 4443, 4445, 4446, 4447, 4449, 4450, 4451, 4453,
4454, 4455, 4456, 4458, 4459, 4460, 4461, 4462, 4463, 4465, 4466, 4467, 4468, 4469, 4470, 4471, 4472, 4473, 4474, 4475,
4476, 4477, 4478, 4478, 4479, 4480, 4481, 4482, 4482, 4483, 4484, 4485, 4485, 4486, 4487, 4488, 4488, 4489, 4489, 4490,
4491, 4491, 4492, 4492, 4493, 4493, 4494, 4494, 4495, 4495, 4495, 4496, 4496, 4497, 4497, 4497, 4498, 4498, 4498, 4498,
4499, 4499, 4499, 4499, 4499, 4499, 4500, 4500, 4500, 4500, 4500, 4500, 4500, 4500, 4500, 4500, 4500, 4500, 4500, 4500,
4500, 4499, 4499, 4499, 4499, 4499, 4499, 4498, 4498, 4498, 4497, 4497, 4497, 4496, 4496, 4496, 4495, 4495, 4495, 4494,
4494, 4493, 4493, 4492, 4492, 4491, 4491, 4490, 4489, 4489, 4488, 4487, 4487, 4486, 4485, 4485, 4484, 4483, 4482, 4482,
4481, 4480, 4479, 4478, 4477, 4476, 4476, 4475, 4474, 4473, 4472, 4471, 4470, 4469, 4468, 4467, 4466, 4464, 4463, 4462,
4461, 4460, 4459, 4457, 4456, 4455, 4454, 4452, 4451, 4450, 4449, 4447, 4446, 4444, 4443, 4442, 4440, 4439, 4437, 4436,
4434, 4433, 4431, 4430, 4428, 4427, 4425, 4423, 4422, 4420, 4418, 4417, 4415, 4413, 4412, 4410, 4408, 4406, 4404, 4403,
4401, 4399, 4397, 4395, 4393, 4391, 4389, 4388, 4386, 4384, 4382, 4380, 4377, 4375, 4373, 4371, 4369, 4367, 4365, 4363,
4361, 4358, 4356, 4354, 4352, 4349, 4347, 4345, 4343, 4340, 4338, 4336, 4333, 4331, 4328, 4326, 4323, 4321, 4319, 4316,
4314, 4311, 4308, 4306, 4303, 4301, 4298, 4295, 4293, 4290, 4288, 4285, 4282, 4279, 4277, 4274, 4271, 4268, 4266, 4263,
4260, 4257, 4254, 4251, 4248, 4245, 4242, 4240, 4237, 4234, 4231, 4228, 4224, 4221, 4218, 4215, 4212, 4209, 4206, 4203,
4200, 4196, 4193, 4190, 4187, 4184, 4180, 4177, 4174, 4170, 4167, 4164, 4160, 4157, 4154, 4150, 4147, 4143, 4140, 4136,
4133, 4129, 4126, 4122, 4119, 4115, 4112, 4108, 4104, 4101, 4097, 4093, 4090, 4086, 4082, 4079, 4075, 4071, 4067, 4064,
4060, 4056, 4052, 4048, 4044, 4041, 4037, 4033, 4029, 4025, 4021, 4017, 4013, 4009, 4005, 4001, 3997, 3993, 3989, 3985,
3980, 3976, 3972, 3968, 3964, 3960, 3955, 3951, 3947, 3943, 3938, 3934, 3930, 3926, 3921, 3917, 3912, 3908, 3904, 3899,
3895, 3890, 3886, 3882, 3877, 3873, 3868, 3864, 3859, 3854, 3850, 3845, 3841, 3836, 3831, 3827, 3822, 3817, 3813, 3808,
3803, 3799, 3794, 3789, 3784, 3780, 3775, 3770, 3765, 3760, 3755, 3751, 3746, 3741, 3736, 3731, 3726, 3721, 3716, 3711,
3706, 3701, 3696, 3691, 3686, 3681, 3676, 3671, 3665, 3660, 3655, 3650, 3645, 3640, 3634, 3629, 3624, 3619, 3613, 3608,
3603, 3598, 3592, 3587, 3582, 3576, 3571, 3565, 3560, 3555, 3549, 3544, 3538, 3533, 3527, 3522, 3516, 3511, 3505, 3500,
3494, 3489, 3483, 3477, 3472, 3466, 3461, 3455, 3449, 3444, 3438, 3432, 3426, 3421, 3415, 3409, 3403, 3398, 3392, 3386,
3380, 3374, 3368, 3363, 3357, 3351, 3345, 3339, 3333, 3327, 3321, 3315, 3309, 3303, 3297, 3291, 3285, 3279, 3273, 3267,
3261, 3255, 3249, 3243, 3236, 3230, 3224, 3218, 3212, 3206, 3199, 3193, 3187, 3181, 3174, 3168, 3162, 3156, 3149, 3143,
3137, 3130, 3124, 3118, 3111, 3105, 3098, 3092, 3086, 3079, 3073, 3066, 3060, 3053, 3047, 3040, 3034, 3027, 3021, 3014,
3007, 3001, 2994, 2988, 2981, 2974, 2968, 2961, 2955, 2948, 2941, 2934, 2928, 2921, 2914, 2908, 2901, 2894, 2887, 2880,
2874, 2867, 2860, 2853, 2846, 2840, 2833, 2826, 2819, 2812, 2805, 2798, 2791, 2784, 2777, 2770, 2763, 2756, 2749, 2742,
2735, 2728, 2721, 2714, 2707, 2700, 2693, 2686, 2679, 2672, 2665, 2658, 2651, 2643, 2636, 2629, 2622, 2615, 2607, 2600,
2593, 2586, 2579, 2571, 2564, 2557, 2550, 2542, 2535, 2528, 2520, 2513, 2506, 2498, 2491, 2484, 2476, 2469, 2461, 2454,
2447, 2439, 2432, 2424, 2417, 2409, 2402, 2394, 2387, 2379, 2372, 2364, 2357, 2349, 2342, 2334, 2327, 2319, 2312, 2304,
2296, 2289, 2281, 2274, 2266, 2258, 2251, 2243, 2235, 2228, 2220, 2212, 2205, 2197, 2189, 2181, 2174, 2166, 2158, 2150,
2143, 2135, 2127, 2119, 2111, 2104, 2096, 2088, 2080, 2072, 2065, 2057, 2049, 2041, 2033, 2025, 2017, 2009, 2001, 1994,
1986, 1978, 1970, 1962, 1954, 1946, 1938, 1930, 1922, 1914, 1906, 1898, 1890, 1882, 1874, 1866, 1858, 1850, 1842, 1834,
1825, 1817, 1809, 1801, 1793, 1785, 1777, 1769, 1761, 1752, 1744, 1736, 1728, 1720, 1712, 1704, 1695, 1687, 1679, 1671,
1663, 1654, 1646, 1638, 1630, 1621, 1613, 1605, 1597, 1588, 1580, 1572, 1564, 1555, 1547, 1539, 1530, 1522, 1514, 1505,
1497, 1489, 1480, 1472, 1464, 1455, 1447, 1439, 1430, 1422, 1413, 1405, 1397, 1388, 1380, 1371, 1363, 1355, 1346, 1338,
1329, 1321, 1312, 1304, 1295, 1287, 1278, 1270, 1261, 1253, 1245, 1236, 1228, 1219, 1211, 1202, 1193, 1185, 1176, 1168,
1159, 1151, 1142, 1134, 1125, 1117, 1108, 1099, 1091, 1082, 1074, 1065, 1057, 1048, 1039, 1031, 1022, 1014, 1005, 996,
988, 979, 970, 962, 953, 945, 936, 927, 919, 910, 901, 893, 884, 875, 867, 858, 849, 841, 832, 823,
815, 806, 797, 788, 780, 771, 762, 754, 745, 736, 727, 719, 710, 701, 693, 684, 675, 666, 658, 649,
640, 631, 623, 614, 605, 596, 588, 579, 570, 561, 552, 544, 535, 526, 517, 509, 500, 491, 482, 473,
465, 456, 447, 438, 429, 421, 412, 403, 394, 385, 377, 368, 359, 350, 341, 333, 324, 315, 306, 297,
289, 280, 271, 262, 253, 244, 236, 227, 218, 209, 200, 191, 183, 174, 165, 156, 147, 138, 130, 121,
112, 103, 94, 85, 77, 68, 59, 50, 41, 32, 24, 15, 6, 0, 0, 0, 0, 0, 0, 0,
0, 0, 0, 0, 0, 0, 0, 0, 0, 0, 0, 0, 0, 0, 0, 0, 0, 0, 0, 0,
0, 0, 0, 0, 0, 0, 0, 0, 0, 0, 0, 0, 0, 0, 0, 0, 0, 0, 0, 0,
0, 0, 0, 0, 0, 0, 0, 0, 0, 0, 0, 0, 0, 0, 0, 0, 0, 0, 0, 0,
0, 0, 0, 0, 0, 0, 0, 0, 0, 0, 0, 0, 0, 0, 0, 0, 0, 0, 0, 0,
0, 0, 0, 0, 0, 0, 0, 0, 0, 0, 0, 0, 0, 0, 0, 0, 0, 0, 0, 0,
0, 0, 0, 0, 0, 0, 0, 0, 0, 0, 0, 0, 0, 0, 0, 0, 0, 0, 0, 0,
0, 0, 0, 0, 0, 0, 0, 0, 0, 0, 0, 0, 0, 0, 0, 0, 0, 0, 0, 0,
0, 0, 0, 0, 0, 0, 0, 0, 0, 0, 0, 0, 0, 0, 0, 0, 0, 0, 0, 0,
0, 0, 0, 0, 0, 0, 0, 0, 0, 0, 0, 0, 0, 0, 0, 0, 0, 0, 0, 0,
0, 0, 0, 0, 0, 0, 0, 0, 0, 0, 0, 0, 0, 0, 0, 0, 0, 0, 0, 0,
0, 0, 0, 0, 0, 0, 0, 0, 0, 0, 0, 0, 0, 0, 0, 0, 0, 0, 0, 0,
0, 0, 0, 0, 0, 0, 0, 0, 0, 0, 0, 0, 0, 0, 0, 0, 0, 0, 0, 0,
0, 0, 0, 0, 0, 0, 0, 0, 0, 0, 0, 0, 0, 0, 0, 0, 0, 0, 0, 0,
0, 0, 0, 0, 0, 0, 0, 0, 0, 0, 0, 0, 0, 0, 0, 0, 0, 0, 0, 0,
0, 0, 0, 0, 0, 0, 0, 0, 0, 0, 0, 0, 0, 0, 0, 0, 0, 0, 0, 0,
0, 0, 0, 0, 0, 0, 0, 0, 0, 0, 0, 0, 0, 0, 0, 0, 0, 0, 0, 0,
0, 0, 0, 0, 0, 0, 0, 0, 0, 0, 0, 0, 0, 0, 0, 0, 0, 0, 0, 0,
0, 0, 0, 0, 0, 0, 0, 0, 0, 0, 0, 0, 0, 0, 0, 0, 0, 0, 0, 0,
0, 0, 0, 0, 0, 0, 0, 0, 0, 0, 0, 0, 0, 0, 0, 0, 0, 0, 0, 0,
0, 0, 0, 0, 0, 0, 0, 0, 0, 0, 0, 0, 0, 0, 0, 0, 0, 0, 0, 0,
0, 0, 0, 0, 0, 0, 0, 0, 0, 0, 0, 0, 0, 0, 0, 0, 0, 0, 0, 0,
0, 0, 0, 0, 0, 0, 0, 0, 0, 0, 0, 0, 0, 0, 0, 0, 0, 0, 0, 0,
0, 0, 0, 0, 0, 0, 0, 0, 0, 0, 0, 0, 0, 0, 0, 0, 0, 0, 0, 0,
0, 0, 0, 0, 0, 0, 0, 0, 0, 0, 0, 0, 0, 0, 0, 0, 0, 0, 0, 0,
0, 0, 0, 0, 0, 0, 0, 0, 0, 0, 0, 0, 0, 0, 0, 0, 0, 0, 0, 0,
0, 0, 0, 0, 0, 0, 0, 0, 0, 0, 0, 0, 0, 0, 0, 0, 0, 0, 0, 0,
0, 0, 0, 0, 0, 0, 0, 0, 0, 0, 0, 0, 0, 0, 0, 0, 0, 0, 0, 0,
0, 0, 0, 0, 0, 0, 0, 0, 0, 0, 0, 0, 0, 0, 0, 0, 0, 0, 0, 0,
0, 0, 0, 0, 0, 0, 0, 0, 0, 0, 0, 0, 0, 0, 0, 0, 0, 0, 0, 0,
0, 0, 0, 0, 0, 0, 0, 0, 0, 0, 0, 0, 0, 0, 0, 0, 0, 0, 0, 0,
0, 0, 0, 0, 0, 0, 0, 0, 0, 0, 0, 0, 0, 0, 0, 0, 0, 0, 0, 0,
0, 0, 0, 0, 0, 0, 0, 0, 0, 0, 0, 0, 0, 0, 0, 0, 0, 0, 0, 0,
0, 0, 0, 0, 0, 0, 0, 0, 0, 0, 0, 0, 0, 0, 0, 0, 0, 0, 0, 0,
0, 0, 0, 0, 0, 0, 0, 0, 0, 0, 0, 0, 0, 0, 0, 0, 0, 0, 0, 0,
0, 0, 0, 0, 0, 0, 0, 0, 0, 0, 0, 0, 0, 0, 0, 0, 0, 0, 0, 0,
0, 0, 0, 0, 0, 0, 0, 0, 0, 0, 0, 0, 0, 0, 0, 0, 0, 0, 0, 0,
0, 0, 0, 0, 0, 0, 0, 0, 0, 0, 0, 0, 0, 0, 0, 0, 0, 0, 0, 0,
0, 0, 0, 0, 0, 0, 0, 0, 0, 0, 0, 0, 0, 0, 0, 0, 0, 0, 0, 0,
0, 0, 0, 0, 0, 0, 0, 0, 0, 0, 0, 0, 0, 0, 0, 0, 0, 0, 0, 0,
0, 0, 0, 0, 0, 0, 0, 0, 0, 0, 0, 0, 0, 0, 0, 0, 0, 0, 0, 0,
0, 0, 0, 0, 0, 0, 0, 0, 0, 0, 0, 0, 0, 0, 0, 0, 0, 0, 0, 0,
0, 0, 0, 0, 0, 0, 0, 0, 0, 0, 0, 0, 0, 0, 0, 0, 0, 0, 0, 0,
0, 0, 0, 0, 0, 0, 0, 0, 0, 0, 0, 0, 0, 0, 0, 0, 0, 0, 0, 0,
0, 0, 0, 0, 0, 0, 0, 0, 0, 0, 0, 0, 0, 0, 0, 0, 0, 0, 0, 0,
0, 0, 0, 0, 0, 0, 0, 0, 0, 0, 0, 0, 0, 0, 0, 0, 0, 0, 0, 0,
0, 0, 0, 0, 0, 0, 0, 0, 0, 0, 0, 0, 0, 0, 0, 0, 0, 0, 0, 0,
0, 0, 0, 0, 0, 0, 0, 0, 0, 0, 0, 0, 0, 0, 0, 0, 0, 0, 0, 0,
0, 0, 0, 0, 0, 0, 0, 0, 0, 0, 0, 0, 0, 0, 0, 0, 0, 0, 0, 0,
0, 0, 0, 0, 0, 0, 0, 0, 0, 0, 0, 0, 0, 0, 0, 0, 0, 0, 0, 0,
0, 0, 0, 0, 0, 0, 0, 0, 0, 0, 0, 0, 0, 0, 0, 0, 0, 0, 0, 0,
0, 0, 0, 0, 0, 0, 0, 0, 0, 0, 0, 0, 0, 0, 0, 0, 0, 0, 0, 0,
0, 0, 0, 0, 0, 0, 0, 0, 0, 0, 0, 0, 0, 0, 0, 0, 0, 0, 0, 0,
0, 0, 0, 0, 0, 0, 0, 0, 0, 0, 0, 0, 0, 0, 0, 0, 0, 0, 0, 0};

//void callPWM(float FW)
//{
	//static int index =0;
	//int step = (FW*GIATRI)/FM;//10hz = 1step,20hz = 2step ,50hz = 5 step
				//		TIM2->CCR1 = bangX1_10Hz[index];
					//	TIM2->CCR2 = bangX2_10Hz[index];
					//	TIM2->CCR3 = bangY1_10Hz[index];
					//	TIM2->CCR4 = bangY2_10Hz[index];
						//TIM3->CCR1 = bangZ1_10Hz[index];
						//TIM3->CCR2 = bangZ2_10Hz[index];
	//index += step;
	//if(index >= GIATRI)
		//{ index =0;
		//check_adc = 0;}
		//}
/* USER CODE END 0 */

int main(void)
{

  /* MCU Configuration--------------------------------------------------------*/

  /* Reset of all peripherals, Initializes the Flash interface and the Systick. */
  HAL_Init();

  /* Configure the system clock */
  SystemClock_Config();

  /* Initialize all configured peripherals */
  MX_GPIO_Init();
  MX_ADC1_Init();
  MX_TIM2_Init();
  MX_TIM3_Init();
  MX_TIM1_Init();
  /* USER CODE BEGIN 2 */
HAL_TIM_PWM_Start(&htim1, TIM_CHANNEL_1);
	HAL_TIM_Base_Start_IT(&htim2);
	HAL_TIM_Base_Start_IT(&htim3);
	HAL_TIM_PWM_Start(&htim2, TIM_CHANNEL_1);
	HAL_TIM_PWM_Start(&htim2, TIM_CHANNEL_2);
	HAL_TIM_PWM_Start(&htim2, TIM_CHANNEL_3);
	HAL_TIM_PWM_Start(&htim2, TIM_CHANNEL_4);
	HAL_TIM_PWM_Start(&htim3, TIM_CHANNEL_1);
	HAL_TIM_PWM_Start(&htim3, TIM_CHANNEL_2);
	TIM1->ARR = 4500;
	TIM2->ARR = 4500;
	TIM3->ARR = 4500;
 	TIM2->CCR1 = 0;
	TIM2->CCR2 = 0;
	TIM2->CCR3 = 0;
	TIM2->CCR4 = 0;
	TIM3->CCR1 = 0;
	TIM3->CCR2 = 0;
	i0 = 0;
	seclect = 0;
  /* USER CODE END 2 */

  /* Infinite loop */
  /* USER CODE BEGIN WHILE */
  luuadc = 1100;
	while (1)
  {
    /* USER CODE END WHILE */
		a= HAL_GPIO_ReadPin(GPIOB, GPIO_PIN_3); //PA3
		b = HAL_GPIO_ReadPin(GPIOB, GPIO_PIN_4);//PA2
		c = HAL_GPIO_ReadPin(GPIOB, GPIO_PIN_5);//PA1
	//	d = HAL_GPIO_ReadPin(GPIOB, GPIO_PIN_6);//PA0 = 10hz
if (b == GPIO_PIN_RESET && c == GPIO_PIN_RESET)
 {  luuadc = 1100;}
 else  if ( c == GPIO_PIN_RESET && b == GPIO_PIN_SET)
	{  luuadc = 1100;}
	else if (c == GPIO_PIN_SET && b == GPIO_PIN_RESET)
	{  luuadc = 1800;}
		else if (c == GPIO_PIN_SET && b == GPIO_PIN_SET)
	{  luuadc = 2700;}

    /* USER CODE BEGIN 3 */
		if (check_adc == 0)
					{

								HAL_ADC_Start(&hadc1);
								HAL_ADC_PollForConversion(&hadc1,HAL_MAX_DELAY);
								ADC_Sensor = HAL_ADC_GetValue(&hadc1);
								HAL_ADC_Stop(&hadc1);

						if (luuadc > ADC_Sensor)
						{											seclect = 1;
																	step = 1;
																	check_adc = 1 ;
																	numberS = 3200;
																	continue;
																}
						else  if (ADC_Sensor > 1100 && ADC_Sensor <1800)
																{
																	seclect = 2;
																	step = 2;
																	numberS = 3200;
																	check_adc = 1 ;
																	continue;
																}
													else if (ADC_Sensor > 1800&& ADC_Sensor<2700  ) //&& ADC_Sensor<2000
															{
																seclect = 3;
																	step = 4;
																	check_adc = 1 ;
																numberS = 3200;
																continue;
																}
																else if (ADC_Sensor > 2700)
															{
																seclect = 4;
															step = 10;
																numberS = 3200;
															check_adc = 1 ;
																continue;

					}
				}}}

void HAL_TIM_PeriodElapsedCallback(TIM_HandleTypeDef* htim2)
{

    if (seclect == 1)
    {

        TIM2->CCR1 = zero3200[i0];
        TIM2->CCR2 = zero3200[i0];
        TIM2->CCR3 = zero3200[i0];
        TIM2->CCR4 = zero3200[i0];
        TIM3->CCR1 = zero3200[i0];
        TIM3->CCR2 = zero3200[i0];
    }

        else if (seclect == 2){// step = (10 * GIATRI) / FM;  // 10Hz
				TIM2->CCR1 = bangX1_5Hz[i0];
        TIM2->CCR2 = bangX2_5Hz[i0];
        TIM2->CCR3 = bangY1_5Hz[i0];
        TIM2->CCR4 = bangY2_5Hz[i0];
        TIM3->CCR1 = bangZ1_5Hz[i0];
        TIM3->CCR2 = bangZ2_5Hz[i0];}
        else if (seclect == 3){// step = (20 * GIATRI) / FM; // 20Hz
				  TIM2->CCR1 = bangX1_5Hz[i0];
        TIM2->CCR2 = bangX2_5Hz[i0];
        TIM2->CCR3 = bangY1_5Hz[i0];
        TIM2->CCR4 = bangY2_5Hz[i0];
        TIM3->CCR1 = bangZ1_5Hz[i0];
        TIM3->CCR2 = bangZ2_5Hz[i0];}
        else if (seclect == 4){ //step = (50 * GIATRI) / FM; // 50Hz

        TIM2->CCR1 = bangX1_5Hz[i0];
        TIM2->CCR2 = bangX2_5Hz[i0];
        TIM2->CCR3 = bangY1_5Hz[i0];
        TIM2->CCR4 = bangY2_5Hz[i0];
        TIM3->CCR1 = bangZ1_5Hz[i0];
        TIM3->CCR2 = bangZ2_5Hz[i0];}

        // Tang i theo bu?c nh?y
        i0 += step;
        if (i0 >= numberS)
        {
            i0= 0;
					step = 0;
            check_adc = 0;
        }

}

  /* USER CODE END 3 */

void SystemClock_Config(void)
{
  RCC_OscInitTypeDef RCC_OscInitStruct = {0};
  RCC_ClkInitTypeDef RCC_ClkInitStruct = {0};
  RCC_PeriphCLKInitTypeDef PeriphClkInit = {0};

  /** Initializes the RCC Oscillators according to the specified parameters
  * in the RCC_OscInitTypeDef structure.
  */
  RCC_OscInitStruct.OscillatorType = RCC_OSCILLATORTYPE_HSE;
  RCC_OscInitStruct.HSEState = RCC_HSE_ON;
  RCC_OscInitStruct.HSEPredivValue = RCC_HSE_PREDIV_DIV1;
  RCC_OscInitStruct.HSIState = RCC_HSI_ON;
  RCC_OscInitStruct.PLL.PLLState = RCC_PLL_ON;
  RCC_OscInitStruct.PLL.PLLSource = RCC_PLLSOURCE_HSE;
  RCC_OscInitStruct.PLL.PLLMUL = RCC_PLL_MUL9;
  if (HAL_RCC_OscConfig(&RCC_OscInitStruct) != HAL_OK)
  {
    Error_Handler();
  }

  /** Initializes the CPU, AHB and APB buses clocks
  */
  RCC_ClkInitStruct.ClockType = RCC_CLOCKTYPE_HCLK|RCC_CLOCKTYPE_SYSCLK
                              |RCC_CLOCKTYPE_PCLK1|RCC_CLOCKTYPE_PCLK2;
  RCC_ClkInitStruct.SYSCLKSource = RCC_SYSCLKSOURCE_PLLCLK;
  RCC_ClkInitStruct.AHBCLKDivider = RCC_SYSCLK_DIV1;
  RCC_ClkInitStruct.APB1CLKDivider = RCC_HCLK_DIV2;
  RCC_ClkInitStruct.APB2CLKDivider = RCC_HCLK_DIV1;

  if (HAL_RCC_ClockConfig(&RCC_ClkInitStruct, FLASH_LATENCY_2) != HAL_OK)
  {
    Error_Handler();
  }
  PeriphClkInit.PeriphClockSelection = RCC_PERIPHCLK_ADC;
  PeriphClkInit.AdcClockSelection = RCC_ADCPCLK2_DIV6;
  if (HAL_RCCEx_PeriphCLKConfig(&PeriphClkInit) != HAL_OK)
  {
    Error_Handler();
  }
}

static void MX_ADC1_Init(void)
{

  ADC_ChannelConfTypeDef sConfig = {0};

  /** Common config
  */
  hadc1.Instance = ADC1;
  hadc1.Init.ScanConvMode = ADC_SCAN_DISABLE;
  hadc1.Init.ContinuousConvMode = DISABLE;
  hadc1.Init.DiscontinuousConvMode = DISABLE;
  hadc1.Init.ExternalTrigConv = ADC_SOFTWARE_START;
  hadc1.Init.DataAlign = ADC_DATAALIGN_RIGHT;
  hadc1.Init.NbrOfConversion = 1;
  if (HAL_ADC_Init(&hadc1) != HAL_OK)
  {
    Error_Handler();
  }

  /** Configure Regular Channel
  */
  sConfig.Channel = ADC_CHANNEL_4;
  sConfig.Rank = ADC_REGULAR_RANK_1;
  sConfig.SamplingTime = ADC_SAMPLETIME_55CYCLES_5;
  if (HAL_ADC_ConfigChannel(&hadc1, &sConfig) != HAL_OK)
  {
    Error_Handler();
  }

}

static void MX_TIM1_Init(void)
{

  TIM_ClockConfigTypeDef sClockSourceConfig = {0};
  TIM_MasterConfigTypeDef sMasterConfig = {0};
  TIM_OC_InitTypeDef sConfigOC = {0};
  TIM_IC_InitTypeDef sConfigIC = {0};
  TIM_BreakDeadTimeConfigTypeDef sBreakDeadTimeConfig = {0};

  htim1.Instance = TIM1;
  htim1.Init.Prescaler = 0;
  htim1.Init.CounterMode = TIM_COUNTERMODE_CENTERALIGNED2;
  htim1.Init.Period = 5249;
  htim1.Init.ClockDivision = TIM_CLOCKDIVISION_DIV1;
  htim1.Init.RepetitionCounter = 0;
  htim1.Init.AutoReloadPreload = TIM_AUTORELOAD_PRELOAD_DISABLE;
  if (HAL_TIM_Base_Init(&htim1) != HAL_OK)
  {
    Error_Handler();
  }
  sClockSourceConfig.ClockSource = TIM_CLOCKSOURCE_INTERNAL;
  if (HAL_TIM_ConfigClockSource(&htim1, &sClockSourceConfig) != HAL_OK)
  {
    Error_Handler();
  }
  if (HAL_TIM_PWM_Init(&htim1) != HAL_OK)
  {
    Error_Handler();
  }
  if (HAL_TIM_IC_Init(&htim1) != HAL_OK)
  {
    Error_Handler();
  }
  sMasterConfig.MasterOutputTrigger = TIM_TRGO_RESET;
  sMasterConfig.MasterSlaveMode = TIM_MASTERSLAVEMODE_DISABLE;
  if (HAL_TIMEx_MasterConfigSynchronization(&htim1, &sMasterConfig) != HAL_OK)
  {
    Error_Handler();
  }
  sConfigOC.OCMode = TIM_OCMODE_PWM1;
  sConfigOC.Pulse = 0;
  sConfigOC.OCPolarity = TIM_OCPOLARITY_HIGH;
  sConfigOC.OCNPolarity = TIM_OCNPOLARITY_HIGH;
  sConfigOC.OCFastMode = TIM_OCFAST_DISABLE;
  sConfigOC.OCIdleState = TIM_OCIDLESTATE_RESET;
  sConfigOC.OCNIdleState = TIM_OCNIDLESTATE_RESET;
  if (HAL_TIM_PWM_ConfigChannel(&htim1, &sConfigOC, TIM_CHANNEL_1) != HAL_OK)
  {
    Error_Handler();
  }
  sConfigIC.ICPolarity = TIM_INPUTCHANNELPOLARITY_RISING;
  sConfigIC.ICSelection = TIM_ICSELECTION_DIRECTTI;
  sConfigIC.ICPrescaler = TIM_ICPSC_DIV1;
  sConfigIC.ICFilter = 0;
  if (HAL_TIM_IC_ConfigChannel(&htim1, &sConfigIC, TIM_CHANNEL_2) != HAL_OK)
  {
    Error_Handler();
  }
  sBreakDeadTimeConfig.OffStateRunMode = TIM_OSSR_DISABLE;
  sBreakDeadTimeConfig.OffStateIDLEMode = TIM_OSSI_DISABLE;
  sBreakDeadTimeConfig.LockLevel = TIM_LOCKLEVEL_OFF;
  sBreakDeadTimeConfig.DeadTime = 0;
  sBreakDeadTimeConfig.BreakState = TIM_BREAK_DISABLE;
  sBreakDeadTimeConfig.BreakPolarity = TIM_BREAKPOLARITY_HIGH;
  sBreakDeadTimeConfig.AutomaticOutput = TIM_AUTOMATICOUTPUT_DISABLE;
  if (HAL_TIMEx_ConfigBreakDeadTime(&htim1, &sBreakDeadTimeConfig) != HAL_OK)
  {
    Error_Handler();
  }

}

static void MX_TIM2_Init(void)
{

  TIM_SlaveConfigTypeDef sSlaveConfig = {0};
  TIM_MasterConfigTypeDef sMasterConfig = {0};
  TIM_OC_InitTypeDef sConfigOC = {0};

  htim2.Instance = TIM2;
  htim2.Init.Prescaler = 0;
  htim2.Init.CounterMode = TIM_COUNTERMODE_CENTERALIGNED1;
  htim2.Init.Period = 5249;
  htim2.Init.ClockDivision = TIM_CLOCKDIVISION_DIV1;
  htim2.Init.AutoReloadPreload = TIM_AUTORELOAD_PRELOAD_ENABLE;
  if (HAL_TIM_Base_Init(&htim2) != HAL_OK)
  {
    Error_Handler();
  }
  if (HAL_TIM_PWM_Init(&htim2) != HAL_OK)
  {
    Error_Handler();
  }
  sSlaveConfig.SlaveMode = TIM_SLAVEMODE_TRIGGER;
  sSlaveConfig.InputTrigger = TIM_TS_ITR0;
  if (HAL_TIM_SlaveConfigSynchro(&htim2, &sSlaveConfig) != HAL_OK)
  {
    Error_Handler();
  }
  sMasterConfig.MasterOutputTrigger = TIM_TRGO_RESET;
  sMasterConfig.MasterSlaveMode = TIM_MASTERSLAVEMODE_DISABLE;
  if (HAL_TIMEx_MasterConfigSynchronization(&htim2, &sMasterConfig) != HAL_OK)
  {
    Error_Handler();
  }
  sConfigOC.OCMode = TIM_OCMODE_PWM1;
  sConfigOC.Pulse = 0;
  sConfigOC.OCPolarity = TIM_OCPOLARITY_HIGH;
  sConfigOC.OCFastMode = TIM_OCFAST_DISABLE;
  if (HAL_TIM_PWM_ConfigChannel(&htim2, &sConfigOC, TIM_CHANNEL_1) != HAL_OK)
  {
    Error_Handler();
  }
  sConfigOC.OCMode = TIM_OCMODE_PWM2;
  if (HAL_TIM_PWM_ConfigChannel(&htim2, &sConfigOC, TIM_CHANNEL_2) != HAL_OK)
  {
    Error_Handler();
  }
  sConfigOC.OCMode = TIM_OCMODE_PWM1;
  if (HAL_TIM_PWM_ConfigChannel(&htim2, &sConfigOC, TIM_CHANNEL_3) != HAL_OK)
  {
    Error_Handler();
  }
  sConfigOC.OCMode = TIM_OCMODE_PWM2;
  if (HAL_TIM_PWM_ConfigChannel(&htim2, &sConfigOC, TIM_CHANNEL_4) != HAL_OK)
  {
    Error_Handler();
  }
  HAL_TIM_MspPostInit(&htim2);

}

static void MX_TIM3_Init(void)
{

  TIM_SlaveConfigTypeDef sSlaveConfig = {0};
  TIM_MasterConfigTypeDef sMasterConfig = {0};
  TIM_OC_InitTypeDef sConfigOC = {0};

  htim3.Instance = TIM3;
  htim3.Init.Prescaler = 0;
  htim3.Init.CounterMode = TIM_COUNTERMODE_CENTERALIGNED1;
  htim3.Init.Period = 5249;
  htim3.Init.ClockDivision = TIM_CLOCKDIVISION_DIV1;
  htim3.Init.AutoReloadPreload = TIM_AUTORELOAD_PRELOAD_ENABLE;
  if (HAL_TIM_Base_Init(&htim3) != HAL_OK)
  {
    Error_Handler();
  }
  if (HAL_TIM_PWM_Init(&htim3) != HAL_OK)
  {
    Error_Handler();
  }
  sSlaveConfig.SlaveMode = TIM_SLAVEMODE_TRIGGER;
  sSlaveConfig.InputTrigger = TIM_TS_ITR0;
  if (HAL_TIM_SlaveConfigSynchro(&htim3, &sSlaveConfig) != HAL_OK)
  {
    Error_Handler();
  }
  sMasterConfig.MasterOutputTrigger = TIM_TRGO_RESET;
  sMasterConfig.MasterSlaveMode = TIM_MASTERSLAVEMODE_DISABLE;
  if (HAL_TIMEx_MasterConfigSynchronization(&htim3, &sMasterConfig) != HAL_OK)
  {
    Error_Handler();
  }
  sConfigOC.OCMode = TIM_OCMODE_PWM1;
  sConfigOC.Pulse = 0;
  sConfigOC.OCPolarity = TIM_OCPOLARITY_HIGH;
  sConfigOC.OCFastMode = TIM_OCFAST_DISABLE;
  if (HAL_TIM_PWM_ConfigChannel(&htim3, &sConfigOC, TIM_CHANNEL_1) != HAL_OK)
  {
    Error_Handler();
  }
  sConfigOC.OCMode = TIM_OCMODE_PWM2;
  if (HAL_TIM_PWM_ConfigChannel(&htim3, &sConfigOC, TIM_CHANNEL_2) != HAL_OK)
  {
    Error_Handler();
  }
  HAL_TIM_MspPostInit(&htim3);

}

static void MX_GPIO_Init(void)
{
  GPIO_InitTypeDef GPIO_InitStruct = {0};

  /* GPIO Ports Clock Enable */
  __HAL_RCC_GPIOC_CLK_ENABLE();
  __HAL_RCC_GPIOD_CLK_ENABLE();
  __HAL_RCC_GPIOA_CLK_ENABLE();
  __HAL_RCC_GPIOB_CLK_ENABLE();

  /*Configure GPIO pin Output Level */
  HAL_GPIO_WritePin(GPIOC, GPIO_PIN_13, GPIO_PIN_RESET);

  /*Configure GPIO pin : PC13 */
  GPIO_InitStruct.Pin = GPIO_PIN_13;
  GPIO_InitStruct.Mode = GPIO_MODE_OUTPUT_PP;
  GPIO_InitStruct.Pull = GPIO_NOPULL;
  GPIO_InitStruct.Speed = GPIO_SPEED_FREQ_LOW;
  HAL_GPIO_Init(GPIOC, &GPIO_InitStruct);

  /*Configure GPIO pins : PB3 PB4 PB5 PB6 */
  GPIO_InitStruct.Pin = GPIO_PIN_3|GPIO_PIN_4|GPIO_PIN_5;// GPIO_PIN_6
  GPIO_InitStruct.Mode = GPIO_MODE_INPUT;
  GPIO_InitStruct.Pull = GPIO_PULLDOWN;
  HAL_GPIO_Init(GPIOB, &GPIO_InitStruct);

}

void Error_Handler(void)
{
  __disable_irq();
  while (1)
  {
  }
}
